VERSION ""

NS_ :

BS_:

BU_: GW HC AVP IDC_L3 LMU PIS RRR SRR_L SRR_R Tester RSDS_L RSDS_R FR IFC AVP_HAP_PAS CR_L CR_R IFC_IDC_L2 IDC_L2 FR_IDC_L2 AVP_HAP HAP HAP_PAS IDC_L2_IDC_L3 PAS

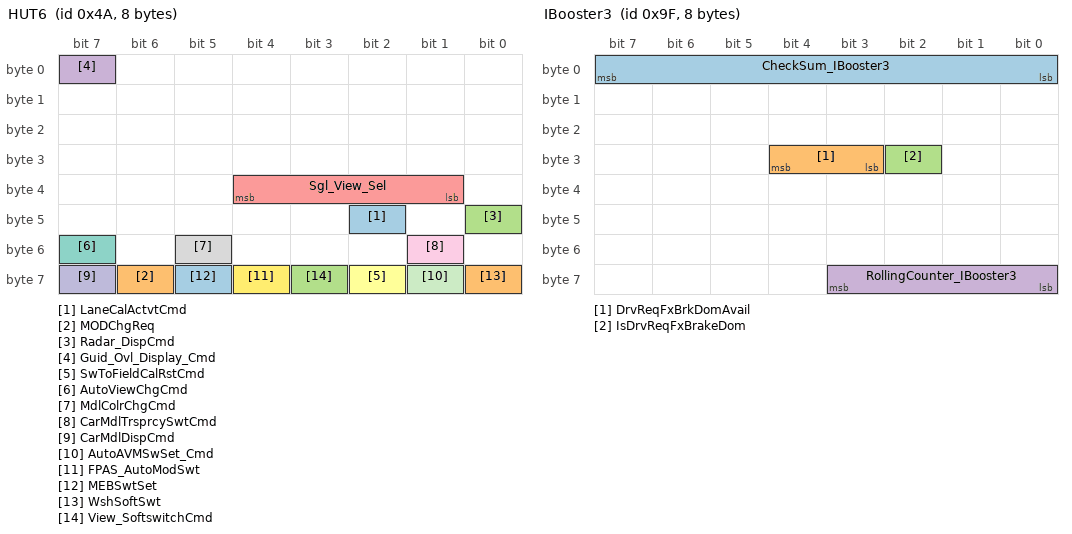
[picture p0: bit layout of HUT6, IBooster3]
BO_ 74 HUT6: 8 GW
 SG_ LaneCalActvtCmd : 42|1@0+ (1,0) [0|1] ""  AVP,HAP,PAS
 SG_ MODChgReq : 62|1@0+ (1,0) [0|1] ""  AVP,HAP,PAS
 SG_ Radar_DispCmd : 40|1@0+ (1,0) [0|1] ""  AVP,HAP,PAS
 SG_ Guid_Ovl_Display_Cmd : 7|1@0+ (1,0) [0|1] ""  AVP,HAP,PAS
 SG_ Sgl_View_Sel : 36|4@0+ (1,0) [0|15] ""  AVP,HAP,PAS
 SG_ SwToFieldCalRstCmd : 58|1@0+ (1,0) [0|1] ""  AVP,HAP,PAS
 SG_ AutoViewChgCmd : 55|1@0+ (1,0) [0|1] ""  AVP,HAP,PAS
 SG_ MdlColrChgCmd : 53|1@0+ (1,0) [0|1] ""  AVP,HAP,PAS
 SG_ CarMdlTrsprcySwtCmd : 49|1@0+ (1,0) [0|1] ""  AVP,HAP,PAS
 SG_ CarMdlDispCmd : 63|1@0+ (1,0) [0|1] ""  AVP,HAP,PAS
 SG_ AutoAVMSwSet_Cmd : 57|1@0+ (1,0) [0|1] ""  AVP,HAP,PAS
 SG_ FPAS_AutoModSwt : 60|1@0+ (1,0) [0|1] ""  AVP,HAP,PAS
 SG_ MEBSwtSet : 61|1@0+ (1,0) [0|1] ""  AVP,HAP,PAS
 SG_ WshSoftSwt : 56|1@0+ (1,0) [0|1] ""  AVP,HAP,PAS
 SG_ View_SoftswitchCmd : 59|1@0+ (1,0) [0|1] ""  AVP,HAP,PAS

BO_ 96 HCU_FD1: 64 GW
 SG_ Checksum_HCU_PT1 : 71|8@0+ (1,0) [0|255] ""  IFC,FR,IDC_L2,IDC_L3
 SG_ HCU_BrkPedalSts : 87|2@0+ (1,0) [0|3] ""  IFC,AVP,HAP,IDC_L2,IDC_L3
 SG_ HCU_BrkPedalStsValid : 84|1@0+ (1,0) [0|1] ""  IFC,AVP,HAP,IDC_L2,IDC_L3
 SG_ HCU_AccelPedalPosn_Diag : 79|8@0+ (0.3937,0) [0|100.395] "%"  IFC,FR,RSDS_R,RSDS_L,AVP,HAP,PAS,CR_L,CR_R,IDC_L2,IDC_L3
 SG_ HCU_AccelPedalPosn_DiagValid : 85|1@0+ (1,0) [0|1] ""  FR,RSDS_R,RSDS_L,AVP,HAP,PAS,CR_L,CR_R,IDC_L2,IDC_L3
 SG_ ActWheelTrqDmd : 83|12@0+ (5,-6000) [-6000|14475] "Nm"  FR,IDC_L2,IDC_L3
 SG_ RollingCounter_HCU_PT1 : 123|4@0+ (1,0) [0|15] ""  IFC,FR,IDC_L2,IDC_L3
 SG_ Checksum_HCU_PT9 : 135|8@0+ (1,0) [0|255] ""  FR,IDC_L2,IDC_L3
 SG_ MaxPsblWheelTrq : 143|10@0+ (20,-6000) [-6000|14460] "Nm"  FR,IDC_L2,IDC_L3
 SG_ TotWheelTrq : 147|12@0+ (5,-6000) [-6000|14475] "Nm"  FR,AVP,HAP,IDC_L2,IDC_L3
 SG_ TotWheelTrqVld : 171|1@0+ (1,0) [0|1] ""  IFC,FR,IDC_L2,IDC_L3
 SG_ MinPsblWheelTrq : 167|10@0+ (20,-6000) [-6000|14460] "Nm"  FR,IDC_L2,IDC_L3
 SG_ HCU_ACCInterface : 170|1@0+ (1,0) [0|1] ""  FR,IDC_L2
 SG_ RollingCounter_HCU_PT9 : 187|4@0+ (1,0) [0|15] ""  FR,IDC_L2,IDC_L3
 SG_ HCU_PowertrainSts : 303|5@0+ (1,0) [0|31] ""  IFC,FR,RSDS_R,RSDS_L,AVP,HAP,PAS,CR_L,CR_R,IDC_L2,IDC_L3
 SG_ HCU_HWPInterface : 337|1@0+ (1,0) [0|1] ""  IDC_L3
 SG_ HCU_RespHWP : 336|1@0+ (1,0) [0|1] ""  IDC_L3
 SG_ FreshnessValue_HCU_FD1 : 455|16@0+ (1,0) [0|65535] ""  FR,AVP,HAP,IDC_L2,IDC_L3
 SG_ MAC_Check_HCU_FD1 : 471|48@0+ (1,0) [0|281474976710655] ""  FR,AVP,HAP,IDC_L2,IDC_L3

BO_ 121 ECM_FD1: 64 GW
 SG_ FreshnessValue_ECM_FD1 : 455|16@0+ (1,0) [0|65535] ""  FR,AVP,HAP,IDC_L2,IDC_L3
 SG_ MAC_Check_ECM_FD1 : 471|48@0+ (1,0) [0|281474976710655] ""  FR,AVP,HAP,IDC_L2,IDC_L3

BO_ 159 IBooster3: 8 GW
 SG_ CheckSum_IBooster3 : 7|8@0+ (1,0) [0|255] ""  IDC_L2,IDC_L3
 SG_ DrvReqFxBrkDomAvail : 28|2@0+ (1,0) [0|2] ""  IDC_L2,IDC_L3
 SG_ IsDrvReqFxBrakeDom : 26|1@0+ (1,0) [0|1] ""  IDC_L2,IDC_L3
 SG_ RollingCounter_IBooster3 : 59|4@0+ (1,0) [0|15] ""  IDC_L2,IDC_L3

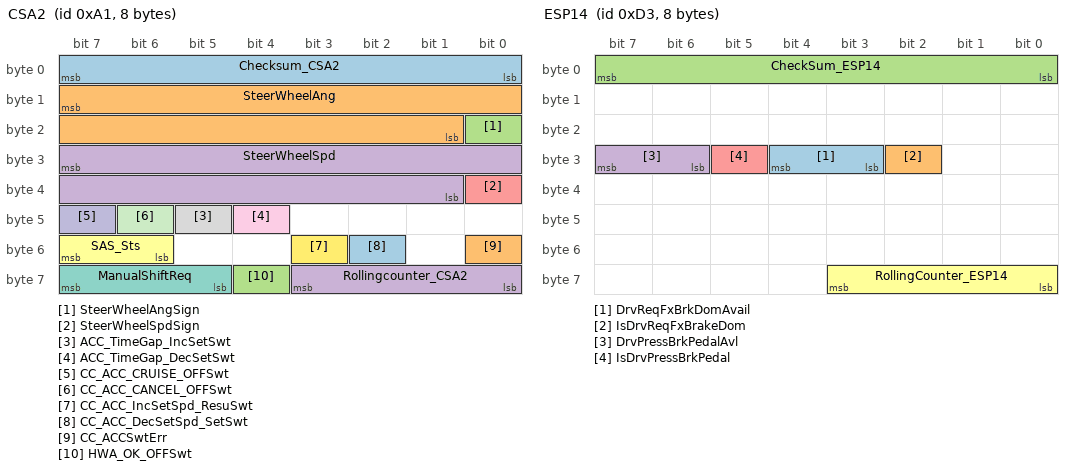
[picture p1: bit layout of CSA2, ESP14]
BO_ 161 CSA2: 8 GW
 SG_ Checksum_CSA2 : 7|8@0+ (1,0) [0|255] ""  IFC,FR,RSDS_R,RSDS_L,AVP,HAP,PAS,CR_L,CR_R,IDC_L2,IDC_L3,LMU
 SG_ SteerWheelAng : 15|15@0+ (0.1,0) [0|780] "deg"  IFC,HC,FR,RSDS_R,RSDS_L,AVP,HAP,PAS,CR_L,CR_R,IDC_L2,IDC_L3,LMU
 SG_ SteerWheelAngSign : 16|1@0+ (1,0) [0|1] ""  IFC,HC,FR,RSDS_R,RSDS_L,AVP,HAP,PAS,CR_L,CR_R,IDC_L2,IDC_L3,LMU
 SG_ SteerWheelSpd : 31|15@0+ (0.1,0) [0|1016] "deg/s"  IFC,FR,RSDS_R,RSDS_L,AVP,HAP,PAS,CR_L,CR_R,IDC_L2,IDC_L3,LMU
 SG_ SteerWheelSpdSign : 32|1@0+ (1,0) [0|1] ""  IFC,FR,RSDS_R,RSDS_L,AVP,HAP,PAS,CR_L,CR_R,IDC_L2,IDC_L3,LMU
 SG_ SAS_Sts : 55|2@0+ (1,0) [0|3] ""  IFC,FR,RSDS_R,RSDS_L,AVP,HAP,PAS,CR_L,CR_R,IDC_L2,IDC_L3
 SG_ ManualShiftReq : 63|3@0+ (1,0) [0|7] ""  IDC_L3
 SG_ ACC_TimeGap_IncSetSwt : 45|1@0+ (1,0) [0|1] ""  FR,IDC_L2
 SG_ ACC_TimeGap_DecSetSwt : 44|1@0+ (1,0) [0|1] ""  FR,IDC_L2
 SG_ CC_ACC_CRUISE_OFFSwt : 47|1@0+ (1,0) [0|1] ""  FR,IDC_L2
 SG_ CC_ACC_CANCEL_OFFSwt : 46|1@0+ (1,0) [0|1] ""  FR,IDC_L2
 SG_ CC_ACC_IncSetSpd_ResuSwt : 51|1@0+ (1,0) [0|1] ""  FR,IDC_L2,IDC_L3
 SG_ CC_ACC_DecSetSpd_SetSwt : 50|1@0+ (1,0) [0|1] ""  FR,IDC_L2,IDC_L3
 SG_ CC_ACCSwtErr : 48|1@0+ (1,0) [0|1] ""  FR,IDC_L2
 SG_ HWA_OK_OFFSwt : 60|1@0+ (1,0) [0|1] ""  FR,IDC_L2,IDC_L3
 SG_ Rollingcounter_CSA2 : 59|4@0+ (1,0) [0|15] ""  IFC,FR,RSDS_R,RSDS_L,AVP,HAP,PAS,CR_L,CR_R,IDC_L2,IDC_L3,LMU

BO_ 211 ESP14: 8 GW
 SG_ DrvReqFxBrkDomAvail : 28|2@0+ (1,0) [0|2] ""  IDC_L2,IDC_L3
 SG_ IsDrvReqFxBrakeDom : 26|1@0+ (1,0) [0|1] ""  IDC_L2,IDC_L3
 SG_ CheckSum_ESP14 : 7|8@0+ (1,0) [0|255] ""  IDC_L2,IDC_L3
 SG_ DrvPressBrkPedalAvl : 31|2@0+ (1,0) [0|2] ""  IDC_L2,IDC_L3
 SG_ IsDrvPressBrkPedal : 29|1@0+ (1,0) [0|1] ""  IDC_L2,IDC_L3
 SG_ RollingCounter_ESP14 : 59|4@0+ (1,0) [0|15] ""  IDC_L2,IDC_L3

BO_ 259 ECM_FD2: 64 GW
 SG_ EngState_PHEV : 351|3@0+ (1,0) [0|7] ""  FR,RSDS_R,RSDS_L,CR_L,CR_R,IDC_L2,IDC_L3
 SG_ FreshnessValue_ECM_FD2 : 455|16@0+ (1,0) [0|65535] ""  FR,IDC_L2,IDC_L3
 SG_ MAC_Check_ECM_FD2 : 471|48@0+ (1,0) [0|281474976710655] ""  FR,IDC_L2,IDC_L3

BO_ 273 ECM1: 8 GW
 SG_ EngSpd : 47|16@0+ (0.125,0) [0|8191.875] "rpm"  IFC,HC,FR,RSDS_R,RSDS_L,AVP,HAP,PAS,CR_L,CR_R,IDC_L2,IDC_L3,LMU
 SG_ EngSpdVldty : 63|2@0+ (1,0) [0|2] ""  IFC,HC,FR,RSDS_R,RSDS_L,AVP,HAP,PAS,CR_L,CR_R,IDC_L2,IDC_L3,LMU

BO_ 288 IBooster_FD2: 64 GW
 SG_ IB_BrkPedalAppld : 11|1@0+ (1,0) [0|1] ""  FR,RSDS_R,RSDS_L,AVP,HAP,CR_L,CR_R,IDC_L2
 SG_ IB_BrkPedalAppldVld : 10|2@0+ (1,0) [0|3] ""  FR,RSDS_R,RSDS_L,AVP,HAP,CR_L,CR_R,IDC_L2
 SG_ CheckSum_ABS1 : 135|8@0+ (1,0) [0|255] ""  IDC_L2,IDC_L3
 SG_ FRWheelDriveDirection : 159|2@0+ (1,0) [0|3] ""  IDC_L2,IDC_L3
 SG_ FRWheelSpdVld : 157|1@0+ (1,0) [0|1] ""  IDC_L2,IDC_L3
 SG_ FRWheelSpd : 156|13@0+ (0.05625,0) [0|299.98125] "km/h"  IDC_L2,IDC_L3
 SG_ WssFLEdgesSum : 175|8@0+ (1,0) [0|255] ""  IDC_L2,IDC_L3
 SG_ WssFREdgesSum : 183|8@0+ (1,0) [0|255] ""  IDC_L2,IDC_L3
 SG_ WssFLEdgesSumVld : 191|1@0+ (1,0) [0|1] ""  IDC_L2,IDC_L3
 SG_ WssFREdgesSumVld : 190|1@0+ (1,0) [0|1] ""  IDC_L2,IDC_L3
 SG_ RollingCounter_ABS1 : 187|4@0+ (1,0) [0|15] ""  IDC_L2,IDC_L3
 SG_ CheckSum_ABS3 : 199|8@0+ (1,0) [0|255] ""  IDC_L2,IDC_L3
 SG_ RollingCounter_ABS3 : 251|4@0+ (1,0) [0|15] ""  IDC_L2,IDC_L3
 SG_ CheckSum_IBooster_FD2_5 : 263|8@0+ (1,0) [0|255] ""  IDC_L2,IDC_L3
 SG_ VLC_IntTartAccel : 279|12@0+ (0.0125,-16) [-16|16] ""  IDC_L2,IDC_L3
 SG_ L3VLCADactive : 271|1@0+ (1,0) [0|1] ""  IDC_L2,IDC_L3
 SG_ L3mainVMCavailiable : 270|2@0+ (1,0) [0|3] ""  IDC_L2,IDC_L3
 SG_ RollingCounter_Booster_FD2_5 : 315|4@0+ (1,0) [0|15] ""  IDC_L2,IDC_L3
 SG_ CheckSum_ABS2 : 327|8@0+ (1,0) [0|255] ""  IDC_L2,IDC_L3
 SG_ WssRREdgesSum : 367|8@0+ (1,0) [0|255] ""  IDC_L2,IDC_L3
 SG_ WssRLEdgesSum : 375|8@0+ (1,0) [0|255] ""  IDC_L2,IDC_L3
 SG_ WssRLEdgesSumVld : 383|1@0+ (1,0) [0|1] ""  IDC_L2,IDC_L3
 SG_ WssRREdgesSumVld : 382|1@0+ (1,0) [0|1] ""  IDC_L2,IDC_L3
 SG_ RollingCounter_ABS2 : 379|4@0+ (1,0) [0|15] ""  IDC_L2,IDC_L3
 SG_ FreshnessValue_IBooster_FD2 : 455|16@0+ (1,0) [0|65535] ""  IDC_L3
 SG_ MAC_Check_IBooster_FD2 : 471|48@0+ (1,0) [0|281474976710655] ""  IDC_L3

BO_ 299 IFC_FD1: 64 IFC_IDC_L2
 SG_ Checksum_IFC1 : 71|8@0+ (1,0) [0|255] ""  GW
 SG_ IFCTrqOvlCmdProtnValue : 79|14@0+ (1,0) [0|16383] ""  GW
 SG_ IFCTrqOvlCmdReqValue : 103|11@0+ (0.01,-10.23) [-10.23|10.24] "Nm"  GW
 SG_ IFCFuncTrqCmdReqFlag : 127|3@0+ (1,0) [0|7] ""  GW
 SG_ IFCVibrationWarning : 105|2@0+ (1,0) [0|3] ""  GW
 SG_ RollingCounter_IFC1 : 123|4@0+ (1,0) [0|15] ""  GW
 SG_ Checksum_IFC2 : 135|8@0+ (1,0) [0|255] ""  GW
 SG_ IFCAngCmdReqValue : 143|14@0+ (0.1,-780) [-780|780] "°"  GW
 SG_ IFCAngCmdReqProtnValue : 159|14@0+ (1,0) [0|16383] "" Vector__XXX
 SG_ IFCFuncAngCmdReqFlag : 175|3@0+ (1,0) [0|7] ""  GW
 SG_ RollingCounter_IFC2 : 187|4@0+ (1,0) [0|15] ""  GW

BO_ 303 HCU_FD3: 64 GW
 SG_ Checksum_HCU_PT5 : 71|8@0+ (1,0) [0|255] ""  FR,IDC_L2,IDC_L3
 SG_ HCU_DrvMod : 79|4@0+ (1,0) [0|15] ""  FR,AVP,HAP,IDC_L2,IDC_L3
 SG_ HCU_PTDrvMod : 75|3@0+ (1,0) [0|7] ""  FR,IDC_L2,IDC_L3
 SG_ DrvTrqReqOvld : 87|2@0+ (1,0) [0|3] ""  FR,IDC_L2,IDC_L3
 SG_ RollingCounter_HCU_PT5 : 123|4@0+ (1,0) [0|15] ""  FR,IDC_L2,IDC_L3
 SG_ HCU_GearSts : 164|4@0+ (1,0) [0|15] ""  IFC,HC,FR,RSDS_R,RSDS_L,AVP,HAP,PAS,CR_L,CR_R,IDC_L2
 SG_ HCU_APS_Available : 188|1@0+ (1,0) [0|1] ""  AVP,HAP
 SG_ HCU_FltLvl : 158|2@0+ (1,0) [0|2] ""  IDC_L2,IDC_L3
 SG_ HCU_VehSpdLimit : 215|8@0+ (2,0) [0|510] "km/h"  IDC_L3
 SG_ FreshnessValue_HCU_FD3 : 455|16@0+ (1,0) [0|65535] ""  FR,IDC_L2,IDC_L3
 SG_ MAC_Check_HCU_FD3 : 471|48@0+ (1,0) [0|281474976710655] ""  FR,IDC_L2,IDC_L3

BO_ 311 ESP_FD2: 64 GW
 SG_ VehStandstill : 78|2@0+ (1,0) [0|3] ""  FR,RSDS_R,RSDS_L,AVP,HAP,PAS,CR_L,CR_R,IDC_L2,IDC_L3
 SG_ EngTrqReq : 231|16@0+ (1,-3000) [-3000|5000] "Nm"  AVP,HAP
 SG_ CheckSum_ABS3 : 327|8@0+ (1,0) [0|255] ""  IFC,FR,RSDS_R,RSDS_L,AVP,HAP,PAS,CR_L,CR_R,IDC_L2,IDC_L3,PIS,LMU
 SG_ VehSpdVld : 333|1@0+ (1,0) [0|1] ""  IFC,HC,FR,RSDS_R,RSDS_L,AVP,HAP,PAS,CR_L,CR_R,IDC_L2,IDC_L3,PIS,LMU
 SG_ VehSpd : 332|13@0+ (0.05625,0) [0|299.98125] "kph"  IFC,HC,FR,RSDS_R,RSDS_L,AVP,HAP,PAS,CR_L,CR_R,IDC_L2,IDC_L3,PIS,LMU
 SG_ RollingCounter_ABS3 : 379|4@0+ (1,0) [0|15] ""  IFC,FR,RSDS_R,RSDS_L,AVP,HAP,PAS,CR_L,CR_R,IDC_L2,IDC_L3,PIS,LMU
 SG_ CheckSum_ESP_FD2_1 : 7|8@0+ (1,0) [0|255] ""  FR,IDC_L2,IDC_L3
 SG_ L12VLCADactive : 63|1@0+ (1,0) [0|1] ""  FR,IDC_L2,IDC_L3
 SG_ L12mainVMCavailiable : 62|1@0+ (1,0) [0|1] ""  FR,IDC_L2,IDC_L3
 SG_ RollingCounter_ESP_FD2_1 : 59|4@0+ (1,0) [0|15] ""  FR,IDC_L2,IDC_L3
 SG_ CheckSum_ESP2 : 71|8@0+ (1,0) [0|255] ""  FR,AVP,HAP,PAS,IDC_L2,IDC_L3
 SG_ CDPActv : 103|1@0+ (1,0) [0|1] ""  IDC_L2,IDC_L3
 SG_ ESP_DiagActv : 73|1@0+ (1,0) [0|1] ""  IFC,FR,RSDS_R,RSDS_L,HAP,CR_L,CR_R,IDC_L2,IDC_L3
 SG_ BrkDskOvrheatd : 75|1@0+ (1,0) [0|1] ""  FR,CR_L,CR_R,IDC_L2,IDC_L3
 SG_ NoBrkForce : 76|1@0+ (1,0) [0|1] ""  FR,RSDS_R,RSDS_L,CR_L,CR_R,IDC_L2,IDC_L3
 SG_ AEBIBActv : 81|1@0+ (1,0) [0|1] ""  FR,RSDS_R,RSDS_L,HAP,PAS,CR_L,CR_R,IDC_L2,IDC_L3
 SG_ AEBBAActv : 82|1@0+ (1,0) [0|1] ""  FR,RSDS_R,RSDS_L,HAP,PAS,CR_L,CR_R,IDC_L2,IDC_L3
 SG_ AEBAvailable : 83|1@0+ (1,0) [0|1] ""  FR,CR_L,CR_R,IDC_L2,IDC_L3
 SG_ ABPAvailable : 84|1@0+ (1,0) [0|1] ""  FR,CR_L,CR_R,IDC_L2,IDC_L3
 SG_ ABPActv : 85|1@0+ (1,0) [0|1] ""  FR,CR_L,CR_R,IDC_L2,IDC_L3
 SG_ ABAavailable : 86|1@0+ (1,0) [0|1] ""  FR,CR_L,CR_R,IDC_L2,IDC_L3
 SG_ ABAactv : 87|1@0+ (1,0) [0|1] ""  FR,CR_L,CR_R,IDC_L2,IDC_L3
 SG_ HDCCtrl : 91|2@0+ (1,0) [0|2] ""  FR,RSDS_R,RSDS_L,CR_L,CR_R,IDC_L2,IDC_L3
 SG_ CDDActv : 92|1@0+ (1,0) [0|1] ""  FR,IDC_L2,IDC_L3
 SG_ CDDAvailable : 93|1@0+ (1,0) [0|1] ""  FR,IDC_L2,IDC_L3
 SG_ AWBAvailable : 94|1@0+ (1,0) [0|1] ""  FR,IDC_L2,IDC_L3
 SG_ AWBActv : 95|1@0+ (1,0) [0|1] ""  FR,IDC_L2,IDC_L3
 SG_ AVHErrSts : 99|2@0+ (1,0) [0|3] ""  HAP,PAS
 SG_ AVHSts : 101|2@0+ (1,0) [0|2] ""  FR,HAP,PAS,IDC_L2,IDC_L3
 SG_ CTABrkAvailable : 74|1@0+ (1,0) [0|1] ""  RSDS_R,RSDS_L
 SG_ RollingCounter_ESP2 : 123|4@0+ (1,0) [0|15] ""  FR,AVP,HAP,PAS,IDC_L2,IDC_L3
 SG_ CheckSum_ESP1 : 135|8@0+ (1,0) [0|255] ""  IFC,FR,RSDS_R,RSDS_L,AVP,HAP,CR_L,CR_R,IDC_L2,IDC_L3
 SG_ ESPFuncOffSts : 140|1@0+ (1,0) [0|1] ""  IFC,FR,RSDS_R,RSDS_L,AVP,HAP,CR_L,CR_R,IDC_L2,IDC_L3
 SG_ ESPBrkLmpCtrl : 142|1@0+ (1,0) [0|1] ""  FR,IDC_L2,IDC_L3
 SG_ ESPFailSts : 143|1@0+ (1,0) [0|1] ""  IFC,FR,RSDS_R,RSDS_L,HAP,CR_L,CR_R,IDC_L2,IDC_L3
 SG_ ESP_MasterCylBrkPressVld : 144|1@0+ (1,0) [0|1] ""  IFC,FR,RSDS_R,RSDS_L,AVP,HAP,CR_L,CR_R,IDC_L2,IDC_L3
 SG_ MSRActv : 149|1@0+ (1,0) [0|1] ""  IFC,FR,RSDS_R,RSDS_L,CR_L,CR_R,IDC_L2,IDC_L3
 SG_ VDCActv : 148|1@0+ (1,0) [0|1] ""  IFC,FR,RSDS_R,RSDS_L,AVP,HAP,CR_L,CR_R,IDC_L2,IDC_L3
 SG_ PTCActv : 150|1@0+ (1,0) [0|1] ""  IFC,FR,RSDS_R,RSDS_L,AVP,HAP,CR_L,CR_R,IDC_L2,IDC_L3
 SG_ BTCActv : 151|1@0+ (1,0) [0|1] ""  IFC,FR,RSDS_R,RSDS_L,AVP,HAP,CR_L,CR_R,IDC_L2,IDC_L3
 SG_ ESP_MasterCylBrkPress : 159|16@0+ (0.03125,-42.5) [-42.5|425] "bar"  IFC,FR,RSDS_R,RSDS_L,AVP,HAP,CR_L,CR_R,IDC_L2,IDC_L3
 SG_ MSRActv_RA : 174|1@0+ (1,0) [0|1] ""  IFC,FR,RSDS_R,RSDS_L,CR_L,CR_R,IDC_L2,IDC_L3
 SG_ PTCActv_RA : 136|1@0+ (1,0) [0|1] ""  IFC,FR,RSDS_R,RSDS_L,CR_L,CR_R,IDC_L2,IDC_L3
 SG_ BTCActv_RA : 137|1@0+ (1,0) [0|1] ""  IFC,FR,RSDS_R,RSDS_L,CR_L,CR_R,IDC_L2,IDC_L3
 SG_ RollingCounter_ESP1 : 187|4@0+ (1,0) [0|15] ""  IFC,FR,RSDS_R,RSDS_L,AVP,HAP,CR_L,CR_R,IDC_L2,IDC_L3
 SG_ CheckSum_ESP7 : 199|8@0+ (1,0) [0|255] ""  AVP,HAP,PAS
 SG_ ESP_MEBBrkAvail : 209|1@0+ (1,0) [0|1] ""  HAP,PAS
 SG_ LgtCtrlrAvail : 255|3@0+ (1,0) [0|7] ""  HAP
 SG_ LgtCtrlrFailr : 220|3@0+ (1,0) [0|7] ""  HAP
 SG_ LgtCtrlrSts : 223|3@0+ (1,0) [0|7] ""  HAP
 SG_ FourWhlsBrkTrq : 207|14@0+ (1,0) [0|16383] ""  AVP,HAP,PAS
 SG_ APS_EngTrqReqEna : 247|1@0+ (1,0) [0|1] ""  AVP,HAP
 SG_ RollingCounter_ESP7 : 251|4@0+ (1,0) [0|15] ""  HAP,PAS
 SG_ ABSFailSts : 335|1@0+ (1,0) [0|1] ""  IFC,FR,AVP,HAP,PAS,IDC_L2,IDC_L3
 SG_ EBDFailSts : 334|1@0+ (1,0) [0|1] ""  IFC,FR,AVP,HAP,IDC_L2,IDC_L3
 SG_ EBDActv : 351|1@0+ (1,0) [0|1] ""  AVP,HAP
 SG_ ABSActv : 347|1@0+ (1,0) [0|1] ""  IFC,FR,RSDS_R,RSDS_L,AVP,HAP,PAS,CR_L,CR_R,IDC_L2,IDC_L3
 SG_ FreshnessValue_ESP_FD2 : 455|16@0+ (1,0) [0|65535] ""  AVP,HAP,IDC_L2,IDC_L3
 SG_ MAC_Check_ESP_FD2 : 471|48@0+ (1,0) [0|281474976710655] ""  AVP,HAP,IDC_L2,IDC_L3

BO_ 315 ESP_FD3: 64 GW
 SG_ L3VLCADactive : 422|1@0+ (1,0) [0|1] ""  IDC_L2,IDC_L3
 SG_ L3mainVMCavailiable : 421|2@0+ (1,0) [0|3] ""  IDC_L2,IDC_L3
 SG_ CheckSum_ABS1 : 7|8@0+ (1,0) [0|255] ""  IFC,FR,RSDS_R,RSDS_L,AVP,HAP,PAS,CR_L,CR_R,IDC_L2,IDC_L3,LMU
 SG_ FLWheelDriveDirection : 15|2@0+ (1,0) [0|3] ""  IFC,FR,RSDS_R,RSDS_L,AVP,HAP,PAS,CR_L,CR_R,IDC_L2,IDC_L3
 SG_ FLWheelSpdVld : 13|1@0+ (1,0) [0|1] ""  IFC,FR,RSDS_R,RSDS_L,AVP,HAP,PAS,CR_L,CR_R,IDC_L2,IDC_L3,LMU
 SG_ FLWheelSpd : 12|13@0+ (0.05625,0) [0|299.98125] "km/h"  IFC,FR,RSDS_R,RSDS_L,AVP,HAP,PAS,CR_L,CR_R,IDC_L2,IDC_L3,LMU
 SG_ FRWheelDriveDirection : 31|2@0+ (1,0) [0|3] ""  IFC,FR,RSDS_R,RSDS_L,AVP,HAP,PAS,CR_L,CR_R,IDC_L2,IDC_L3
 SG_ FRWheelSpdVld : 29|1@0+ (1,0) [0|1] ""  IFC,FR,RSDS_R,RSDS_L,AVP,HAP,PAS,CR_L,CR_R,IDC_L2,IDC_L3,LMU
 SG_ FRWheelSpd : 28|13@0+ (0.05625,0) [0|299.98125] "km/h"  IFC,FR,RSDS_R,RSDS_L,AVP,HAP,PAS,CR_L,CR_R,IDC_L2,IDC_L3,LMU
 SG_ WssFLEdgesSum : 47|8@0+ (1,0) [0|255] ""  FR,AVP,HAP,PAS,IDC_L2,IDC_L3,LMU
 SG_ WssFREdgesSum : 55|8@0+ (1,0) [0|255] ""  FR,AVP,HAP,PAS,IDC_L2,IDC_L3,LMU
 SG_ WssFLEdgesSumVld : 63|1@0+ (1,0) [0|1] ""  FR,AVP,HAP,PAS,IDC_L2,IDC_L3,LMU
 SG_ WssFREdgesSumVld : 62|1@0+ (1,0) [0|1] ""  FR,AVP,HAP,PAS,IDC_L2,IDC_L3,LMU
 SG_ RollingCounter_ABS1 : 59|4@0+ (1,0) [0|15] ""  IFC,FR,RSDS_R,RSDS_L,AVP,HAP,PAS,CR_L,CR_R,IDC_L2,IDC_L3,LMU
 SG_ CheckSum_ABS2 : 327|8@0+ (1,0) [0|255] ""  IFC,FR,RSDS_R,RSDS_L,AVP,HAP,PAS,CR_L,CR_R,IDC_L2,IDC_L3,LMU
 SG_ RLWheelDriveDirection : 335|2@0+ (1,0) [0|3] ""  IFC,FR,RSDS_R,RSDS_L,AVP,HAP,PAS,CR_L,CR_R,IDC_L2,IDC_L3
 SG_ RLWheelSpdVld : 333|1@0+ (1,0) [0|1] ""  IFC,FR,RSDS_R,RSDS_L,AVP,HAP,PAS,CR_L,CR_R,IDC_L2,IDC_L3,LMU
 SG_ RLWheelSpd : 332|13@0+ (0.05625,0) [0|299.98125] "km/h"  IFC,FR,RSDS_R,RSDS_L,AVP,HAP,PAS,CR_L,CR_R,IDC_L2,IDC_L3,LMU
 SG_ RRWheelDriveDirection : 351|2@0+ (1,0) [0|3] ""  IFC,FR,RSDS_R,RSDS_L,AVP,HAP,PAS,CR_L,CR_R,IDC_L2,IDC_L3
 SG_ RRWheelSpdVld : 349|1@0+ (1,0) [0|1] ""  IFC,FR,RSDS_R,RSDS_L,AVP,HAP,PAS,CR_L,CR_R,IDC_L2,IDC_L3,LMU
 SG_ RRWheelSpd : 348|13@0+ (0.05625,0) [0|299.98125] "km/h"  IFC,FR,RSDS_R,RSDS_L,AVP,HAP,PAS,CR_L,CR_R,IDC_L2,IDC_L3,LMU
 SG_ WssRREdgesSum : 367|8@0+ (1,0) [0|255] ""  FR,AVP,HAP,PAS,IDC_L2,IDC_L3,LMU
 SG_ WssRLEdgesSum : 375|8@0+ (1,0) [0|255] ""  FR,AVP,HAP,PAS,IDC_L2,IDC_L3,LMU
 SG_ WssRLEdgesSumVld : 383|1@0+ (1,0) [0|1] ""  FR,AVP,HAP,PAS,IDC_L2,IDC_L3,LMU
 SG_ WssRREdgesSumVld : 382|1@0+ (1,0) [0|1] ""  FR,AVP,HAP,PAS,IDC_L2,IDC_L3,LMU
 SG_ RollingCounter_ABS2 : 379|4@0+ (1,0) [0|15] ""  IFC,FR,RSDS_R,RSDS_L,AVP,HAP,PAS,CR_L,CR_R,IDC_L2,IDC_L3,LMU
 SG_ VLC_IntTartAccel : 431|12@0+ (0.0125,-16) [-16|16] ""  IDC_L2,IDC_L3
 SG_ CheckSum_EPB1 : 71|8@0+ (1,0) [0|255] ""  FR,AVP,HAP,PAS,IDC_L2,IDC_L3
 SG_ ESP_DSTSts : 116|3@0+ (1,0) [0|7] ""  IDC_L2,IDC_L3
 SG_ EPB_SwtPosnVld : 80|1@0+ (1,0) [0|1] ""  FR,AVP,HAP,PAS,IDC_L2,IDC_L3
 SG_ EPBErrSts : 91|2@0+ (1,0) [0|3] ""  FR,RSDS_R,RSDS_L,AVP,HAP,PAS,CR_L,CR_R,IDC_L2,IDC_L3
 SG_ EPBSts : 93|2@0+ (1,0) [0|3] ""  FR,RSDS_R,RSDS_L,AVP,HAP,PAS,CR_L,CR_R,IDC_L2,IDC_L3
 SG_ EPB_SwtPosn : 95|2@0+ (1,0) [0|3] ""  FR,AVP,HAP,PAS,IDC_L2,IDC_L3
 SG_ RollingCounter_EPB1 : 123|4@0+ (1,0) [0|15] ""  FR,AVP,HAP,PAS,IDC_L2,IDC_L3
 SG_ CheckSum_ESP_FD3_7 : 391|8@0+ (1,0) [0|255] ""  AVP,HAP,IDC_L2,IDC_L3
 SG_ VLC_ESP_FuelCutOffPrevention : 419|1@0+ (1,0) [0|1] ""  IDC_L2,IDC_L3
 SG_ VLC_ESP_State : 418|2@0+ (1,0) [0|3] ""  IDC_L2,IDC_L3
 SG_ LSMGearRequest : 409|2@0+ (1,0) [0|2] ""  IDC_L2,IDC_L3
 SG_ ParkPawlRequest : 423|1@0+ (1,0) [0|1] ""  IDC_L2,IDC_L3
 SG_ LSMPosLongACapbl : 407|2@0+ (1,0) [0|3] ""  AVP
 SG_ LSMSubMTReqAvailable : 392|1@0+ (1,0) [0|1] ""  AVP
 SG_ LSMSubMTLevelEcho : 405|2@0+ (1,0) [0|3] ""  AVP
 SG_ LSMSubMTLongEcho : 403|2@0+ (1,0) [0|3] ""  AVP
 SG_ LSMSubMTReqEcho : 401|2@0+ (1,0) [0|2] ""  AVP
 SG_ Lsm12ComfortAvl : 415|2@0+ (1,0) [0|3] ""  AVP
 SG_ Lsm12EmergencyAvl : 413|2@0+ (1,0) [0|3] ""  AVP
 SG_ Lsm23Avl : 411|2@0+ (1,0) [0|3] ""  AVP
 SG_ RollingCounter_ESP_FD3_7 : 443|4@0+ (1,0) [0|15] ""  AVP,HAP,IDC_L2,IDC_L3
 SG_ FreshnessValue_ESP_FD3 : 455|16@0+ (1,0) [0|65535] ""  AVP,HAP,IDC_L2,IDC_L3
 SG_ MAC_Check_ESP_FD3 : 471|48@0+ (1,0) [0|281474976710655] ""  AVP,HAP,IDC_L2,IDC_L3

BO_ 323 ACC_FD1: 64 IDC_L2
 SG_ Checksum_ACC11 : 7|8@0+ (1,0) [0|255] ""  GW
 SG_ HWP_AccelOvrdActnReq_L2 : 49|1@0+ (1,0) [0|1] ""  GW
 SG_ HWP_SuprAvail_L2 : 50|1@0+ (1,0) [0|1] ""  GW
 SG_ HWP_MotTypeReqMode_L2 : 55|2@0+ (1,0) [0|3] ""  GW
 SG_ HWP_MotTypeReqLong_L2 : 53|2@0+ (1,0) [0|4] ""  GW
 SG_ HWP_ShutdownReq_L2 : 51|1@0+ (1,0) [0|1] ""  GW
 SG_ HWP_UpperLimit_L2 : 23|8@0+ (0.1,0) [0|12.7] ""  GW
 SG_ HWP_LowerLimit_L2 : 31|8@0+ (0.1,-12.7) [-12.7|0] ""  GW
 SG_ HWP_SecureReq_L2 : 62|1@0+ (1,0) [0|1] ""  GW
 SG_ HWP_AEBAvail : 61|1@0+ (1,0) [0|1] ""  GW
 SG_ HWP_ACCAvail : 60|1@0+ (1,0) [0|1] ""  GW
 SG_ HWP_TgtAccelCmftUpprLimVal_L2 : 39|8@0+ (0.0125,0) [0|3.125] ""  GW
 SG_ HWP_TgtAccelCmftLwrLimVal_L2 : 47|8@0+ (0.0125,0) [0|3.125] ""  GW
 SG_ HWP_UseTgtAccelCmftUpprLimVal_L2 : 63|1@0+ (1,0) [0|1] ""  GW
 SG_ RollingCounter_ACC11 : 59|4@0+ (1,0) [0|15] ""  GW
 SG_ Checksum_ACC1 : 71|8@0+ (1,0) [0|255] ""  GW
 SG_ Longctrl_VehHldReq : 79|1@0+ (1,0) [0|1] ""  GW
 SG_ Longctrl_DrvOFF_Req : 78|1@0+ (1,0) [0|1] ""  GW
 SG_ Longctrl_ModSts : 77|4@0+ (1,0) [0|15] ""  GW
 SG_ Longctrl_Decel_Req : 72|1@0+ (1,0) [0|1] ""  GW
 SG_ Longctrl_DecelToStopReq : 101|1@0+ (1,0) [0|1] ""  GW
 SG_ Longctrl_ParkShiftReq : 99|2@0+ (1,0) [0|3] ""  GW
 SG_ Longctrl_Decel_ReqValue : 111|8@0+ (0.05,-7) [-7|5.75] "m/s^2"  GW
 SG_ ActualTargetSpeed : 119|8@0+ (1,0) [0|254] "km/h" Vector__XXX
 SG_ RollingCounter_ACC1 : 123|4@0+ (1,0) [0|15] ""  GW
 SG_ Checksum_ACC2 : 135|8@0+ (1,0) [0|255] ""  GW
 SG_ HWP_TgtAccel_L2 : 159|12@0+ (0.0125,-16) [-16|16] ""  GW
 SG_ IDC_L2_HADFuncCmdReqFlag : 163|3@0+ (1,0) [0|7] ""  GW
 SG_ HWP_AngCmdReqVal_L2 : 175|14@0+ (0.1,-780) [-780|780] "°"  GW
 SG_ HWP_AngCmdReqValVld_L2 : 160|1@0+ (1,0) [0|1] ""  GW
 SG_ RollingCounter_ACC2 : 187|4@0+ (1,0) [0|15] ""  GW
 SG_ ACC_CRInterface : 191|1@0+ (1,0) [0|1] ""  CR_L,CR_R
 SG_ Checksum_ACC10 : 199|8@0+ (1,0) [0|255] ""  GW
 SG_ Longctrl_HCUTrqReq : 223|16@0+ (0.5,-16384) [-16384|16383.5] "NM"  GW
 SG_ Longctrl_HCUTrqReqActive : 239|1@0+ (1,0) [0|1] ""  GW
 SG_ RollingCounter_ACC10 : 251|4@0+ (1,0) [0|15] ""  GW
 SG_ FreshnessValue_ACC_FD1 : 455|16@0+ (1,0) [0|65535] ""  GW
 SG_ MAC_Check_ACC_FD1 : 471|48@0+ (1,0) [0|281474976710655] ""  GW

BO_ 327 EPS_FD1: 64 GW
 SG_ CheckSum_EPS1 : 7|8@0+ (1,0) [0|255] ""  AVP,HAP,IDC_L2,IDC_L3
 SG_ EPS_FailSts : 13|2@0+ (1,0) [0|3] ""  IFC,IDC_L2,IDC_L3
 SG_ EPS_TrqSnsrSts : 14|1@0+ (1,0) [0|1] ""  IFC,IDC_L2,IDC_L3
 SG_ EPS_InterferDetd : 31|1@0+ (1,0) [0|1] ""  AVP,HAP,IDC_L3
 SG_ EPS_InterferDetdVld : 30|1@0+ (1,0) [0|1] ""  AVP,HAP,IDC_L3
 SG_ EPS_AvailSts : 29|2@0+ (1,0) [0|3] ""  AVP,HAP,IDC_L3
 SG_ EPS_SteerMod : 55|3@0+ (1,0) [0|7] ""  IFC,IDC_L2,IDC_L3
 SG_ EPS_DSTCtrlSts : 11|3@0+ (1,0) [0|7] ""  IDC_L2,IDC_L3
 SG_ RollingCounter_EPS1 : 59|4@0+ (1,0) [0|15] ""  AVP,HAP,IDC_L2,IDC_L3
 SG_ CheckSum_EPS2 : 71|8@0+ (1,0) [0|255] ""  IFC,IDC_L2
 SG_ EPS_LKATorqOvrlDlvd : 111|16@0+ (0.01,-15) [-15|15] "Nm"  IFC,IDC_L2,IDC_L3
 SG_ EPS_LKATorqOvrlDlvdVld : 127|1@0+ (1,0) [0|1] ""  IFC,IDC_L2,IDC_L3
 SG_ EPS_LKATrqOvlDlvdSts : 125|2@0+ (1,0) [0|3] ""  IFC,IDC_L2,IDC_L3
 SG_ EPS_DrvInpTrqVal_HighReslolution : 79|12@0+ (0.015625,-31.984375) [-31.984375|32] "Nm"  IFC,IDC_L2,IDC_L3
 SG_ EPS_DrvInpTrqVal_HighResVld : 126|1@0+ (1,0) [0|1] ""  IDC_L2,IDC_L3
 SG_ EPS_LKAAngDlvdSts : 83|2@0+ (1,0) [0|3] ""  IDC_L2
 SG_ RollingCounter_EPS2 : 123|4@0+ (1,0) [0|15] ""  IFC,IDC_L2
 SG_ CheckSum_EPS3 : 135|8@0+ (1,0) [0|255] ""  IDC_L2,IDC_L3
 SG_ EPS_HADHndShkRespSt : 190|3@0+ (1,0) [0|7] ""  IDC_L2,IDC_L3
 SG_ EPS_AvailStsforHAD : 177|2@0+ (1,0) [0|3] ""  IDC_L2,IDC_L3
 SG_ EPS_AngCmdOverRange : 191|1@0+ (1,0) [0|1] ""  IDC_L2,IDC_L3
 SG_ EPS_HADerror_Reason : 183|4@0+ (1,0) [0|15] ""  IDC_L2,IDC_L3
 SG_ EPS_SteerWheelAngVld : 178|1@0+ (1,0) [0|1] ""  IDC_L2,IDC_L3
 SG_ ElecPwrSteerCpby : 143|2@0+ (1,0) [0|2] ""  IDC_L3
 SG_ EPS_SteerWheelAng : 151|15@0+ (0.1,0) [0|780] "deg"  IDC_L2,IDC_L3
 SG_ EPS_SteerWheelAngSign : 152|1@0+ (1,0) [0|1] ""  IDC_L2,IDC_L3
 SG_ EPS_SteerWheelSpd : 167|15@0+ (0.1,0) [0|1016] "deg/s"  IDC_L2,IDC_L3
 SG_ EPS_SteerWheelSpdSign : 168|1@0+ (1,0) [0|1] ""  IDC_L2,IDC_L3
 SG_ EPS_HWPHndShkResp : 141|1@0+ (1,0) [0|1] ""  IDC_L3
 SG_ RollingCounter_EPS3 : 187|4@0+ (1,0) [0|15] ""  IDC_L2,IDC_L3
 SG_ FreshnessValue_EPS_FD1 : 455|16@0+ (1,0) [0|65535] ""  IDC_L2,IDC_L3
 SG_ MAC_Check_EPS_FD1 : 471|48@0+ (1,0) [0|281474976710655] ""  IDC_L2,IDC_L3

BO_ 344 IDC_L3_FD1: 64 IDC_L3
 SG_ Checksum_IDC_L3_1 : 7|8@0+ (1,0) [0|255] ""  GW
 SG_ HWP_ReqCtrlEPS : 55|1@0+ (1,0) [0|1] ""  GW
 SG_ HWP_ReqCtrlEPSVld : 54|1@0+ (1,0) [0|1] ""  GW
 SG_ HWP_AngCmdReqVal : 15|14@0+ (0.1,-780) [-780|780] "°"  GW
 SG_ HWP_AngCmdReqValVld : 53|1@0+ (1,0) [0|1] ""  GW
 SG_ HWP_HapcWarnReq : 52|2@0+ (1,0) [0|3] ""  GW
 SG_ HWP_TrqOvlCmdProtnValue : 17|14@0+ (1,0) [0|16383] "" Vector__XXX
 SG_ HWP_TrqOvlCmdReqValue : 35|11@0+ (0.01,-10.23) [-10.23|10.24] "Nm" Vector__XXX
 SG_ HWP_FuncTrqCmdReqFlag : 50|3@0+ (1,0) [0|7] ""  GW
 SG_ RollingCounter_IDC_L3_1 : 59|4@0+ (1,0) [0|15] ""  GW
 SG_ Checksum_IDC_L3_3 : 71|8@0+ (1,0) [0|255] "" Vector__XXX
 SG_ HWP_AccelOvrdActnReq : 110|1@0+ (1,0) [0|1] ""  GW
 SG_ HWP_WorkReq : 98|3@0+ (1,0) [0|7] ""  GW
 SG_ HWP_WorkReqVld : 111|1@0+ (1,0) [0|1] ""  GW
 SG_ HWP_TgtGearReq : 95|3@0+ (1,0) [0|7] ""  GW
 SG_ HWP_TgtGearReqVld : 92|1@0+ (1,0) [0|1] ""  GW
 SG_ HWP_Lgtctrl_EngTrqReq : 79|16@0+ (0.0030518,-100) [-100|99.999713] "%"  GW
 SG_ HWP_Lgtctrl_EngTrqReqActv : 91|1@0+ (1,0) [0|1] ""  GW
 SG_ HWP_Lgtctrl_FuelCutOffReq : 90|1@0+ (1,0) [0|1] ""  GW
 SG_ HWP_ECMOvrdReq : 89|1@0+ (1,0) [0|1] ""  GW
 SG_ HWP_EngTrqReqActvVld : 88|1@0+ (1,0) [0|1] ""  GW
 SG_ HWP_Lgtctrl_EngTrqReqVld : 103|1@0+ (1,0) [0|1] ""  GW
 SG_ HWP_lgt_ModSts : 102|4@0+ (1,0) [0|15] ""  GW
 SG_ RollingCounter_IDC_L3_3 : 123|4@0+ (1,0) [0|15] "" Vector__XXX
 SG_ Checksum_IDC_L3_5 : 135|8@0+ (1,0) [0|255] ""  GW
 SG_ IDC_L3_HADFuncCmdReqFlag : 181|3@0+ (1,0) [0|7] ""  GW
 SG_ IFCVibrationWarning_L3 : 178|2@0+ (1,0) [0|3] ""  GW
 SG_ IDC_L3_AEB_ObjSty : 191|3@0+ (1,0) [0|7] ""  GW
 SG_ HWP_lgt_VehHldReq : 167|1@0+ (1,0) [0|1] ""  GW
 SG_ HWP_lgt_DrvOFF_Req : 166|1@0+ (1,0) [0|1] ""  GW
 SG_ HWP_lgt_Decel_Req : 165|1@0+ (1,0) [0|1] "" Vector__XXX
 SG_ HWP_lgt_DecelToStopReq : 164|1@0+ (1,0) [0|1] ""  GW
 SG_ HWP_lgt_Decel_ReqValue : 143|8@0+ (0.05,-7) [-7|5.75] "m/s^2" Vector__XXX
 SG_ HWP_AEB_ABALvl : 163|2@0+ (1,0) [0|3] ""  GW
 SG_ HWP_AEB_ABAReq : 161|1@0+ (1,0) [0|1] ""  GW
 SG_ HWP_EBA_DecelCtrlReq : 160|1@0+ (1,0) [0|1] ""  GW
 SG_ HWP_AEB_VehHldReq : 175|1@0+ (1,0) [0|1] "" Vector__XXX
 SG_ HWP_AEB_DecelCtrlReq : 174|1@0+ (1,0) [0|1] "" Vector__XXX
 SG_ HWP_AEB_DecelCtrlReqVal : 151|16@0+ (0.000488,-16) [-16|16] "m/s2" Vector__XXX
 SG_ HWP_AEB_AWB_Req : 173|1@0+ (1,0) [0|1] ""  GW
 SG_ HWP_AEB_AWB_Lvl : 172|4@0+ (1,0) [0|15] ""  GW
 SG_ HWP_AEB_ABP_Req : 168|1@0+ (1,0) [0|1] ""  GW
 SG_ HWP_EPBCtrlReq : 183|1@0+ (1,0) [0|1] ""  GW
 SG_ HWP_EPBCtrlReqVld : 182|1@0+ (1,0) [0|1] ""  GW
 SG_ RollingCounter_IDC_L3_5 : 187|4@0+ (1,0) [0|15] ""  GW
 SG_ Checksum_IDC_L3_4 : 199|8@0+ (1,0) [0|255] "" Vector__XXX
 SG_ HWP_Lgt_HCUTrqReq : 207|16@0+ (0.5,-16384) [-16384|16383.5] "NM"  GW
 SG_ HWP_Lgt_HCUTrqReqVld : 223|1@0+ (1,0) [0|1] ""  GW
 SG_ HWP_Lgt_HCUTrqReqActv : 222|1@0+ (1,0) [0|1] ""  GW
 SG_ HWP_Lgt_HCUTrqReqActvVld : 221|1@0+ (1,0) [0|1] ""  GW
 SG_ HWP_HCUOvrdReq : 220|1@0+ (1,0) [0|1] ""  GW
 SG_ HWP_TgtAccel : 219|12@0+ (0.0125,-16) [-16|16] ""  GW
 SG_ RollingCounter_IDC_L3_4 : 251|4@0+ (1,0) [0|15] "" Vector__XXX
 SG_ HWP_MotTypeReqMode : 319|2@0+ (1,0) [0|3] ""  GW
 SG_ HWP_MotTypeReqLong : 317|2@0+ (1,0) [0|3] ""  GW
 SG_ HWP_ShutdownReq : 311|1@0+ (1,0) [0|1] ""  GW
 SG_ HWP_UpperLimit : 279|8@0+ (0.1,0) [0|12.7] ""  GW
 SG_ HWP_LowerLimit : 287|8@0+ (0.1,-12.7) [-12.7|0] ""  GW
 SG_ HWP_SecureReq : 309|1@0+ (1,0) [0|1] ""  GW
 SG_ HWP_SuprAvail : 308|1@0+ (1,0) [0|1] ""  GW
 SG_ HWP_TgtAccelCmftUpprLimVal : 295|8@0+ (0.0125,0) [0|3.125] ""  GW
 SG_ HWP_TgtAccelCmftLwrLimVal : 303|8@0+ (0.0125,0) [0|3.125] ""  GW
 SG_ HWP_UseTgtAccelCmftUpprLimVal : 310|1@0+ (1,0) [0|1] ""  GW
 SG_ FreshnessValue_IDC_L3_FD1 : 455|16@0+ (1,0) [0|65535] ""  GW
 SG_ MAC_Check_IDC_L3_FD1 : 471|48@0+ (1,0) [0|281474976710655] ""  GW

BO_ 347 HAP_FD1: 64 AVP_HAP
 SG_ Checksum_APS1 : 71|8@0+ (1,0) [0|255] ""  GW
 SG_ APS_PrkgMod : 117|2@0+ (1,0) [0|3] ""  GW
 SG_ APS_ProcBar : 111|7@0+ (1,0) [0|127] "%"  GW
 SG_ APS_SwtSts : 104|1@0+ (1,0) [0|1] ""  GW
 SG_ APS_SlotDisp : 76|3@0+ (1,0) [0|7] ""  GW
 SG_ APS_ReqEPSTgtAngValid : 73|1@0+ (1,0) [0|1] ""  GW
 SG_ APS_ReqCtrlEPS : 72|1@0+ (1,0) [0|1] ""  GW
 SG_ APS_ReqEPSTgtAng : 87|15@0+ (0.1,0) [-1638.3|1638.3] "deg"  GW
 SG_ TurnLightsCmd : 115|2@0+ (1,0) [0|3] ""  GW
 SG_ APS_SysSoundIndcn : 79|3@0+ (1,0) [0|7] ""  GW
 SG_ APS_PrkgTyp : 119|2@0+ (1,0) [0|3] ""  GW
 SG_ APS_TextDisp : 103|8@0+ (1,0) [0|255] ""  GW
 SG_ RollingCounter_APS1 : 123|4@0+ (1,0) [0|15] ""  GW
 SG_ Checksum_APS4 : 135|8@0+ (1,0) [0|255] ""  GW
 SG_ APS_BrkFctnMod : 143|3@0+ (1,0) [0|7] ""  GW
 SG_ APS_ESP_TgtGearReq : 140|3@0+ (1,0) [0|7] ""  GW
 SG_ APS_ESP_SpdLimn : 159|8@0+ (0.1,0) [0|25.5] "kmh"  GW
 SG_ APS_BrkModSts : 151|3@0+ (1,0) [0|7] ""  GW
 SG_ APS_ESP_BrkDistance : 167|12@0+ (1,0) [0|4095] "cm"  GW
 SG_ APS_BrkCategory : 137|2@0+ (1,0) [0|3] ""  GW
 SG_ MEB_BrkgReqValue : 183|8@0+ (0.05,-10) [-10|0] "m/s^2"  GW
 SG_ MEB_BrkgReq : 147|1@0+ (1,0) [0|1] ""  GW
 SG_ MEBErrSts : 148|1@0+ (1,0) [0|1] ""  GW
 SG_ APS_WorkSts : 146|3@0+ (1,0) [0|7] ""  GW,FR,IDC_L2
 SG_ MEB_AVHReq : 168|1@0+ (1,0) [0|1] ""  GW
 SG_ RollingCounter_APS4 : 187|4@0+ (1,0) [0|15] ""  GW
 SG_ Checksum_AVP1 : 199|8@0+ (1,0) [0|255] ""  GW
 SG_ AVP_ESP_LSMSubMTReq : 209|2@0+ (1,0) [0|3] ""  GW
 SG_ AVP_ESP_LSMSubMTLevel : 226|2@0+ (1,0) [0|3] ""  GW
 SG_ AVP_ESP_LSMSubMTLong : 239|2@0+ (1,0) [0|3] ""  GW
 SG_ AVP_ESP_LSMPrefill : 224|1@0+ (1,0) [0|1] ""  GW
 SG_ AVP_ESP_LSMDistToStop : 207|12@0+ (1,0) [0|4095] "cm"  GW
 SG_ AVP_ESP_LSMVehDirRq : 237|2@0+ (1,0) [0|3] ""  GW
 SG_ AVP_ESP_LSMvMaxRq : 223|11@0+ (0.1,0) [0|20] "kph"  GW
 SG_ AVP_ESP_LSMVehSecReq : 233|1@0+ (1,0) [0|1] ""  GW
 SG_ AVP_ESP_LSMNudgeReq : 232|1@0+ (1,0) [0|1] ""  GW
 SG_ AVP_ESP_LSMComfBrakeReq : 235|2@0+ (1,0) [0|3] ""  GW
 SG_ AVP_ESP_DriverPresenceExternal : 210|1@0+ (1,0) [0|1] ""  GW
 SG_ AVP_ESP_SafeDrvrHandoverReq : 227|1@0+ (1,0) [0|1] ""  GW
 SG_ RollingCounter_AVP1 : 251|4@0+ (1,0) [0|15] ""  GW
 SG_ Checksum_HAP1 : 263|8@0+ (1,0) [0|255] ""  GW
 SG_ P2P_PrkgDirectSts : 293|1@0+ (1,0) [0|1] ""  GW
 SG_ RmtPrkgReq : 284|1@0+ (1,0) [0|1] ""  GW
 SG_ LParaPrkgOutVald : 283|1@0+ (1,0) [0|1] ""  GW
 SG_ RParaPrkgOutVald : 282|1@0+ (1,0) [0|1] ""  GW
 SG_ HeadVertPrkgOutVald : 281|1@0+ (1,0) [0|1] ""  GW
 SG_ TailVertPrkgOutVald : 280|1@0+ (1,0) [0|1] ""  GW
 SG_ HAP_SwtDispCtrlCmd : 279|3@0+ (1,0) [0|7] ""  GW
 SG_ P2P_PahDelSts : 265|2@0+ (1,0) [0|3] ""  GW
 SG_ P2P_SelfDetErrCode : 276|4@0+ (1,0) [0|15] ""  GW
 SG_ P2P_SelfDetSts : 287|2@0+ (1,0) [0|3] ""  GW
 SG_ P2P_Pah1Avail : 272|1@0+ (1,0) [0|1] ""  GW
 SG_ P2P_Pah2Avail : 285|1@0+ (1,0) [0|1] ""  GW
 SG_ APS_PASSwtReq : 271|2@0+ (1,0) [0|3] ""  GW
 SG_ HAP_PrkgModCurrSts : 269|4@0+ (1,0) [0|15] ""  GW
 SG_ APS_MovgDirc : 295|2@0+ (1,0) [0|3] ""  GW
 SG_ AVP_HiBeamtReq : 292|2@0+ (1,0) [0|3] ""  GW
 SG_ AVP_DippedBeamReq : 290|2@0+ (1,0) [0|3] ""  GW
 SG_ AVP_HornReq : 302|2@0+ (1,0) [0|3] ""  GW
 SG_ AVP_FWiperReq : 300|3@0+ (1,0) [0|7] ""  GW
 SG_ AVP_FWshrReq : 297|2@0+ (1,0) [0|3] ""  GW
 SG_ AVP_PowerModeReq : 311|2@0+ (1,0) [0|3] ""  GW
 SG_ AVP_WindLockReq : 309|2@0+ (1,0) [0|3] ""  GW
 SG_ AVP_SunroofCloseReq : 319|2@0+ (1,0) [0|3] ""  GW
 SG_ AVP_T_Box_WorkSts : 317|2@0+ (1,0) [0|3] ""  GW
 SG_ AVP_CenCtrllockReq : 307|2@0+ (1,0) [0|3] ""  GW
 SG_ RmtCtrlSts : 305|1@0+ (1,0) [0|1] ""  GW
 SG_ RollingCounter_HAP1 : 315|4@0+ (1,0) [0|15] ""  GW
 SG_ Checksum_HAP3 : 327|8@0+ (1,0) [0|255] ""  PIS
 SG_ HAVP_StartBtn_Ena : 331|2@0+ (1,0) [0|3] ""  GW
 SG_ HAVP_StopBtn_Ena : 329|2@0+ (1,0) [0|3] ""  GW
 SG_ HAVP_SelfParLotEnding_Ena : 339|2@0+ (1,0) [0|3] ""  GW
 SG_ HAVP_WorkSts : 335|4@0+ (1,0) [0|15] ""  GW,PIS
 SG_ HAVP_FuncSts : 345|2@0+ (1,0) [0|3] ""  GW
 SG_ PAVP_FuncSts : 353|2@0+ (1,0) [0|3] ""  GW
 SG_ PAVP_TextDis : 351|6@0+ (1,0) [0|63] ""  GW
 SG_ PAVP_Status : 343|4@0+ (1,0) [0|15] ""  GW,PIS
 SG_ PAVP_TextDis2 : 359|6@0+ (1,0) [0|63] ""  GW
 SG_ ParallelSlotBtn_Ena : 367|2@0+ (1,0) [0|3] ""  GW
 SG_ VerticalSlotBtn_Ena : 365|2@0+ (1,0) [0|3] ""  GW
 SG_ ClockwiseBtn_Ena : 363|2@0+ (1,0) [0|3] ""  GW
 SG_ AnticlockwiseBtn_Ena : 361|2@0+ (1,0) [0|3] ""  GW
 SG_ SlotConfirmBtn_Ena : 375|2@0+ (1,0) [0|3] ""  GW
 SG_ RollingCounter_HAP3 : 379|4@0+ (1,0) [0|15] ""  PIS
 SG_ FreshnessValue_HAP_FD1 : 455|16@0+ (1,0) [0|65535] ""  GW
 SG_ MAC_Check_HAP_FD1 : 471|48@0+ (1,0) [0|281474976710655] ""  GW

BO_ 350 CR_FD1: 64 CR_R
 SG_ Checksum_CR_R_1 : 71|8@0+ (1,0) [0|255] ""  FR
 SG_ CR_FCTA_Resp : 79|1@0+ (1,0) [0|1] ""  GW,IDC_L2
 SG_ CR_FCTB_Resp : 78|1@0+ (1,0) [0|1] ""  GW,IDC_L2
 SG_ CR_ErrSts : 87|1@0+ (1,0) [0|1] ""  FR,IDC_L2
 SG_ CR_BliSts : 86|1@0+ (1,0) [0|1] ""  GW,IDC_L2
 SG_ FCTB_ABA_Level : 82|2@0+ (1,0) [0|3] ""  FR,IDC_L2
 SG_ FCTB_ABA_Req : 80|1@0+ (1,0) [0|1] ""  FR,IDC_L2
 SG_ FCTB_ABP_Req : 111|1@0+ (1,0) [0|1] ""  FR,IDC_L2
 SG_ FCTA_Warn : 75|1@0+ (1,0) [0|1] ""  GW,IDC_L2
 SG_ FCTBTrig : 83|1@0+ (1,0) [0|1] ""  GW,IDC_L2
 SG_ FCTA_B_FuncSts : 77|2@0+ (1,0) [0|3] ""  GW,IDC_L2
 SG_ CR_BrkgReqVal : 95|16@0+ (0.000488,-16) [-16|16] "m/s2"  FR,IDC_L2
 SG_ CR_BrkgReq : 85|1@0+ (1,0) [0|1] ""  FR,IDC_L2
 SG_ FCTA_B_TTC : 110|6@0+ (0.1,0) [0|6.3] "s"  GW,IDC_L2
 SG_ RollingCounter_CR_R_1 : 123|4@0+ (1,0) [0|15] ""  FR
 SG_ Checksum_CR_R_2 : 135|8@0+ (1,0) [0|255] ""  IFC,IDC_L2
 SG_ CR_ObjSts_Le : 179|2@0+ (1,0) [0|3] ""  IFC,IDC_L2
 SG_ CR_ObjID_Le : 157|6@0+ (1,0) [0|63] ""  IFC,IDC_L2
 SG_ CR_ObjDistX_Le : 151|10@0+ (0.1,-10) [-10|92.3] "m"  IFC,IDC_L2
 SG_ CR_ObjDistY_Le : 143|8@0+ (0.1,-12.8) [-12.8|12.7] "m"  IFC,IDC_L2
 SG_ CR_ObjRelVelX_Le : 167|10@0+ (0.1,-60) [-60|42.3] "m/s"  IFC,IDC_L2
 SG_ CR_ObjRelAccelX_Le : 173|10@0+ (0.03125,-16) [-16|15.9688] "m/s2"  IFC,IDC_L2
 SG_ CR_ObjMotionType_Le : 191|3@0+ (1,0) [0|7] ""  IFC,IDC_L2
 SG_ RollingCounter_CR_R_2 : 187|4@0+ (1,0) [0|15] ""  IFC,IDC_L2
 SG_ Checksum_CR_R_3 : 199|8@0+ (1,0) [0|255] ""  IFC,IDC_L2
 SG_ CR_ObjSts_Ri : 243|2@0+ (1,0) [0|3] ""  IFC,IDC_L2
 SG_ CR_ObjID_Ri : 221|6@0+ (1,0) [0|63] ""  IFC,IDC_L2
 SG_ CR_ObjDistX_Ri : 215|10@0+ (0.1,-10) [-10|92.3] "m"  IFC,IDC_L2
 SG_ CR_ObjDistY_Ri : 207|8@0+ (0.1,-12.8) [-12.8|12.7] "m"  IFC,IDC_L2
 SG_ CR_ObjRelVelX_Ri : 231|10@0+ (0.1,-60) [-60|42.3] "m/s"  IFC,IDC_L2
 SG_ CR_ObjRelAccelX_Ri : 237|10@0+ (0.03125,-16) [-16|15.9688] "m/s2"  IFC,IDC_L2
 SG_ CR_ObjMotionType_Ri : 255|3@0+ (1,0) [0|7] ""  IFC,IDC_L2
 SG_ RollingCounter_CR_R_3 : 251|4@0+ (1,0) [0|15] ""  IFC,IDC_L2
 SG_ Checksum_CR_R_4 : 263|8@0+ (1,0) [0|255] ""  IFC,IDC_L2
 SG_ CR_ObjRelAccelY_Ri : 271|10@0+ (0.03125,-16) [-16|15.9688] "m/s2"  IFC,IDC_L2
 SG_ CR_ObjRelVelY_Ri : 295|7@0+ (0.1,-6.4) [-6.4|6.3] "m/s"  IFC,IDC_L2
 SG_ CR_ObjRelAccelY_Le : 277|10@0+ (0.03125,-16) [-16|15.9688] "m/s2"  IFC,IDC_L2
 SG_ CR_ObjRelVelY_Le : 303|7@0+ (0.1,-6.4) [-6.4|6.3] "m/s"  IFC,IDC_L2
 SG_ RollingCounter_CR_R_4 : 315|4@0+ (1,0) [0|15] ""  IFC,IDC_L2
 SG_ CR_ObjDistXStd_Le : 335|5@0+ (0.375,0) [0|11.625] "m"  IFC,IDC_L2
 SG_ CR_ObjDistYStd_Le : 330|5@0+ (0.375,0) [0|11.625] "m"  IFC,IDC_L2
 SG_ CR_ObjRelVelXStd_Le : 341|5@0+ (0.375,0) [0|11.625] "mps"  IFC,IDC_L2
 SG_ CR_ObjRelVelYStd_Le : 336|5@0+ (0.375,0) [0|11.625] "mps"  IFC,IDC_L2
 SG_ CR_ObjRAccelXStd_Le : 347|5@0+ (0.375,0) [0|11.625] "mps2"  IFC,IDC_L2
 SG_ CR_ObjRAccelYStd_Le : 358|5@0+ (0.375,0) [0|11.625] "mps2"  IFC,IDC_L2
 SG_ CR_ObjDistXStd_Ri : 353|5@0+ (0.375,0) [0|11.625] "m"  IFC,IDC_L2
 SG_ CR_ObjDistYStd_Ri : 364|5@0+ (0.375,0) [0|11.625] "m"  IFC,IDC_L2
 SG_ CR_ObjRelVelXStd_Ri : 375|5@0+ (0.375,0) [0|11.625] "mps"  IFC,IDC_L2
 SG_ CR_ObjRelVelYStd_Ri : 399|5@0+ (0.375,0) [0|11.625] "mps"  IFC,IDC_L2
 SG_ CR_ObjRAccelXStd_Ri : 394|5@0+ (0.375,0) [0|11.625] "mps2"  IFC,IDC_L2
 SG_ CR_ObjRAccelYStd_Ri : 405|5@0+ (0.375,0) [0|11.625] "mps2"  IFC,IDC_L2

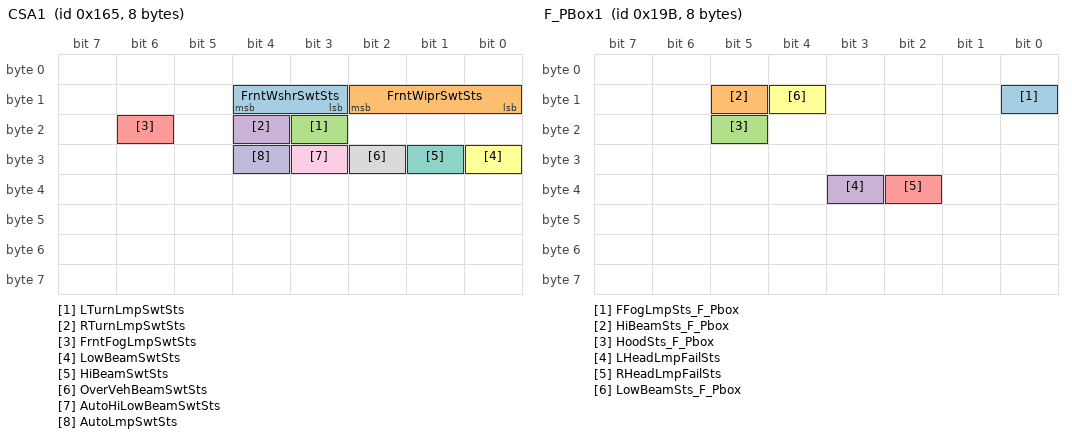
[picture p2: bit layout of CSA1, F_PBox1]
BO_ 357 CSA1: 8 GW
 SG_ FrntWshrSwtSts : 12|2@0+ (1,0) [0|3] ""  IFC,AVP,IDC_L2
 SG_ FrntWiprSwtSts : 10|3@0+ (1,0) [0|7] ""  IFC,HC,AVP,IDC_L2
 SG_ LTurnLmpSwtSts : 19|1@0+ (1,0) [0|1] ""  IFC,FR,RSDS_R,RSDS_L,AVP,HAP,PAS,CR_L,CR_R,IDC_L2,IDC_L3
 SG_ RTurnLmpSwtSts : 20|1@0+ (1,0) [0|1] ""  IFC,FR,RSDS_R,RSDS_L,AVP,HAP,PAS,CR_L,CR_R,IDC_L2,IDC_L3
 SG_ FrntFogLmpSwtSts : 22|1@0+ (1,0) [0|1] ""  IFC,HC,IDC_L2
 SG_ LowBeamSwtSts : 24|1@0+ (1,0) [0|1] ""  IFC,AVP,IDC_L2
 SG_ HiBeamSwtSts : 25|1@0+ (1,0) [0|1] ""  IFC,HC,AVP,IDC_L2
 SG_ OverVehBeamSwtSts : 26|1@0+ (1,0) [0|1] ""  HC
 SG_ AutoHiLowBeamSwtSts : 27|1@0+ (1,0) [0|1] ""  HC
 SG_ AutoLmpSwtSts : 28|1@0+ (1,0) [0|1] ""  IFC,HC,IDC_L2

BO_ 367 RSDS_FD1: 64 RSDS_R
 SG_ RSDS_ObjRelAccelY_Le : 15|10@0+ (0.03125,-16) [-16|15.9688] "m/s2"  IFC,IDC_L2
 SG_ Checksum_RSDS_R_2 : 71|8@0+ (1,0) [0|255] ""  GW
 SG_ RSDS_Brk_ErrSts : 79|1@0+ (1,0) [0|1] ""  GW
 SG_ RSDS_BrkgReq : 78|1@0+ (1,0) [0|1] ""  GW
 SG_ RSDS_BrkgReqVal : 77|8@0+ (0.05,-10) [-10|2.75] "m/s^2"  GW
 SG_ RSDS_LEDLightReqLeft : 85|2@0+ (1,0) [0|3] ""  GW
 SG_ RSDS_LEDLightReqRight : 83|2@0+ (1,0) [0|3] ""  GW
 SG_ RSDS_IPSoundReq : 81|2@0+ (1,0) [0|3] ""  GW
 SG_ RSDS_RCW_Trigger : 105|2@0+ (1,0) [0|3] ""  GW
 SG_ RSDS_ErrSts : 119|1@0+ (1,0) [0|1] ""  GW
 SG_ RSDS_BrkgTrig : 118|1@0+ (1,0) [0|1] ""  GW
 SG_ RSDS_BliSts : 117|1@0+ (1,0) [0|1] ""  GW
 SG_ RSDS_TrailerSts : 116|1@0+ (1,0) [0|1] ""  GW
 SG_ RSDS_LCAResp : 115|1@0+ (1,0) [0|1] ""  GW
 SG_ RSDS_CTA_Actv : 126|1@0+ (1,0) [0|1] ""  GW
 SG_ RSDS_DOWResp : 114|1@0+ (1,0) [0|1] ""  GW
 SG_ RSDS_RCWResp : 113|1@0+ (1,0) [0|1] ""  GW
 SG_ RSDS_RCTAResp : 112|1@0+ (1,0) [0|1] ""  GW
 SG_ RSDS_RCTABrkResp : 127|1@0+ (1,0) [0|1] ""  GW
 SG_ BSD_LCA_warningReqRight : 95|2@0+ (1,0) [0|3] ""  GW
 SG_ BSD_LCA_warningReqleft : 93|2@0+ (1,0) [0|3] ""  GW
 SG_ DOW_warningReqRight : 91|2@0+ (1,0) [0|3] ""  GW
 SG_ DOW_warningReqleft : 89|2@0+ (1,0) [0|3] ""  GW
 SG_ RCTA_warningReqRight : 125|1@0+ (1,0) [0|1] ""  GW
 SG_ RCTA_warningReqLeft : 124|1@0+ (1,0) [0|1] ""  GW
 SG_ RollingCounter_RSDS_R_2 : 123|4@0+ (1,0) [0|15] ""  GW
 SG_ Checksum_RSDS_R_3 : 135|8@0+ (1,0) [0|255] ""  IFC,IDC_L2
 SG_ LeTarSts : 143|2@0+ (1,0) [0|3] ""  IFC,HAP,IDC_L2
 SG_ ObjIDLe : 141|6@0+ (1,0) [0|63] ""  IFC,HAP,IDC_L2
 SG_ ObjLgtPosnCurvLe : 151|10@0+ (0.1,-92.3) [-92.3|10] "m"  IFC,HAP,IDC_L2
 SG_ ObjLatPosnCurvLe : 157|8@0+ (0.1,-12.8) [-12.8|12.7] "m"  IFC,HAP,IDC_L2
 SG_ ObjLgtSpdCurvLe : 165|10@0+ (0.1,-10) [-10|92.3] "m/s"  IFC,HAP,IDC_L2
 SG_ ObjLatSpdCurvLe : 171|7@0+ (0.1,-6.4) [-6.4|6.3] "m/s"  IFC,HAP,IDC_L2
 SG_ ObjTTCLe : 180|7@0+ (0.1,0) [0|12.7] "s"  IFC,IDC_L2
 SG_ RollingCounter_RSDS_R_3 : 187|4@0+ (1,0) [0|15] ""  IFC,IDC_L2
 SG_ Checksum_RSDS_R_4 : 199|8@0+ (1,0) [0|255] ""  IFC,IDC_L2
 SG_ ObjLenLe : 207|4@0+ (1,0) [0|15] "m"  IFC,IDC_L2
 SG_ ObjWidthLe : 203|3@0+ (0.5,0) [0|3.5] "m"  IFC,IDC_L2
 SG_ ObjStatyLe : 200|1@0+ (1,0) [0|1] ""  IFC,IDC_L2
 SG_ ZoneIndLe : 215|2@0+ (1,0) [0|3] ""  IFC,IDC_L2
 SG_ ObjStsLe : 213|2@0+ (1,0) [0|3] ""  IFC,IDC_L2
 SG_ ObjRinRi : 211|4@0+ (1,0) [0|15] "m"  IFC,IDC_L2
 SG_ ObjWidthRi : 223|3@0+ (0.5,0) [0|3.5] "m"  IFC,IDC_L2
 SG_ ObjStatyRi : 220|1@0+ (1,0) [0|1] ""  IFC,IDC_L2
 SG_ ZoneIndRi : 219|2@0+ (1,0) [0|3] ""  IFC,IDC_L2
 SG_ ObjStsRi : 217|2@0+ (1,0) [0|3] ""  IFC,IDC_L2
 SG_ RollingCounter_RSDS_R_4 : 251|4@0+ (1,0) [0|15] ""  IFC,IDC_L2
 SG_ Checksum_RSDS_R_5 : 263|8@0+ (1,0) [0|255] ""  IFC,IDC_L2
 SG_ RiTarSts : 271|2@0+ (1,0) [0|3] ""  IFC,HAP,IDC_L2
 SG_ ObjIDRi : 269|6@0+ (1,0) [0|63] ""  IFC,HAP,IDC_L2
 SG_ ObjLgtPosnCurvRi : 279|10@0+ (0.1,-92.3) [-92.3|10] "m"  IFC,HAP,IDC_L2
 SG_ ObjLatPosnCurvRi : 285|8@0+ (0.1,-12.8) [-12.8|12.7] "m"  IFC,HAP,IDC_L2
 SG_ ObjLgtSpdCurvRi : 293|10@0+ (0.1,-10) [-10|92.3] "m/s"  IFC,HAP,IDC_L2
 SG_ ObjLatSpdCurvRi : 299|7@0+ (0.1,-6.4) [-6.4|6.3] "m/s"  IFC,HAP,IDC_L2
 SG_ ObjTTCRi : 308|7@0+ (0.1,0) [0|12.7] "s"  IFC,IDC_L2
 SG_ RollingCounter_RSDS_R_5 : 315|4@0+ (1,0) [0|15] ""  IFC,IDC_L2
 SG_ RSDS_ObjDistXStd_Le : 335|5@0+ (0.375,0) [0|11.625] "m"  IFC,IDC_L2
 SG_ RSDS_ObjDistYStd_Le : 330|5@0+ (0.375,0) [0|11.625] "m"  IFC,IDC_L2
 SG_ RSDS_ObjRelVelXStd_Le : 341|5@0+ (0.375,0) [0|11.625] "mps"  IFC,IDC_L2
 SG_ RSDS_ObjRelVelYStd_Le : 336|5@0+ (0.375,0) [0|11.625] "mps"  IFC,IDC_L2
 SG_ RSDS_ObjRAccelXStd_Le : 347|5@0+ (0.375,0) [0|11.625] "mps2"  IFC,IDC_L2
 SG_ RSDS_ObjRAccelYStd_Le : 358|5@0+ (0.375,0) [0|11.625] "mps2"  IFC,IDC_L2
 SG_ RSDS_ObjDistXStd_Ri : 353|5@0+ (0.375,0) [0|11.625] "m"  IFC,IDC_L2
 SG_ RSDS_ObjDistYStd_Ri : 364|5@0+ (0.375,0) [0|11.625] "m"  IFC,IDC_L2
 SG_ RSDS_ObjRelVelXStd_Ri : 375|5@0+ (0.375,0) [0|11.625] "mps"  IFC,IDC_L2
 SG_ RSDS_ObjRelVelYStd_Ri : 399|5@0+ (0.375,0) [0|11.625] "mps"  IFC,IDC_L2
 SG_ RSDS_ObjRAccelXStd_Ri : 394|5@0+ (0.375,0) [0|11.625] "mps2"  IFC,IDC_L2
 SG_ RSDS_ObjRAccelYStd_Ri : 405|5@0+ (0.375,0) [0|11.625] "mps2"  IFC,IDC_L2
 SG_ RSDS_ObjRelAccelX_Le : 415|10@0+ (0.03125,-16) [-16|15.9688] "m/s2"  IFC,IDC_L2
 SG_ RSDS_ObjRelAccelX_Ri : 421|10@0+ (0.03125,-16) [-16|15.9688] "m/s2"  IFC,IDC_L2
 SG_ RSDS_ObjRelAccelY_Ri : 427|10@0+ (0.03125,-16) [-16|15.9688] "m/s2"  IFC,IDC_L2

BO_ 395 AEB_FD1: 64 FR_IDC_L2
 SG_ Checksum_AEB1 : 71|8@0+ (1,0) [0|255] ""  GW
 SG_ AEB_ABA_Level : 79|2@0+ (1,0) [0|3] ""  GW
 SG_ AEB_ABA_Req : 77|1@0+ (1,0) [0|1] ""  GW
 SG_ EBA_TgtDecel_Req : 76|1@0+ (1,0) [0|1] ""  GW
 SG_ AEB_VehHldReq : 75|1@0+ (1,0) [0|1] ""  GW
 SG_ AEB_TgtDecel_Req : 74|1@0+ (1,0) [0|1] ""  GW
 SG_ AEB_TgtDecel_ReqValue : 87|16@0+ (0.000488,-16) [-16|16] "m/s2"  GW
 SG_ AEB_AWB_Req : 73|1@0+ (1,0) [0|1] ""  GW
 SG_ AEB_AWB_Level : 103|4@0+ (1,0) [0|15] ""  GW
 SG_ AEB_ABP_Req : 72|1@0+ (1,0) [0|1] ""  GW
 SG_ AEB_BrkReqFunc : 99|3@0+ (1,0) [0|7] "" Vector__XXX
 SG_ AEB_ObjSty : 111|3@0+ (1,0) [0|7] ""  GW
 SG_ RollingCounter_AEB1 : 123|4@0+ (1,0) [0|15] ""  GW

BO_ 411 F_PBox1: 8 GW
 SG_ FFogLmpSts_F_Pbox : 8|1@0+ (1,0) [0|1] ""  IFC,AVP,HAP,PAS,IDC_L2
 SG_ HiBeamSts_F_Pbox : 13|1@0+ (1,0) [0|1] ""  IFC,AVP,HAP,PAS,IDC_L2
 SG_ HoodSts_F_Pbox : 21|1@0+ (1,0) [0|1] ""  FR,IDC_L2
 SG_ LHeadLmpFailSts : 35|1@0+ (1,0) [0|1] ""  HC
 SG_ RHeadLmpFailSts : 34|1@0+ (1,0) [0|1] ""  HC
 SG_ LowBeamSts_F_Pbox : 12|1@0+ (1,0) [0|1] ""  IFC,HC,AVP,HAP,PAS,IDC_L2

BO_ 412 R_PBox1: 16 GW
 SG_ HiPosnBrkLmpFailSts : 15|1@0+ (1,0) [0|1] ""  AVP,HAP,PAS,IDC_L3
 SG_ LBrkLmpFailSts : 13|1@0+ (1,0) [0|1] ""  AVP,HAP,PAS,IDC_L3
 SG_ RFogLmpFailSts_R_Pbox : 29|1@0+ (1,0) [0|1] ""  AVP,HAP,PAS,IDC_L3
 SG_ RFogLmpSts_R_Pbox : 28|1@0+ (1,0) [0|1] ""  AVP,HAP,IDC_L3
 SG_ RBrkLmpFailSts : 12|1@0+ (1,0) [0|1] ""  AVP,HAP,PAS,IDC_L3
 SG_ PosnLmpOutpSts_R_Pbox : 11|1@0+ (1,0) [0|1] ""  AVP,HAP,PAS,IDC_L3
 SG_ LTurnLmpSts_R_Pbox : 31|1@0+ (1,0) [0|1] ""  IFC,FR,AVP,HAP,PAS,IDC_L2,IDC_L3
 SG_ RTurnLmpSts_R_Pbox : 30|1@0+ (1,0) [0|1] ""  IFC,FR,AVP,HAP,PAS,IDC_L2,IDC_L3
 SG_ FreshnessValue_R_PBox1 : 71|16@0+ (1,0) [0|65535] ""  FR,IDC_L2,IDC_L3
 SG_ MAC_Check_R_PBox1 : 87|48@0+ (1,0) [0|281474976710655] ""  FR,IDC_L2,IDC_L3

BO_ 415 IFC_FD5: 64 IFC_IDC_L2
 SG_ IFC_Line01_Dy : 15|13@0+ (0.01,-30) [-30|30] "m"  GW
 SG_ IFC_Line01_Curv : 18|15@0+ (1.6E-005,-0.25) [-0.25|0.25] "1/m"  GW
 SG_ IFC_Line01_CurvChange : 35|20@0+ (5E-008,-0.024) [-0.024|0.024] "1/(m*m)"  GW
 SG_ IFC_Line01_Type : 63|4@0+ (1,0) [0|15] ""  GW
 SG_ IFC_Line02_Dy : 79|13@0+ (0.01,-30) [-30|30] "m"  GW
 SG_ IFC_Line02_Curv : 82|15@0+ (1.6E-005,-0.25) [-0.25|0.25] "1/m"  GW
 SG_ IFC_Line02_CurvChange : 99|20@0+ (5E-008,-0.024) [-0.024|0.024] "1/(m*m)"  GW
 SG_ IFC_Line02_Type : 127|4@0+ (1,0) [0|15] ""  GW
 SG_ IFC_Line03_Dy : 143|13@0+ (0.01,-30) [-30|30] "m"  GW
 SG_ IFC_Line03_Curv : 146|15@0+ (1.6E-005,-0.25) [-0.25|0.25] "1/m"  GW
 SG_ IFC_Line03_CurvChange : 163|20@0+ (5E-008,-0.024) [-0.024|0.024] "1/(m*m)"  GW
 SG_ IFC_Line03_Type : 191|4@0+ (1,0) [0|15] ""  GW
 SG_ IFC_Line04_Dy : 207|13@0+ (0.01,-30) [-30|30] "m"  GW
 SG_ IFC_Line04_Curv : 210|15@0+ (1.6E-005,-0.25) [-0.25|0.25] "1/m"  GW
 SG_ IFC_Line04_CurvChange : 227|20@0+ (5E-008,-0.024) [-0.024|0.024] "1/(m*m)"  GW
 SG_ IFC_Line04_Type : 255|4@0+ (1,0) [0|15] ""  GW
 SG_ IFC_Roadedge01_Dy : 271|13@0+ (0.01,-30) [-30|30] "m"  GW
 SG_ IFC_Roadedge01_Curv : 274|15@0+ (1.6E-005,-0.25) [-0.25|0.25] "1/m"  GW
 SG_ IFC_Roadedge01_CurvChange : 291|20@0+ (5E-008,-0.024) [-0.024|0.024] "1/(m*m)"  GW
 SG_ IFC_Roadedge01_Type : 319|4@0+ (1,0) [0|15] ""  GW
 SG_ IFC_Roadedge02_Dy : 335|13@0+ (0.01,-30) [-30|30] "m"  GW
 SG_ IFC_Roadedge02_Curv : 338|15@0+ (1.6E-005,-0.25) [-0.25|0.25] "1/m"  GW
 SG_ IFC_Roadedge02_CurvChange : 355|20@0+ (5E-008,-0.024) [-0.024|0.024] "1/(m*m)"  GW
 SG_ IFC_Roadedge02_Type : 383|4@0+ (1,0) [0|15] ""  GW

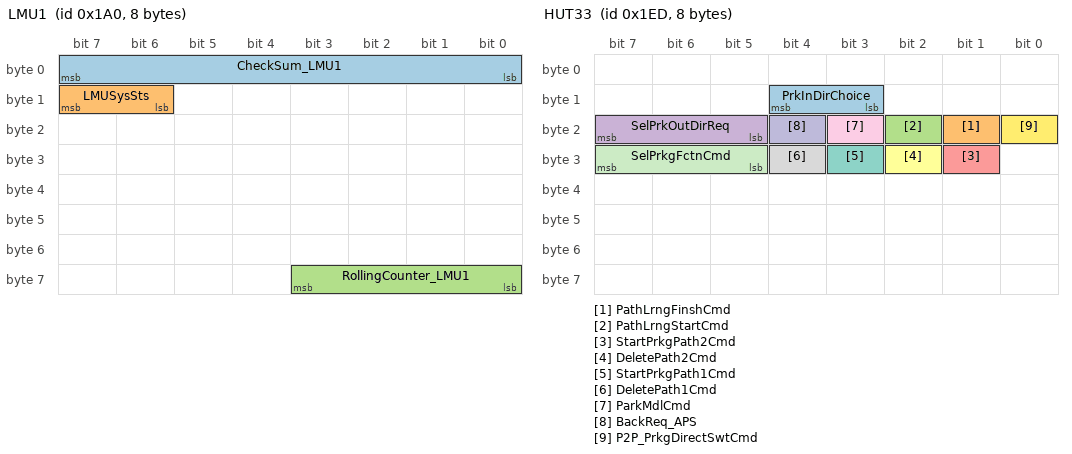
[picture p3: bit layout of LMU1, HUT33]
BO_ 416 LMU1: 8 LMU
 SG_ CheckSum_LMU1 : 7|8@0+ (1,0) [0|255] ""  IDC_L2
 SG_ LMUSysSts : 15|2@0+ (1,0) [0|3] ""  IDC_L2
 SG_ RollingCounter_LMU1 : 59|4@0+ (1,0) [0|15] ""  IDC_L2

BO_ 474 HUT_FD4: 64 GW
 SG_ HUT_HAVP_APA_Permit : 43|2@0+ (1,0) [0|3] ""  AVP
 SG_ HUT_HAVP_Return_Btn : 11|1@0+ (1,0) [0|1] ""  AVP
 SG_ HUT_HAVP_Set_Starting : 10|1@0+ (1,0) [0|1] ""  AVP
 SG_ HUT_HAVP_SelfParLot_Ending : 9|1@0+ (1,0) [0|1] ""  AVP
 SG_ HUT_HAVP_Comfirm_Btn : 8|1@0+ (1,0) [0|1] ""  AVP
 SG_ HUT_HAVP_Learning_Set_ParkLot : 23|2@0+ (1,0) [0|3] ""  AVP
 SG_ HUT_HAVP_Set_Path_Ending : 21|1@0+ (1,0) [0|1] ""  AVP
 SG_ HUT_HAVP_LearningTypeSele : 20|2@0+ (1,0) [0|3] ""  AVP
 SG_ HUT_HAVP_Path_Delete : 31|4@0+ (1,0) [0|15] ""  AVP
 SG_ HUT_HAVP_Path_Select : 27|4@0+ (1,0) [0|15] ""  AVP
 SG_ HUT_HAVP_Path_SetTop : 39|4@0+ (1,0) [0|15] ""  AVP
 SG_ SlotNum_VR : 35|4@0+ (1,0) [0|15] ""  AVP
 SG_ HUT_PAVP_Confirm : 47|1@0+ (1,0) [0|1] ""  AVP
 SG_ HUT_PAVP_DropOff_Area_req : 46|1@0+ (1,0) [0|1] ""  AVP
 SG_ HUT_PAVP_PathList_Req : 45|1@0+ (1,0) [0|1] ""  AVP
 SG_ UserDefinedParkCmd : 44|1@0+ (1,0) [0|1] ""  AVP,HAP
 SG_ UserDefPrkMenuSelCmd : 18|3@0+ (1,0) [0|1] ""  AVP,HAP

BO_ 493 HUT33: 8 GW
 SG_ PrkInDirChoice : 12|2@0+ (1,0) [0|3] ""  AVP,HAP
 SG_ PathLrngFinshCmd : 17|1@0+ (1,0) [0|1] ""  HAP
 SG_ PathLrngStartCmd : 18|1@0+ (1,0) [0|1] ""  HAP
 SG_ SelPrkOutDirReq : 23|3@0+ (1,0) [0|7] ""  AVP,HAP
 SG_ StartPrkgPath2Cmd : 25|1@0+ (1,0) [0|1] ""  HAP
 SG_ DeletePath2Cmd : 26|1@0+ (1,0) [0|1] ""  HAP
 SG_ StartPrkgPath1Cmd : 27|1@0+ (1,0) [0|1] ""  HAP
 SG_ DeletePath1Cmd : 28|1@0+ (1,0) [0|1] ""  HAP
 SG_ ParkMdlCmd : 19|1@0+ (1,0) [0|1] ""  AVP,HAP
 SG_ BackReq_APS : 20|1@0+ (1,0) [0|1] ""  AVP,HAP
 SG_ SelPrkgFctnCmd : 31|3@0+ (1,0) [0|7] ""  AVP,HAP
 SG_ P2P_PrkgDirectSwtCmd : 16|1@0+ (1,0) [0|1] ""  HAP

BO_ 494 HUT15: 16 GW
 SG_ SDWSwtSet : 39|1@0+ (1,0) [0|1] ""  AVP,HAP
 SG_ APSSwtReq_VR : 55|2@0+ (1,0) [0|3] ""  AVP,HAP
 SG_ APSPrkgTypSeln : 34|2@0+ (1,0) [0|3] ""  AVP,HAP

BO_ 515 HUT_FD2: 64 GW
 SG_ HUT_OD_Obj0_ID : 15|4@0+ (1,0) [0|9] ""  PAS
 SG_ HUT_OD_Obj0_type : 23|3@0+ (1,0) [0|7] ""  PAS
 SG_ HUT_OD_Obj0_Confidence : 11|4@0+ (0.1,0) [0|1] ""  PAS
 SG_ HUT_OD_Obj0_width : 20|7@0+ (0.1,0) [0|12.6] "m"  PAS
 SG_ HUT_OD_Obj0_Ground_Pos_X : 39|12@0+ (0.01,0) [0|40] "m"  PAS
 SG_ HUT_OD_Obj0_Ground_Pos_Y : 43|12@0+ (0.01,-20) [-20|20] "m"  PAS
 SG_ HTU_OD_Obj1_ID : 79|4@0+ (1,0) [0|9] ""  PAS
 SG_ HUT_OD_Obj1_type : 87|3@0+ (1,0) [0|7] ""  PAS
 SG_ HUT_OD_Obj1_Confidence : 75|4@0+ (0.1,0) [0|1] ""  PAS
 SG_ HUT_OD_Obj1_width : 84|7@0+ (0.1,0) [0|12.6] "m"  PAS
 SG_ HUT_OD_Obj1_Ground_Pos_X : 103|12@0+ (0.01,0) [0|40] "m"  PAS
 SG_ HUT_OD_Obj1_Ground_Pos_Y : 107|12@0+ (0.01,-20) [-20|20] "m"  PAS
 SG_ HUT_OD_Obj2_ID : 143|4@0+ (1,0) [0|9] ""  PAS
 SG_ HUT_OD_Obj2_type : 151|3@0+ (1,0) [0|7] ""  PAS
 SG_ HUT_OD_Obj2_Confidence : 139|4@0+ (0.1,0) [0|1] ""  PAS
 SG_ HUT_OD_Obj2_width : 148|7@0+ (0.1,0) [0|12.6] "m"  PAS
 SG_ HUT_OD_Obj2_Ground_Pos_X : 167|12@0+ (0.01,0) [0|40] "m"  PAS
 SG_ HUT_OD_Obj2_Ground_Pos_Y : 171|12@0+ (0.01,-20) [-20|20] "m"  PAS
 SG_ HUT_OD_Obj3_ID : 207|4@0+ (1,0) [0|9] ""  PAS
 SG_ HUT_OD_Obj3_type : 215|3@0+ (1,0) [0|7] ""  PAS
 SG_ HUT_OD_Obj3_Confidence : 203|4@0+ (0.1,0) [0|1] ""  PAS
 SG_ HUT_OD_Obj3_width : 212|7@0+ (0.1,0) [0|12.6] "m"  PAS
 SG_ HUT_OD_Obj3_Ground_Pos_X : 231|12@0+ (0.01,0) [0|40] "m"  PAS
 SG_ HUT_OD_Obj3_Ground_Pos_Y : 235|12@0+ (0.01,-20) [-20|20] "m"  PAS
 SG_ HUT_OD_Obj4_ID : 271|4@0+ (1,0) [0|9] ""  PAS
 SG_ HUT_OD_Obj4_type : 279|3@0+ (1,0) [0|7] ""  PAS
 SG_ HUT_OD_Obj4_Confidence : 267|4@0+ (0.1,0) [0|1] ""  PAS
 SG_ HUT_OD_Obj4_width : 276|7@0+ (0.1,0) [0|12.6] "m"  PAS
 SG_ HUT_OD_Obj4_Ground_Pos_X : 295|12@0+ (0.01,0) [0|40] "m"  PAS
 SG_ HUT_OD_Obj4_Ground_Pos_Y : 299|12@0+ (0.01,-20) [-20|20] "m"  PAS
 SG_ HUT_OD_Obj5_ID : 335|4@0+ (1,0) [0|9] ""  PAS
 SG_ HUT_OD_Obj5_type : 343|3@0+ (1,0) [0|7] ""  PAS
 SG_ HUT_OD_Obj5_Confidence : 331|4@0+ (0.1,0) [0|1] ""  PAS
 SG_ HUT_OD_Obj5_width : 340|7@0+ (0.1,0) [0|12.6] "m"  PAS
 SG_ HUT_OD_Obj5_Ground_Pos_X : 359|12@0+ (0.01,0) [0|40] "m"  PAS
 SG_ HUT_OD_Obj5_Ground_Pos_Y : 363|12@0+ (0.01,-20) [-20|20] "m"  PAS
 SG_ HUT_OD_Obj6_ID : 399|4@0+ (1,0) [0|9] ""  PAS
 SG_ HUT_OD_Obj6_type : 407|3@0+ (1,0) [0|7] ""  PAS
 SG_ HUT_OD_Obj6_Confidence : 395|4@0+ (0.1,0) [0|1] ""  PAS
 SG_ HUT_OD_Obj6_width : 404|7@0+ (0.1,0) [0|12.6] "m"  PAS
 SG_ HUT_OD_Obj6_Ground_Pos_X : 423|12@0+ (0.01,0) [0|40] "m"  PAS
 SG_ HUT_OD_Obj6_Ground_Pos_Y : 427|12@0+ (0.01,-20) [-20|20] "m"  PAS

BO_ 536 DCDC_FD2: 8 GW
 SG_ DCDC_ActSts : 27|4@0+ (1,0) [0|15] ""  PIS

BO_ 546 IFC_FD6: 64 IFC_IDC_L2
 SG_ IFC_Line01_DxStart : 15|15@0+ (0.01,0) [0|200] "m"  GW
 SG_ IFC_Line01_DxEnd : 16|15@0+ (0.01,0) [0|200] "m"  GW
 SG_ IFC_Line01_HeadingAngle : 33|9@0+ (0.01,-2) [-2|2] "rad"  GW
 SG_ IFC_Line02_HeadingAngle : 40|9@0+ (0.01,-2) [-2|2] "rad"  GW
 SG_ IFC_Line02_DxStart : 79|15@0+ (0.01,0) [0|200] "m"  GW
 SG_ IFC_Line02_DxEnd : 95|15@0+ (0.01,0) [0|200] "m"  GW
 SG_ IFC_Line03_DxStart : 111|15@0+ (0.01,0) [0|200] "m"  GW
 SG_ IFC_Line03_DxEnd : 143|15@0+ (0.01,0) [0|200] "m"  GW
 SG_ IFC_Line03_HeadingAngle : 144|9@0+ (0.01,-2) [-2|2] "rad"  GW
 SG_ IFC_Line04_DxStart : 167|15@0+ (0.01,0) [0|200] "m"  GW
 SG_ IFC_Line04_HeadingAngle : 168|9@0+ (0.01,-2) [-2|2] "rad"  GW
 SG_ IFC_Line04_DxEnd : 207|15@0+ (0.01,0) [0|200] "m"  GW
 SG_ IFC_Roadedge01_DxStart : 223|15@0+ (0.01,0) [0|200] "m"  GW
 SG_ IFC_Roadedge01_DxEnd : 239|15@0+ (0.01,0) [0|200] "m"  GW
 SG_ IFC_Roadedge01_HeadingAngle : 271|9@0+ (0.01,-2) [-2|2] "rad"  GW
 SG_ IFC_Roadedge02_DxStart : 278|15@0+ (0.01,0) [0|200] "m"  GW
 SG_ IFC_Roadedge02_DxEnd : 295|15@0+ (0.01,0) [0|200] "m"  GW
 SG_ IFC_Roadedge02_HeadingAngle : 296|9@0+ (0.01,-2) [-2|2] "rad"  GW
 SG_ CheckSum_IFC_HCM8 : 327|8@0+ (1,0) [0|255] ""  GW,HC
 SG_ Spots8HozlPosnLeAng : 335|10@0+ (0.08,-40) [-40|40] "degree"  GW,HC
 SG_ Spots8HozlPosnRiAng : 341|10@0+ (0.08,-40) [-40|40] "degree"  GW,HC
 SG_ Spots8Valid : 347|1@0+ (1,0) [0|1] ""  GW,HC
 SG_ Spots8Typ : 346|2@0+ (1,0) [0|3] ""  GW,HC
 SG_ Spots8Distance : 344|9@0+ (1,0) [0|510] "m"  GW,HC
 SG_ Spots8HozLeAngSpd : 367|8@0+ (0.125,-16) [-16|15.875] "DegPerSec"  GW,HC
 SG_ Spot8VertAng : 375|8@0+ (0.125,-5) [-5|26.875] ""  GW,HC
 SG_ Spots8TrackingInfo : 383|1@0+ (1,0) [0|1] ""  GW,HC
 SG_ Spots8VehObjClassn : 382|3@0+ (1,0) [0|7] ""  GW,HC
 SG_ RollingCounter_IFC_HCM8 : 379|4@0+ (1,0) [0|15] ""  GW,HC
 SG_ CheckSum_IFC_HCM9 : 391|8@0+ (1,0) [0|255] ""  GW,HC
 SG_ AmbLight : 399|1@0+ (1,0) [0|1] ""  GW,HC
 SG_ RoadIllumDetd : 398|1@0+ (1,0) [0|1] ""  GW,HC
 SG_ TrafficStyle : 397|2@0+ (1,0) [0|3] ""  GW,HC
 SG_ CameraSts : 395|2@0+ (1,0) [0|3] ""  GW,HC
 SG_ RollingCounter_IFC_HCM9 : 443|4@0+ (1,0) [0|15] ""  GW,HC

BO_ 551 AEB_FD2: 64 FR_IDC_L2
 SG_ Checksum_AEB2 : 71|8@0+ (1,0) [0|255] ""  GW
 SG_ AEB_PedResp : 79|1@0+ (1,0) [0|1] ""  GW
 SG_ AEB_VehResp : 78|1@0+ (1,0) [0|1] ""  GW
 SG_ FCW_Snvty : 77|2@0+ (1,0) [0|3] ""  GW
 SG_ AEB_JA_Resp : 75|1@0+ (1,0) [0|1] ""  GW
 SG_ RollingCounter_AEB2 : 123|4@0+ (1,0) [0|15] ""  GW
 SG_ Checksum_AEB3 : 135|8@0+ (1,0) [0|255] ""  GW
 SG_ AEB_VehTrig : 143|1@0+ (1,0) [0|1] ""  GW
 SG_ AEB_PedTrig : 142|1@0+ (1,0) [0|1] ""  GW
 SG_ FCW_AEB_VehFctSts : 138|2@0+ (1,0) [0|3] ""  GW
 SG_ FCW_AEB_PedFctSts : 151|2@0+ (1,0) [0|3] ""  GW
 SG_ FCW_Warn : 149|2@0+ (1,0) [0|3] ""  GW
 SG_ AEB_JAFuncSts : 147|2@0+ (1,0) [0|3] ""  GW
 SG_ AEB_JA_Warn : 145|2@0+ (1,0) [0|3] ""  GW
 SG_ AEB_JABrkTrig : 159|2@0+ (1,0) [0|3] ""  GW
 SG_ RollingCounter_AEB3 : 187|4@0+ (1,0) [0|15] ""  GW
 SG_ FreshnessValue_AEB_FD2 : 455|16@0+ (1,0) [0|65535] ""  GW
 SG_ MAC_Check_AEB_FD2 : 471|48@0+ (1,0) [0|281474976710655] ""  GW

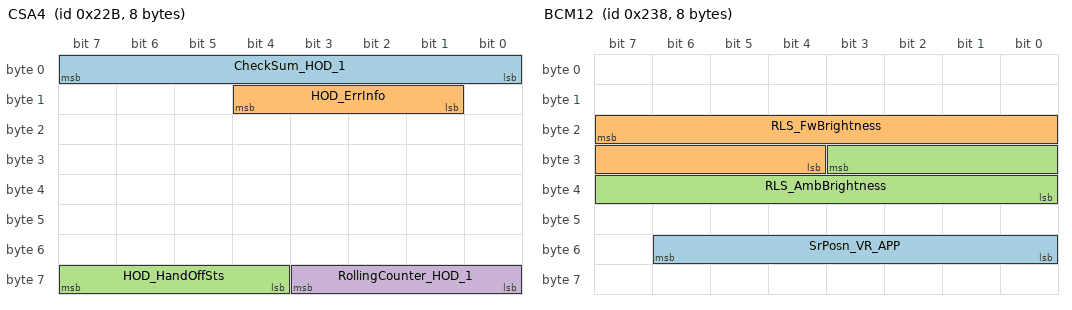
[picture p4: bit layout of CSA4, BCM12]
BO_ 555 CSA4: 8 GW
 SG_ CheckSum_HOD_1 : 7|8@0+ (1,0) [0|255] ""  IDC_L3
 SG_ HOD_ErrInfo : 12|4@0+ (1,0) [0|15] ""  IDC_L3
 SG_ HOD_HandOffSts : 63|4@0+ (1,0) [0|15] ""  IDC_L3
 SG_ RollingCounter_HOD_1 : 59|4@0+ (1,0) [0|15] ""  IDC_L3

BO_ 568 BCM12: 8 GW
 SG_ SrPosn_VR_APP : 54|7@0+ (1,0) [0|127] ""  AVP
 SG_ RLS_FwBrightness : 23|12@0+ (6,0) [0|24564] ""  AVP
 SG_ RLS_AmbBrightness : 27|12@0+ (20,0) [0|81880] ""  AVP

BO_ 573 IFC_FD2: 64 IFC_IDC_L2
 SG_ Checksum_IFC3 : 71|8@0+ (1,0) [0|255] ""  GW
 SG_ LDWResp : 79|1@0+ (1,0) [0|1] ""  GW
 SG_ LKAResp : 78|1@0+ (1,0) [0|1] ""  GW
 SG_ LCKResp : 77|1@0+ (1,0) [0|1] ""  GW
 SG_ ELKResp : 76|1@0+ (1,0) [0|1] ""  GW
 SG_ AESResp : 75|1@0+ (1,0) [0|1] ""  GW
 SG_ LDW_LKA_Snvty : 74|2@0+ (1,0) [0|3] ""  GW
 SG_ IFCHUTInterface : 72|1@0+ (1,0) [0|1] ""  GW
 SG_ ESS_PedResp : 87|1@0+ (1,0) [0|1] ""  GW
 SG_ ESS_VehResp : 86|1@0+ (1,0) [0|1] ""  GW
 SG_ LSSWarnFormResp : 85|2@0+ (1,0) [0|3] ""  GW
 SG_ LSSResp : 83|1@0+ (1,0) [0|1] ""  GW
 SG_ IntelligentEvaResp : 82|1@0+ (1,0) [0|1] ""  GW
 SG_ AESSts : 81|2@0+ (1,0) [0|3] ""  GW
 SG_ ESSSts : 95|2@0+ (1,0) [0|3] ""  GW
 SG_ AESErrSts : 93|1@0+ (1,0) [0|1] ""  GW
 SG_ ESSErrSts : 92|1@0+ (1,0) [0|1] ""  GW
 SG_ RollingCounter_IFC3 : 123|4@0+ (1,0) [0|15] ""  GW
 SG_ Checksum_IFC4 : 135|8@0+ (1,0) [0|255] ""  GW
 SG_ IFC_Handsoffwarn : 157|3@0+ (1,0) [0|7] ""  GW,FR
 SG_ IFCCalibrationSts : 154|2@0+ (1,0) [0|3] ""  GW
 SG_ CameraBlockageSts : 152|1@0+ (1,0) [0|1] ""  GW
 SG_ LDW_LKAWarn : 143|2@0+ (1,0) [0|3] ""  GW
 SG_ LSSIntervention : 141|3@0+ (1,0) [0|7] ""  GW
 SG_ LSSFuncSts : 138|3@0+ (1,0) [0|7] ""  GW
 SG_ ELKMainState : 151|3@0+ (1,0) [0|7] ""  GW
 SG_ LaneAvailability : 148|2@0+ (1,0) [0|3] ""  GW
 SG_ TJA_FollowSts : 146|2@0+ (1,0) [0|3] ""  GW
 SG_ LSSErrSts : 144|3@0+ (1,0) [0|7] ""  GW
 SG_ AESintervention : 191|2@0+ (1,0) [0|3] ""  GW
 SG_ ESSintervention : 189|2@0+ (1,0) [0|3] ""  GW
 SG_ ELKActSts : 167|2@0+ (1,0) [0|3] ""  GW
 SG_ IntelligentEvaActSts : 165|2@0+ (1,0) [0|3] ""  GW
 SG_ LCKStsIndcr : 163|2@0+ (1,0) [0|3] ""  GW
 SG_ RollingCounter_IFC4 : 187|4@0+ (1,0) [0|15] ""  GW
 SG_ Checksum_IFC5 : 199|8@0+ (1,0) [0|255] ""  GW
 SG_ IFC_LaneCurve : 207|12@0+ (1.5E-005,-0.030705) [-0.030705|0.030705] ""  GW,HAP
 SG_ IFC_LeLaneTyp : 211|3@0+ (1,0) [0|7] ""  GW,HAP
 SG_ IFC_RiLaneTyp : 208|3@0+ (1,0) [0|7] ""  GW,HAP
 SG_ IFC_NextLeLaneTyp : 221|3@0+ (1,0) [0|7] ""  GW,HAP
 SG_ IFC_NextRiLaneTyp : 218|3@0+ (1,0) [0|7] ""  GW,HAP
 SG_ IFC_LeLane_dy : 231|12@0+ (0.00390625,-8) [-8|7.9921875] ""  GW
 SG_ IFC_RiLane_dy : 235|12@0+ (0.00390625,-8) [-8|7.9921875] ""  GW
 SG_ RollingCounter_IFC5 : 251|4@0+ (1,0) [0|15] ""  GW
 SG_ Checksum_IFC6 : 263|8@0+ (1,0) [0|255] ""  GW
 SG_ IFC_NextLeLane_dy : 271|12@0+ (0.00390625,-8) [-8|7.9921875] ""  GW,HAP
 SG_ IFC_NextRiLane_dy : 275|12@0+ (0.00390625,-8) [-8|7.9921875] ""  GW,HAP
 SG_ RollingCounter_IFC6 : 315|4@0+ (1,0) [0|15] ""  GW

BO_ 576 IFC_FD4: 64 IFC_IDC_L2
 SG_ CheckSum_IFC_HCM1 : 7|8@0+ (1,0) [0|255] ""  GW,HC
 SG_ Spots1HozlPosnRiAng : 21|10@0+ (0.08,-40) [-40|40] "degree"  GW,HC
 SG_ Spots1HozlPosnLeAng : 15|10@0+ (0.08,-40) [-40|40] "degree"  GW,HC
 SG_ Spots1Valid : 27|1@0+ (1,0) [0|1] ""  GW,HC
 SG_ Spots1Typ : 26|2@0+ (1,0) [0|3] ""  GW,HC
 SG_ Spots1Distance : 24|9@0+ (1,0) [0|510] "m"  GW,HC
 SG_ Spots1HozLeAngSpd : 47|8@0+ (0.125,-16) [-16|15.875] "DegPerSec"  GW,HC
 SG_ Spot1VertAng : 55|8@0+ (0.125,-5) [-5|26.875] ""  GW,HC
 SG_ Spots1TrackingInfo : 63|1@0+ (1,0) [0|1] ""  GW,HC
 SG_ Spots1VehObjClassn : 62|3@0+ (1,0) [0|7] ""  GW,HC
 SG_ RollingCounter_IFC_HCM1 : 59|4@0+ (1,0) [0|15] ""  GW,HC
 SG_ CheckSum_IFC_HCM2 : 71|8@0+ (1,0) [0|255] ""  GW,HC
 SG_ Spots2HozlPosnLeAng : 79|10@0+ (0.08,-40) [-40|40] "degree"  GW,HC
 SG_ Spots2HozlPosnRiAng : 85|10@0+ (0.08,-40) [-40|40] "degree"  GW,HC
 SG_ Spots2Valid : 91|1@0+ (1,0) [0|1] ""  GW,HC
 SG_ Spots2Typ : 90|2@0+ (1,0) [0|3] ""  GW,HC
 SG_ Spots2Distance : 88|9@0+ (1,0) [0|510] "m"  GW,HC
 SG_ Spots2HozLeAngSpd : 111|8@0+ (0.125,-16) [-16|15.875] "DegPerSec"  GW,HC
 SG_ Spot2VertAng : 119|8@0+ (0.125,-5) [-5|26.875] ""  GW,HC
 SG_ Spots2TrackingInfo : 127|1@0+ (1,0) [0|1] ""  GW,HC
 SG_ Spots2VehObjClassn : 126|3@0+ (1,0) [0|7] ""  GW,HC
 SG_ RollingCounter_IFC_HCM2 : 123|4@0+ (1,0) [0|15] ""  GW,HC
 SG_ CheckSum_IFC_HCM3 : 135|8@0+ (1,0) [0|255] ""  GW,HC
 SG_ Spots3HozlPosnLeAng : 143|10@0+ (0.08,-40) [-40|40] "degree"  GW,HC
 SG_ Spots3HozlPosnRiAng : 149|10@0+ (0.08,-40) [-40|40] "degree"  GW,HC
 SG_ Spots3Valid : 155|1@0+ (1,0) [0|1] ""  GW,HC
 SG_ Spots3Typ : 154|2@0+ (1,0) [0|3] ""  GW,HC
 SG_ Spots3Distance : 152|9@0+ (1,0) [0|510] "m"  GW,HC
 SG_ Spots3HozLeAngSpd : 175|8@0+ (0.125,-16) [-16|15.875] "DegPerSec"  GW,HC
 SG_ Spot3VertAng : 183|8@0+ (0.125,-5) [-5|26.875] ""  GW,HC
 SG_ Spots3TrackingInfo : 191|1@0+ (1,0) [0|1] ""  GW,HC
 SG_ Spots3VehObjClassn : 190|3@0+ (1,0) [0|7] ""  GW,HC
 SG_ RollingCounter_IFC_HCM3 : 187|4@0+ (1,0) [0|15] ""  GW,HC
 SG_ CheckSum_IFC_HCM4 : 199|8@0+ (1,0) [0|255] ""  GW,HC
 SG_ Spots4HozlPosnLeAng : 207|10@0+ (0.08,-40) [-40|40] "degree"  GW,HC
 SG_ Spots4HozlPosnRiAng : 213|10@0+ (0.08,-40) [-40|40] "degree"  GW,HC
 SG_ Spots4Valid : 219|1@0+ (1,0) [0|1] ""  GW,HC
 SG_ Spots4Typ : 218|2@0+ (1,0) [0|3] ""  GW,HC
 SG_ Spots4Distance : 216|9@0+ (1,0) [0|510] "m"  GW,HC
 SG_ Spots4HozLeAngSpd : 239|8@0+ (0.125,-16) [-16|15.875] "DegPerSec"  GW,HC
 SG_ Spot4VertAng : 247|8@0+ (0.125,-5) [-5|26.875] ""  GW,HC
 SG_ Spots4TrackingInfo : 255|1@0+ (1,0) [0|1] ""  GW,HC
 SG_ Spots4VehObjClassn : 254|3@0+ (1,0) [0|7] ""  GW,HC
 SG_ RollingCounter_IFC_HCM4 : 251|4@0+ (1,0) [0|15] ""  GW,HC
 SG_ CheckSum_IFC_HCM5 : 263|8@0+ (1,0) [0|255] ""  GW,HC
 SG_ Spots5HozlPosnLeAng : 271|10@0+ (0.08,-40) [-40|40] "degree"  GW,HC
 SG_ Spots5HozlPosnRiAng : 277|10@0+ (0.08,-40) [-40|40] "degree"  GW,HC
 SG_ Spots5Valid : 283|1@0+ (1,0) [0|1] ""  GW,HC
 SG_ Spots5Typ : 282|2@0+ (1,0) [0|3] ""  GW,HC
 SG_ Spots5Distance : 280|9@0+ (1,0) [0|510] "m"  GW,HC
 SG_ Spots5HozLeAngSpd : 303|8@0+ (0.125,-16) [-16|15.875] "DegPerSec"  GW,HC
 SG_ Spot5VertAng : 311|8@0+ (0.125,-5) [-5|26.875] ""  GW,HC
 SG_ Spots5TrackingInfo : 319|1@0+ (1,0) [0|1] ""  GW,HC
 SG_ Spots5VehObjClassn : 318|3@0+ (1,0) [0|7] ""  GW,HC
 SG_ RollingCounter_IFC_HCM5 : 315|4@0+ (1,0) [0|15] ""  GW,HC
 SG_ CheckSum_IFC_HCM6 : 327|8@0+ (1,0) [0|255] ""  GW,HC
 SG_ Spots6HozlPosnLeAng : 335|10@0+ (0.08,-40) [-40|40] "degree"  GW,HC
 SG_ Spots6HozlPosnRiAng : 341|10@0+ (0.08,-40) [-40|40] "degree"  GW,HC
 SG_ Spots6Valid : 347|1@0+ (1,0) [0|1] ""  GW,HC
 SG_ Spots6Typ : 346|2@0+ (1,0) [0|3] ""  GW,HC
 SG_ Spots6Distance : 344|9@0+ (1,0) [0|510] "m"  GW,HC
 SG_ Spots6HozLeAngSpd : 367|8@0+ (0.125,-16) [-16|15.875] "DegPerSec"  GW,HC
 SG_ Spot6VertAng : 375|8@0+ (0.125,-5) [-5|26.875] ""  GW,HC
 SG_ Spots6TrackingInfo : 383|1@0+ (1,0) [0|1] ""  GW,HC
 SG_ Spots6VehObjClassn : 382|3@0+ (1,0) [0|7] ""  GW,HC
 SG_ RollingCounter_IFC_HCM6 : 379|4@0+ (1,0) [0|15] ""  GW,HC
 SG_ CheckSum_IFC_HCM7 : 391|8@0+ (1,0) [0|255] ""  GW,HC
 SG_ Spots7HozlPosnLeAng : 399|10@0+ (0.08,-40) [-40|40] "degree"  GW,HC
 SG_ Spots7HozlPosnRiAng : 405|10@0+ (0.08,-40) [-40|40] "degree"  GW,HC
 SG_ Spots7Valid : 411|1@0+ (1,0) [0|1] ""  GW,HC
 SG_ Spots7Typ : 410|2@0+ (1,0) [0|3] ""  GW,HC
 SG_ Spots7Distance : 408|9@0+ (1,0) [0|510] "m"  GW,HC
 SG_ Spots7HozLeAngSpd : 431|8@0+ (0.125,-16) [-16|15.875] "DegPerSec"  GW,HC
 SG_ Spot7VertAng : 439|8@0+ (0.125,-5) [-5|26.875] ""  GW,HC
 SG_ Spots7TrackingInfo : 447|1@0+ (1,0) [0|1] ""  GW,HC
 SG_ Spots7VehObjClassn : 446|3@0+ (1,0) [0|7] ""  GW,HC
 SG_ RollingCounter_IFC_HCM7 : 443|4@0+ (1,0) [0|15] ""  GW,HC

BO_ 579 HUT_FD3: 64 GW
 SG_ HUT_OD_Obj7_ID : 15|4@0+ (1,0) [0|9] ""  PAS
 SG_ HUT_OD_Obj7_type : 23|3@0+ (1,0) [0|7] ""  PAS
 SG_ HUT_OD_Obj7_Confidence : 11|4@0+ (0.1,0) [0|1] ""  PAS
 SG_ HUT_OD_Obj7_width : 20|7@0+ (0.1,0) [0|12.6] "m"  PAS
 SG_ HUT_OD_Obj7_Ground_Pos_X : 39|12@0+ (0.01,0) [0|40] "m"  PAS
 SG_ HUT_OD_Obj7_Ground_Pos_Y : 43|12@0+ (0.01,-20) [-20|20] "m"  PAS
 SG_ HUT_OD_WorkSts : 113|2@0+ (1,0) [0|3] ""  PAS
 SG_ HUT_OD_Obj_Timestamp : 79|16@0+ (1,0) [0|65535] "ms"  PAS
 SG_ HUT_FSD1_distance : 95|6@0+ (0.1,0) [0|6] "m"  PAS
 SG_ HUT_FSD2_distance : 89|6@0+ (0.1,0) [0|6] "m"  PAS
 SG_ HUT_FSD3_distance : 99|6@0+ (0.1,0) [0|6] "m"  PAS
 SG_ HUT_FSD4_distance : 109|6@0+ (0.1,0) [0|6] "m"  PAS
 SG_ HUT_FSD5_distance : 119|6@0+ (0.1,0) [0|6] "m"  PAS
 SG_ HUT_FSD6_distance : 143|6@0+ (0.1,0) [0|6] "m"  PAS
 SG_ HUT_FSD7_distance : 137|6@0+ (0.1,0) [0|6] "m"  PAS
 SG_ HUT_FSD8_distance : 147|6@0+ (0.1,0) [0|6] "m"  PAS
 SG_ HUT_FSD9_distance : 157|6@0+ (0.1,0) [0|6] "m"  PAS
 SG_ HUT_FSD10_distance : 167|6@0+ (0.1,0) [0|6] "m"  PAS
 SG_ HUT_FSD11_distance : 161|6@0+ (0.1,0) [0|6] "m"  PAS
 SG_ HUT_FSD12_distance : 171|6@0+ (0.1,0) [0|6] "m"  PAS
 SG_ HUT_FSD13_distance : 181|6@0+ (0.1,0) [0|6] "m"  PAS
 SG_ HUT_FSD14_distance : 207|6@0+ (0.1,0) [0|6] "m"  PAS
 SG_ HUT_FSD15_distance : 201|6@0+ (0.1,0) [0|6] "m"  PAS
 SG_ HUT_FSD16_distance : 211|6@0+ (0.1,0) [0|6] "m"  PAS
 SG_ HUT_FSD17_distance : 221|6@0+ (0.1,0) [0|6] "m"  PAS
 SG_ HUT_FSD18_distance : 231|6@0+ (0.1,0) [0|6] "m"  PAS
 SG_ NOH_Swt_Req : 335|1@0+ (1,0) [0|1] ""  IDC_L2
 SG_ NOH_Act_Req : 334|1@0+ (1,0) [0|1] ""  IDC_L2

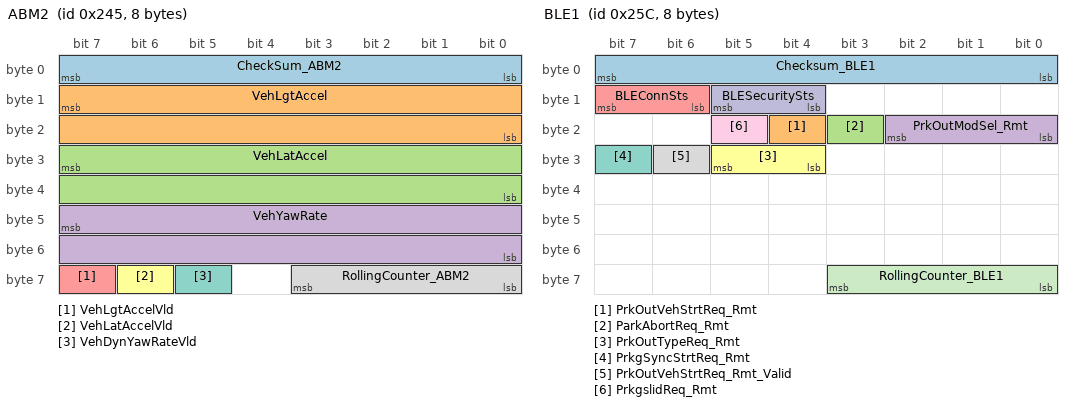
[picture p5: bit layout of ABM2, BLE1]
BO_ 581 ABM2: 8 GW
 SG_ CheckSum_ABM2 : 7|8@0+ (1,0) [0|255] ""  IFC,FR,RSDS_R,RSDS_L,AVP,HAP,PAS,CR_L,CR_R,IDC_L2,IDC_L3,LMU
 SG_ VehLgtAccel : 15|16@0+ (0.00098,-21.592) [-21.592|21.592] "m/s^2"  IFC,FR,RSDS_R,RSDS_L,AVP,HAP,PAS,CR_L,CR_R,IDC_L2,IDC_L3,LMU
 SG_ VehLatAccel : 31|16@0+ (0.00098,-21.592) [-21.592|21.592] "m/s^2"  IFC,FR,RSDS_R,RSDS_L,AVP,HAP,PAS,CR_L,CR_R,IDC_L2,IDC_L3,LMU
 SG_ VehYawRate : 47|16@0+ (0.00024,-2.093) [-2.093|2.093] "rad/s"  IFC,HC,FR,RSDS_R,RSDS_L,AVP,HAP,PAS,CR_L,CR_R,IDC_L2,IDC_L3,LMU
 SG_ VehLgtAccelVld : 63|1@0+ (1,0) [0|1] ""  IFC,FR,RSDS_R,RSDS_L,AVP,HAP,PAS,CR_L,CR_R,IDC_L2,IDC_L3,LMU
 SG_ VehLatAccelVld : 62|1@0+ (1,0) [0|1] ""  IFC,FR,RSDS_R,RSDS_L,AVP,HAP,PAS,CR_L,CR_R,IDC_L2,IDC_L3,LMU
 SG_ VehDynYawRateVld : 61|1@0+ (1,0) [0|1] ""  IFC,HC,FR,RSDS_R,RSDS_L,AVP,HAP,PAS,CR_L,CR_R,IDC_L2,IDC_L3,LMU
 SG_ RollingCounter_ABM2 : 59|4@0+ (1,0) [0|15] ""  IFC,FR,RSDS_R,RSDS_L,AVP,HAP,PAS,CR_L,CR_R,IDC_L2,IDC_L3,LMU

BO_ 584 HCU_PT7: 8 GW
 SG_ HCU_RdyLmpSts : 37|1@0+ (1,0) [0|1] ""  HC

BO_ 586 IDC_L3_FD2: 16 IDC_L3
 SG_ HWP_EmgyLightReq : 15|1@0+ (1,0) [0|1] ""  GW
 SG_ HWP_TurnlLightReq : 14|2@0+ (1,0) [0|3] ""  GW
 SG_ HWP_HornReq : 12|1@0+ (1,0) [0|1] ""  GW
 SG_ HWP_DippedBeamReq : 11|1@0+ (1,0) [0|1] ""  GW
 SG_ HWP_HiBeamtReq : 10|1@0+ (1,0) [0|1] ""  GW
 SG_ HWP_FFogLightReq : 9|1@0+ (1,0) [0|1] ""  GW
 SG_ HWP_RFogLightReq : 8|1@0+ (1,0) [0|1] ""  GW
 SG_ HWP_FWiperReq : 23|3@0+ (1,0) [0|7] ""  GW
 SG_ HWP_RWshrReq : 16|1@0+ (1,0) [0|1] ""  GW
 SG_ HWP_BrkLmpReq : 30|1@0+ (1,0) [0|1] ""  GW
 SG_ HWP_BackupReq : 29|1@0+ (1,0) [0|1] ""  GW
 SG_ HWP_CenCtrllockReq : 28|2@0+ (1,0) [0|3] ""  GW
 SG_ HWP_TrkReq : 26|2@0+ (1,0) [0|3] ""  GW
 SG_ HWP_AC_Req : 24|1@0+ (1,0) [0|1] ""  GW
 SG_ HWP_TarWind : 39|2@0+ (1,0) [0|3] ""  GW
 SG_ HWP_TarTemp : 37|5@0+ (1,0) [0|30] ""  GW
 SG_ HWP_WorkReq_KBCM : 47|3@0+ (1,0) [0|7] ""  GW
 SG_ HWP_WorkReqVld_KBCM : 32|1@0+ (1,0) [0|1] ""  GW
 SG_ HWP_TextWarn_AC : 44|4@0+ (1,0) [0|15] ""  GW
 SG_ FreshnessValue_IDC_L3_FD2 : 71|16@0+ (1,0) [0|65535] ""  GW
 SG_ MAC_Check_IDC_L3_FD2 : 87|48@0+ (1,0) [0|281474976710655] ""  GW

BO_ 589 DMS_FD1: 64 GW
 SG_ Checksum_DMS2 : 71|8@0+ (1,0) [0|255] ""  IDC_L2,IDC_L3
 SG_ DistrctnLvl_ACC : 95|3@0+ (1,0) [0|7] ""  FR,IDC_L2,IDC_L3
 SG_ DistrctnLvlQlty_ACC : 79|7@0+ (1,0) [0|100] "%"  FR,IDC_L2,IDC_L3
 SG_ DrowsnsLvl_ACC : 92|3@0+ (1,0) [0|7] ""  FR,IDC_L2,IDC_L3
 SG_ RollingCounter_DMS2 : 123|4@0+ (1,0) [0|15] ""  IDC_L2,IDC_L3
 SG_ Checksum_DMS3 : 135|8@0+ (1,0) [0|255] ""  IDC_L2,IDC_L3
 SG_ HeadPosnX : 143|11@0+ (1,-500) [-500|1000] "mm"  FR,IDC_L2
 SG_ HeadPosnY : 148|11@0+ (1,-500) [-500|500] "mm"  FR,IDC_L2
 SG_ HeadPosnZ : 153|11@0+ (1,-500) [-500|500] "mm"  FR,IDC_L2
 SG_ RollingCounter_DMS3 : 187|4@0+ (1,0) [0|15] ""  IDC_L2,IDC_L3
 SG_ Checksum_DMS5 : 263|8@0+ (1,0) [0|255] ""  IDC_L2,IDC_L3
 SG_ DMSSts : 303|3@0+ (1,0) [0|7] ""  FR,IDC_L2
 SG_ HeadDetn : 288|1@0+ (1,0) [0|1] ""  FR,AVP,IDC_L2,IDC_L3
 SG_ HeadYawAng : 271|8@0+ (1,-75) [-75|75] "degree"  FR,IDC_L2,IDC_L3
 SG_ HeadPitchAng : 279|8@0+ (1,-25) [-25|45] "degree"  FR,IDC_L2,IDC_L3
 SG_ HeadRollAng : 287|8@0+ (1,-45) [-45|45] "degree"  FR,IDC_L2,IDC_L3
 SG_ RollingCounter_DMS5 : 315|4@0+ (1,0) [0|15] ""  IDC_L2,IDC_L3
 SG_ Checksum_DMS6 : 327|8@0+ (1,0) [0|255] ""  IDC_L2,IDC_L3
 SG_ LEyeOpenSts : 375|2@0+ (1,0) [0|3] ""  FR,IDC_L2,IDC_L3
 SG_ LEyeOpenStsQlty : 351|7@0+ (1,0) [0|100] "%"  FR,IDC_L2,IDC_L3
 SG_ REyeOpenSts : 373|2@0+ (1,0) [0|3] ""  FR,IDC_L2,IDC_L3
 SG_ REyeOpenStsQlty : 359|7@0+ (1,0) [0|100] "%"  FR,IDC_L2,IDC_L3
 SG_ RobustGazeYawAng : 335|8@0+ (1,-90) [-90|90] "degree"  FR,IDC_L2
 SG_ RobustGazePitchAng : 343|8@0+ (1,-90) [-90|90] "degree"  FR,IDC_L2
 SG_ RollingCounter_DMS6 : 379|4@0+ (1,0) [0|15] ""  IDC_L2,IDC_L3

BO_ 604 BLE1: 8 GW
 SG_ Checksum_BLE1 : 7|8@0+ (1,0) [0|255] ""  AVP,HAP
 SG_ PrkOutVehStrtReq_Rmt : 20|1@0+ (1,0) [0|1] ""  AVP,HAP
 SG_ ParkAbortReq_Rmt : 19|1@0+ (1,0) [0|1] ""  AVP,HAP
 SG_ PrkOutModSel_Rmt : 18|3@0+ (1,0) [0|7] ""  AVP,HAP
 SG_ BLEConnSts : 15|2@0+ (1,0) [0|3] ""  AVP,HAP
 SG_ PrkOutTypeReq_Rmt : 29|2@0+ (1,0) [0|3] ""  AVP,HAP
 SG_ PrkgSyncStrtReq_Rmt : 31|1@0+ (1,0) [0|1] ""  AVP,HAP
 SG_ PrkOutVehStrtReq_Rmt_Valid : 30|1@0+ (1,0) [0|1] ""  AVP,HAP
 SG_ PrkgslidReq_Rmt : 21|1@0+ (1,0) [0|1] ""  AVP,HAP
 SG_ BLESecuritySts : 13|2@0+ (1,0) [0|3] ""  AVP,HAP
 SG_ RollingCounter_BLE1 : 59|4@0+ (1,0) [0|15] ""  AVP,HAP

BO_ 623 HUT32: 8 GW
 SG_ CheckSum_HUT32 : 7|8@0+ (1,0) [0|255] ""  AVP,HAP
 SG_ P2P_PrkgDirSwtReq : 54|1@0+ (1,0) [0|1] ""  HAP
 SG_ ScrnOpSts : 47|2@0+ (1,0) [0|3] ""  AVP,HAP,PAS
 SG_ XLvl : 23|11@0+ (1,0) [0|2046] ""  AVP,HAP,PAS
 SG_ YLvl : 26|11@0+ (1,0) [0|2046] ""  AVP,HAP,PAS
 SG_ DetVideoLost : 9|1@0+ (1,0) [0|1] ""  AVP,HAP,PAS
 SG_ PrkgCtrlModReqValid : 10|1@0+ (1,0) [0|1] ""  AVP,HAP
 SG_ PrkgCtrlModReq : 13|2@0+ (1,0) [0|3] ""  AVP,HAP
 SG_ ContnPrkgReqValid : 8|1@0+ (1,0) [0|1] ""  AVP,HAP
 SG_ ContnPrkgReq : 15|2@0+ (1,0) [0|3] ""  AVP,HAP
 SG_ PrkStraightSwtReq_HUT : 11|1@0+ (1,0) [0|1] ""  AVP,HAP
 SG_ PrkStraightSuspendOrFinishReq_HU : 28|2@0+ (1,0) [0|3] ""  AVP,HAP
 SG_ PrkStraightModSel_HUT : 63|3@0+ (1,0) [0|3] ""  AVP,HAP
 SG_ PrkStraightSts_HUT : 60|1@0+ (1,0) [0|1] ""  AVP,HAP
 SG_ PrkStraightStrtReq_HUT : 45|1@0+ (1,0) [0|1] ""  AVP,HAP
 SG_ PrkStraightVehStrtReq_HUT_Valid : 44|1@0+ (1,0) [0|1] ""  AVP,HAP
 SG_ PrkStraightContinueReq_HUT : 55|1@0+ (1,0) [0|1] ""  AVP,HAP
 SG_ RollingCounter_HUT32 : 59|4@0+ (1,0) [0|15] ""  AVP,HAP

BO_ 628 HAP_FD2: 64 AVP_HAP
 SG_ AutoAVMSwtSet_Sts : 83|1@0+ (1,0) [0|1] ""  GW
 SG_ AVM_CurrSts : 79|2@0+ (1,0) [0|3] ""  GW
 SG_ GuidOvlSts : 95|2@0+ (1,0) [0|3] ""  GW
 SG_ FrntCamInpFailSts : 108|1@0+ (1,0) [0|1] ""  GW
 SG_ RearCamInpFailSts : 109|1@0+ (1,0) [0|1] ""  GW
 SG_ LeCamInpFailSts : 110|1@0+ (1,0) [0|1] ""  GW
 SG_ RiCamInpFailSts : 111|1@0+ (1,0) [0|1] ""  GW
 SG_ EolNotCmpltd : 107|1@0+ (1,0) [0|1] ""  GW
 SG_ OvlOpFailSts : 105|1@0+ (1,0) [0|1] ""  GW
 SG_ LaneCalSts : 101|2@0+ (1,0) [0|3] ""  GW
 SG_ RadarDispSts : 93|2@0+ (1,0) [0|3] ""  GW
 SG_ LaneCalFltSts : 99|3@0+ (1,0) [0|7] ""  GW
 SG_ AutoViewChgFuncSts : 84|1@0+ (1,0) [0|1] ""  GW
 SG_ CarMdlTrsprcySts : 103|2@0+ (1,0) [0|3] ""  GW
 SG_ CarMdlDispSts : 85|1@0+ (1,0) [0|1] ""  GW
 SG_ CurrCalResultSts : 96|1@0+ (1,0) [0|1] ""  GW
 SG_ MdlColrSts : 91|4@0+ (1,0) [0|15] ""  GW
 SG_ SigViewIndcn : 77|6@0+ (1,0) [0|63] ""  GW
 SG_ HAP_DispCmd : 127|1@0+ (1,0) [0|1] ""  GW
 SG_ AVM_3DAngSts : 104|9@0+ (1,0) [0|360] "deg"  GW
 SG_ MOD_WorkSts : 87|1@0+ (1,0) [0|1] ""  GW
 SG_ MOD_AlarmSts : 86|1@0+ (1,0) [0|1] ""  GW
 SG_ DVRWorkSts : 126|2@0+ (1,0) [0|3] ""  GW
 SG_ HAP_Hmi_Index : 143|4@0+ (1,0) [0|15] ""  GW

CM_ SG_ 96 HCU_BrkPedalSts "C";
CM_ SG_ 96 HCU_PowertrainSts "A";
CM_ SG_ 161 ACC_TimeGap_IncSetSwt "A";
CM_ SG_ 161 ACC_TimeGap_DecSetSwt "A";
CM_ SG_ 161 CC_ACC_CRUISE_OFFSwt "A";
CM_ SG_ 161 CC_ACC_CANCEL_OFFSwt "A";
CM_ SG_ 161 CC_ACC_IncSetSpd_ResuSwt "A";
CM_ SG_ 161 CC_ACC_DecSetSpd_SetSwt "A";
CM_ SG_ 161 CC_ACCSwtErr "A";
CM_ SG_ 161 HWA_OK_OFFSwt "B";
CM_ SG_ 311 VehSpdVld "C";
CM_ SG_ 311 VehSpd "C";
CM_ SG_ 347 HAVP_WorkSts "B";
CM_ SG_ 347 PAVP_Status "B";
CM_ SG_ 474 UserDefinedParkCmd "自选车位功能";
CM_ SG_ 474 UserDefPrkMenuSelCmd "自选车位功能";
BA_DEF_  "Manufacturer" STRING ;
BA_DEF_  "DBName" STRING ;
BA_DEF_  "BusType" STRING ;
BA_DEF_  "GenEnvVarEndingDsp" STRING ;
BA_DEF_  "GenEnvVarEndingSnd" STRING ;
BA_DEF_  "GenEnvVarPrefix" STRING ;
BA_DEF_  "GenNWMApBusSleep" STRING ;
BA_DEF_  "GenNWMApCanNormal" STRING ;
BA_DEF_  "GenNWMApCanOff" STRING ;
BA_DEF_  "GenNWMApCanOn" STRING ;
BA_DEF_  "GenNWMApCanSleep" STRING ;
BA_DEF_  "GenNWMApCanWakeUp" STRING ;
BA_DEF_  "GenNWMGotoMode_Awake" STRING ;
BA_DEF_  "GenNWMGotoMode_BusSleep" STRING ;
BA_DEF_  "GenNWMTalkNM" STRING ;
BA_DEF_  "NmBaseAddress" HEX 1152 1279;
BA_DEF_ BU_  "NodeLayerModules" STRING ;
BA_DEF_ BU_  "NmCAN" INT 0 2;
BA_DEF_ BU_  "ILUsed" ENUM  "No","Yes";
BA_DEF_ BO_  "DiagState" ENUM  "No","Yes";
BA_DEF_ BO_  "NmMessage" ENUM  "no","yes";
BA_DEF_ BO_  "GenMsgILSupport" ENUM  "No","Yes";
BA_DEF_ BO_  "GenMsgCycleTime" INT 0 65535;
BA_DEF_ BO_  "GenMsgMinAcceptLength" INT 0 8;
BA_DEF_ BO_  "GenMsgSendType" ENUM  "Cyclic","CyclicAndSpontanX","Event";
BA_DEF_ BO_  "CANFD_BRS" ENUM  "0","1";
BA_DEF_ BO_  "VFrameFormat" ENUM  "StandardCAN","ExtendedCAN","reserved","reserved","reserved","reserved","reserved","reserved","reserved","reserved","reserved","reserved","reserved","reserved","StandardCAN_FD","ExtendedCAN_FD";
BA_DEF_ SG_  "GenSigEnvVarType" ENUM  "undef","int","float";
BA_DEF_ SG_  "GenSigSendType" ENUM  "Cyclic","OnWrite","OnWriteWithRepetition","OnChange","OnChangeWithRepetition","IfActive","IfActiveWithRepetition","NoSigSendType","NotUsed","NotUsed","NotUsed","NotUsed","NotUsed";
BA_DEF_ SG_  "GenSigStartValue" FLOAT 0 1215752192;
BA_DEF_ SG_  "SystemSignalLongSymbol" STRING ;
BA_DEF_DEF_  "Manufacturer" "GWM";
BA_DEF_DEF_  "DBName" "V71_001_021MM01 C_Matrix for  ADAS_CANFD_V4_3";
BA_DEF_DEF_  "BusType" "";
BA_DEF_DEF_  "GenEnvVarEndingDsp" "_d";
BA_DEF_DEF_  "GenEnvVarEndingSnd" "_s";
BA_DEF_DEF_  "GenEnvVarPrefix" "c";
BA_DEF_DEF_  "GenNWMApBusSleep" "apBusSleep()";
BA_DEF_DEF_  "GenNWMApCanNormal" "apCanNormal()";
BA_DEF_DEF_  "GenNWMApCanOff" "apCanOff()";
BA_DEF_DEF_  "GenNWMApCanOn" "apCanOn()";
BA_DEF_DEF_  "GenNWMApCanSleep" "apCanSleep()";
BA_DEF_DEF_  "GenNWMApCanWakeUp" "apCanWakeUp()";
BA_DEF_DEF_  "GenNWMGotoMode_Awake" "GotoMode_Awake()";
BA_DEF_DEF_  "GenNWMGotoMode_BusSleep" "GotoMode_BusSleep()";
BA_DEF_DEF_  "GenNWMTalkNM" "TalkNM()";
BA_DEF_DEF_  "NmBaseAddress" 1152;
BA_DEF_DEF_  "NodeLayerModules" "CANoeILNLVector.dll";
BA_DEF_DEF_  "NmCAN" 1;
BA_DEF_DEF_  "ILUsed" "Yes";
BA_DEF_DEF_  "DiagState" "No";
BA_DEF_DEF_  "NmMessage" "no";
BA_DEF_DEF_  "GenMsgILSupport" "Yes";
BA_DEF_DEF_  "GenMsgCycleTime" 10;
BA_DEF_DEF_  "GenMsgMinAcceptLength" 8;
BA_DEF_DEF_  "GenMsgSendType" "Cyclic";
BA_DEF_DEF_  "CANFD_BRS" "1";
BA_DEF_DEF_  "VFrameFormat" "StandardCAN";
BA_DEF_DEF_  "GenSigEnvVarType" "undef";
BA_DEF_DEF_  "GenSigSendType" "Cyclic";
BA_DEF_DEF_  "GenSigStartValue" 0;
BA_DEF_DEF_  "SystemSignalLongSymbol" "";
BA_ "BusType" "CAN FD";
BA_ "DBName" "V71_001_021MM01C_MatrixforADAS_C";
BA_ "GenMsgCycleTime" BO_ 74 0;
BA_ "GenMsgSendType" BO_ 74 2;
BA_ "VFrameFormat" BO_ 74 14;
BA_ "VFrameFormat" BO_ 96 14;
BA_ "VFrameFormat" BO_ 121 14;
BA_ "VFrameFormat" BO_ 159 14;
BA_ "VFrameFormat" BO_ 161 14;
BA_ "VFrameFormat" BO_ 211 14;
BA_ "GenMsgCycleTime" BO_ 259 20;
BA_ "VFrameFormat" BO_ 259 14;
BA_ "VFrameFormat" BO_ 273 14;
BA_ "GenMsgCycleTime" BO_ 288 20;
BA_ "VFrameFormat" BO_ 288 14;
BA_ "GenMsgCycleTime" BO_ 299 20;
BA_ "VFrameFormat" BO_ 299 14;
BA_ "GenMsgCycleTime" BO_ 303 20;
BA_ "VFrameFormat" BO_ 303 14;
BA_ "GenMsgCycleTime" BO_ 311 20;
BA_ "VFrameFormat" BO_ 311 14;
BA_ "GenMsgCycleTime" BO_ 315 20;
BA_ "VFrameFormat" BO_ 315 14;
BA_ "GenMsgCycleTime" BO_ 323 20;
BA_ "VFrameFormat" BO_ 323 14;
BA_ "GenMsgCycleTime" BO_ 327 20;
BA_ "VFrameFormat" BO_ 327 14;
BA_ "GenMsgCycleTime" BO_ 344 20;
BA_ "VFrameFormat" BO_ 344 14;
BA_ "GenMsgCycleTime" BO_ 347 20;
BA_ "VFrameFormat" BO_ 347 14;
BA_ "GenMsgCycleTime" BO_ 350 20;
BA_ "VFrameFormat" BO_ 350 14;
BA_ "GenMsgCycleTime" BO_ 357 20;
BA_ "VFrameFormat" BO_ 357 14;
BA_ "GenMsgCycleTime" BO_ 367 20;
BA_ "VFrameFormat" BO_ 367 14;
BA_ "GenMsgCycleTime" BO_ 395 20;
BA_ "VFrameFormat" BO_ 395 14;
BA_ "GenMsgCycleTime" BO_ 411 50;
BA_ "VFrameFormat" BO_ 411 14;
BA_ "GenMsgCycleTime" BO_ 412 50;
BA_ "VFrameFormat" BO_ 412 14;
BA_ "GenMsgCycleTime" BO_ 415 50;
BA_ "VFrameFormat" BO_ 415 14;
BA_ "GenMsgCycleTime" BO_ 416 50;
BA_ "VFrameFormat" BO_ 416 14;
BA_ "GenMsgCycleTime" BO_ 474 0;
BA_ "GenMsgSendType" BO_ 474 2;
BA_ "VFrameFormat" BO_ 474 14;
BA_ "GenMsgCycleTime" BO_ 493 0;
BA_ "GenMsgSendType" BO_ 493 2;
BA_ "VFrameFormat" BO_ 493 14;
BA_ "GenMsgCycleTime" BO_ 494 0;
BA_ "GenMsgSendType" BO_ 494 2;
BA_ "VFrameFormat" BO_ 494 14;
BA_ "GenMsgCycleTime" BO_ 515 50;
BA_ "VFrameFormat" BO_ 515 14;
BA_ "GenMsgCycleTime" BO_ 536 50;
BA_ "VFrameFormat" BO_ 536 14;
BA_ "GenMsgCycleTime" BO_ 546 50;
BA_ "VFrameFormat" BO_ 546 14;
BA_ "GenMsgCycleTime" BO_ 551 50;
BA_ "VFrameFormat" BO_ 551 14;
BA_ "GenMsgCycleTime" BO_ 555 50;
BA_ "VFrameFormat" BO_ 555 14;
BA_ "GenMsgCycleTime" BO_ 568 50;
BA_ "VFrameFormat" BO_ 568 14;
BA_ "GenMsgCycleTime" BO_ 573 50;
BA_ "VFrameFormat" BO_ 573 14;
BA_ "GenMsgCycleTime" BO_ 576 50;
BA_ "VFrameFormat" BO_ 576 14;
BA_ "GenMsgCycleTime" BO_ 579 50;
BA_ "VFrameFormat" BO_ 579 14;
BA_ "GenMsgCycleTime" BO_ 581 20;
BA_ "VFrameFormat" BO_ 581 14;
BA_ "GenMsgCycleTime" BO_ 584 50;
BA_ "VFrameFormat" BO_ 584 14;
BA_ "GenMsgCycleTime" BO_ 586 50;
BA_ "VFrameFormat" BO_ 586 14;
BA_ "GenMsgCycleTime" BO_ 589 50;
BA_ "VFrameFormat" BO_ 589 14;
BA_ "GenMsgCycleTime" BO_ 604 50;
BA_ "VFrameFormat" BO_ 604 14;
BA_ "GenMsgCycleTime" BO_ 623 50;
BA_ "VFrameFormat" BO_ 623 14;
BA_ "GenMsgCycleTime" BO_ 628 50;
BA_ "VFrameFormat" BO_ 628 14;
BA_ "GenSigSendType" SG_ 74 LaneCalActvtCmd 10;
BA_ "GenSigSendType" SG_ 74 MODChgReq 10;
BA_ "GenSigSendType" SG_ 74 Radar_DispCmd 10;
BA_ "GenSigSendType" SG_ 74 Guid_Ovl_Display_Cmd 10;
BA_ "GenSigSendType" SG_ 74 Sgl_View_Sel 10;
BA_ "GenSigSendType" SG_ 74 SwToFieldCalRstCmd 10;
BA_ "GenSigSendType" SG_ 74 AutoViewChgCmd 10;
BA_ "GenSigSendType" SG_ 74 MdlColrChgCmd 10;
BA_ "GenSigSendType" SG_ 74 CarMdlTrsprcySwtCmd 10;
BA_ "GenSigSendType" SG_ 74 CarMdlDispCmd 10;
BA_ "GenSigSendType" SG_ 74 AutoAVMSwSet_Cmd 10;
BA_ "GenSigSendType" SG_ 74 FPAS_AutoModSwt 10;
BA_ "GenSigSendType" SG_ 74 MEBSwtSet 10;
BA_ "GenSigSendType" SG_ 74 WshSoftSwt 10;
BA_ "GenSigSendType" SG_ 74 View_SoftswitchCmd 10;
BA_ "GenSigStartValue" SG_ 96 HCU_AccelPedalPosn_DiagValid 1;
BA_ "GenSigStartValue" SG_ 96 ActWheelTrqDmd 1200;
BA_ "GenSigStartValue" SG_ 96 MaxPsblWheelTrq 300;
BA_ "GenSigStartValue" SG_ 96 TotWheelTrq 1200;
BA_ "GenSigStartValue" SG_ 96 MinPsblWheelTrq 300;
BA_ "GenSigStartValue" SG_ 273 EngSpdVldty 2;
BA_ "GenSigStartValue" SG_ 288 WssFLEdgesSumVld 1;
BA_ "GenSigStartValue" SG_ 288 WssFREdgesSumVld 1;
BA_ "GenSigStartValue" SG_ 288 WssRLEdgesSumVld 1;
BA_ "GenSigStartValue" SG_ 288 WssRREdgesSumVld 1;
BA_ "GenSigStartValue" SG_ 299 IFCTrqOvlCmdProtnValue 7169;
BA_ "GenSigStartValue" SG_ 299 IFCTrqOvlCmdReqValue 1023;
BA_ "GenSigStartValue" SG_ 299 IFCAngCmdReqValue 7800;
BA_ "GenSigStartValue" SG_ 299 IFCAngCmdReqProtnValue 7169;
BA_ "GenSigStartValue" SG_ 303 HCU_GearSts 14;
BA_ "GenSigStartValue" SG_ 311 EngTrqReq 1200;
BA_ "GenSigStartValue" SG_ 311 ESP_MasterCylBrkPressVld 1;
BA_ "GenSigStartValue" SG_ 311 ABSFailSts 1;
BA_ "GenSigStartValue" SG_ 315 WssFLEdgesSumVld 1;
BA_ "GenSigStartValue" SG_ 315 WssFREdgesSumVld 1;
BA_ "GenSigStartValue" SG_ 315 WssRLEdgesSumVld 1;
BA_ "GenSigStartValue" SG_ 315 WssRREdgesSumVld 1;
BA_ "GenSigStartValue" SG_ 323 Longctrl_ModSts 1;
BA_ "GenSigStartValue" SG_ 323 HWP_AngCmdReqVal_L2 7800;
BA_ "GenSigStartValue" SG_ 327 EPS_TrqSnsrSts 1;
BA_ "GenSigStartValue" SG_ 327 EPS_DSTCtrlSts 1;
BA_ "GenSigStartValue" SG_ 327 EPS_DrvInpTrqVal_HighReslolution 2047;
BA_ "GenSigStartValue" SG_ 344 HWP_AngCmdReqVal 7800;
BA_ "GenSigStartValue" SG_ 344 HWP_TrqOvlCmdProtnValue 7169;
BA_ "GenSigStartValue" SG_ 344 HWP_TrqOvlCmdReqValue 1023;
BA_ "GenSigStartValue" SG_ 344 HWP_WorkReqVld 1;
BA_ "GenSigStartValue" SG_ 344 HWP_TgtGearReqVld 1;
BA_ "GenSigStartValue" SG_ 344 HWP_Lgtctrl_EngTrqReq 32767;
BA_ "GenSigStartValue" SG_ 344 HWP_EngTrqReqActvVld 1;
BA_ "GenSigStartValue" SG_ 344 HWP_Lgtctrl_EngTrqReqVld 1;
BA_ "GenSigStartValue" SG_ 344 HWP_Lgt_HCUTrqReqVld 1;
BA_ "GenSigStartValue" SG_ 344 HWP_Lgt_HCUTrqReqActvVld 1;
BA_ "GenSigStartValue" SG_ 347 APS_ProcBar 127;
BA_ "GenSigStartValue" SG_ 347 MEB_BrkgReqValue 200;
BA_ "GenSigStartValue" SG_ 347 HAVP_FuncSts 2;
BA_ "GenSigStartValue" SG_ 347 PAVP_FuncSts 1;
BA_ "GenSigStartValue" SG_ 350 CR_ObjSts_Le 2;
BA_ "GenSigStartValue" SG_ 350 CR_ObjDistY_Le 128;
BA_ "GenSigStartValue" SG_ 350 CR_ObjRelAccelX_Le 512;
BA_ "GenSigStartValue" SG_ 350 CR_ObjSts_Ri 2;
BA_ "GenSigStartValue" SG_ 350 CR_ObjDistY_Ri 128;
BA_ "GenSigStartValue" SG_ 350 CR_ObjRelAccelX_Ri 512;
BA_ "GenSigStartValue" SG_ 350 CR_ObjRelAccelY_Ri 512;
BA_ "GenSigStartValue" SG_ 350 CR_ObjRelVelY_Ri 64;
BA_ "GenSigStartValue" SG_ 350 CR_ObjRelAccelY_Le 512;
BA_ "GenSigStartValue" SG_ 350 CR_ObjRelVelY_Le 64;
BA_ "GenSigStartValue" SG_ 367 RSDS_ObjRelAccelY_Le 512;
BA_ "GenSigStartValue" SG_ 367 RSDS_BrkgReqVal 200;
BA_ "GenSigStartValue" SG_ 367 LeTarSts 2;
BA_ "GenSigStartValue" SG_ 367 ObjLatPosnCurvLe 128;
BA_ "GenSigStartValue" SG_ 367 ObjLatSpdCurvLe 64;
BA_ "GenSigStartValue" SG_ 367 ObjTTCLe 127;
BA_ "GenSigStartValue" SG_ 367 RiTarSts 2;
BA_ "GenSigStartValue" SG_ 367 ObjLatPosnCurvRi 128;
BA_ "GenSigStartValue" SG_ 367 ObjLatSpdCurvRi 64;
BA_ "GenSigStartValue" SG_ 367 ObjTTCRi 127;
BA_ "GenSigStartValue" SG_ 367 RSDS_ObjRelAccelX_Le 512;
BA_ "GenSigStartValue" SG_ 367 RSDS_ObjRelAccelX_Ri 512;
BA_ "GenSigStartValue" SG_ 367 RSDS_ObjRelAccelY_Ri 512;
BA_ "GenSigStartValue" SG_ 415 IFC_Line01_Dy 2825;
BA_ "GenSigStartValue" SG_ 415 IFC_Line01_Curv 15625;
BA_ "GenSigStartValue" SG_ 415 IFC_Line01_CurvChange 480000;
BA_ "GenSigStartValue" SG_ 415 IFC_Line02_Dy 2825;
BA_ "GenSigStartValue" SG_ 415 IFC_Line02_Curv 15625;
BA_ "GenSigStartValue" SG_ 415 IFC_Line02_CurvChange 480000;
BA_ "GenSigStartValue" SG_ 415 IFC_Line03_Dy 2825;
BA_ "GenSigStartValue" SG_ 415 IFC_Line03_Curv 15625;
BA_ "GenSigStartValue" SG_ 415 IFC_Line03_CurvChange 480000;
BA_ "GenSigStartValue" SG_ 415 IFC_Line04_Dy 2825;
BA_ "GenSigStartValue" SG_ 415 IFC_Line04_Curv 15625;
BA_ "GenSigStartValue" SG_ 415 IFC_Line04_CurvChange 480000;
BA_ "GenSigStartValue" SG_ 415 IFC_Roadedge01_Dy 2825;
BA_ "GenSigStartValue" SG_ 415 IFC_Roadedge01_Curv 15625;
BA_ "GenSigStartValue" SG_ 415 IFC_Roadedge01_CurvChange 480000;
BA_ "GenSigStartValue" SG_ 415 IFC_Roadedge02_Dy 2825;
BA_ "GenSigStartValue" SG_ 415 IFC_Roadedge02_Curv 15625;
BA_ "GenSigStartValue" SG_ 415 IFC_Roadedge02_CurvChange 480000;
BA_ "GenSigSendType" SG_ 474 HUT_HAVP_APA_Permit 10;
BA_ "GenSigSendType" SG_ 474 HUT_HAVP_Return_Btn 10;
BA_ "GenSigSendType" SG_ 474 HUT_HAVP_Set_Starting 10;
BA_ "GenSigSendType" SG_ 474 HUT_HAVP_SelfParLot_Ending 10;
BA_ "GenSigSendType" SG_ 474 HUT_HAVP_Comfirm_Btn 10;
BA_ "GenSigSendType" SG_ 474 HUT_HAVP_Learning_Set_ParkLot 10;
BA_ "GenSigSendType" SG_ 474 HUT_HAVP_Set_Path_Ending 10;
BA_ "GenSigSendType" SG_ 474 HUT_HAVP_LearningTypeSele 10;
BA_ "GenSigSendType" SG_ 474 HUT_HAVP_Path_Delete 10;
BA_ "GenSigSendType" SG_ 474 HUT_HAVP_Path_Select 10;
BA_ "GenSigSendType" SG_ 474 HUT_HAVP_Path_SetTop 10;
BA_ "GenSigSendType" SG_ 474 SlotNum_VR 10;
BA_ "GenSigSendType" SG_ 474 HUT_PAVP_Confirm 10;
BA_ "GenSigSendType" SG_ 474 HUT_PAVP_DropOff_Area_req 10;
BA_ "GenSigSendType" SG_ 474 HUT_PAVP_PathList_Req 10;
BA_ "GenSigSendType" SG_ 474 UserDefinedParkCmd 10;
BA_ "GenSigSendType" SG_ 474 UserDefPrkMenuSelCmd 10;
BA_ "GenSigSendType" SG_ 493 PrkInDirChoice 10;
BA_ "GenSigSendType" SG_ 493 PathLrngFinshCmd 10;
BA_ "GenSigSendType" SG_ 493 PathLrngStartCmd 10;
BA_ "GenSigSendType" SG_ 493 SelPrkOutDirReq 10;
BA_ "GenSigSendType" SG_ 493 StartPrkgPath2Cmd 10;
BA_ "GenSigSendType" SG_ 493 DeletePath2Cmd 10;
BA_ "GenSigSendType" SG_ 493 StartPrkgPath1Cmd 10;
BA_ "GenSigSendType" SG_ 493 DeletePath1Cmd 10;
BA_ "GenSigSendType" SG_ 493 ParkMdlCmd 10;
BA_ "GenSigSendType" SG_ 493 BackReq_APS 10;
BA_ "GenSigSendType" SG_ 493 SelPrkgFctnCmd 10;
BA_ "GenSigSendType" SG_ 493 P2P_PrkgDirectSwtCmd 10;
BA_ "GenSigSendType" SG_ 494 SDWSwtSet 10;
BA_ "GenSigSendType" SG_ 494 APSSwtReq_VR 10;
BA_ "GenSigSendType" SG_ 494 APSPrkgTypSeln 10;
BA_ "GenSigStartValue" SG_ 536 DCDC_ActSts 8;
BA_ "GenSigStartValue" SG_ 546 IFC_Line01_HeadingAngle 201;
BA_ "GenSigStartValue" SG_ 546 IFC_Line02_HeadingAngle 201;
BA_ "GenSigStartValue" SG_ 546 IFC_Line03_HeadingAngle 201;
BA_ "GenSigStartValue" SG_ 546 IFC_Line04_HeadingAngle 201;
BA_ "GenSigStartValue" SG_ 546 IFC_Roadedge01_HeadingAngle 201;
BA_ "GenSigStartValue" SG_ 546 IFC_Roadedge02_HeadingAngle 201;
BA_ "GenSigStartValue" SG_ 551 AEB_PedResp 1;
BA_ "GenSigStartValue" SG_ 551 AEB_VehResp 1;
BA_ "GenSigStartValue" SG_ 551 AEB_JA_Resp 1;
BA_ "GenSigStartValue" SG_ 555 HOD_ErrInfo 15;
BA_ "GenSigStartValue" SG_ 555 HOD_HandOffSts 15;
BA_ "GenSigStartValue" SG_ 568 SrPosn_VR_APP 127;
BA_ "GenSigStartValue" SG_ 573 IFC_LaneCurve 2047;
BA_ "GenSigStartValue" SG_ 573 IFC_LeLane_dy 2496;
BA_ "GenSigStartValue" SG_ 573 IFC_RiLane_dy 2496;
BA_ "GenSigStartValue" SG_ 573 IFC_NextLeLane_dy 2496;
BA_ "GenSigStartValue" SG_ 573 IFC_NextRiLane_dy 2496;
BA_ "GenSigStartValue" SG_ 581 VehLgtAccel 22033;
BA_ "GenSigStartValue" SG_ 581 VehLatAccel 22033;
BA_ "GenSigStartValue" SG_ 581 VehYawRate 8721;
BA_ "GenSigStartValue" SG_ 586 HWP_WorkReqVld_KBCM 1;
BA_ "GenSigStartValue" SG_ 589 DistrctnLvl_ACC 7;
BA_ "GenSigStartValue" SG_ 589 DistrctnLvlQlty_ACC 127;
BA_ "GenSigStartValue" SG_ 589 DrowsnsLvl_ACC 7;
BA_ "GenSigStartValue" SG_ 589 HeadPosnX 2047;
BA_ "GenSigStartValue" SG_ 589 HeadPosnY 2047;
BA_ "GenSigStartValue" SG_ 589 HeadPosnZ 2047;
BA_ "GenSigStartValue" SG_ 589 DMSSts 7;
BA_ "GenSigStartValue" SG_ 589 HeadYawAng 255;
BA_ "GenSigStartValue" SG_ 589 HeadPitchAng 255;
BA_ "GenSigStartValue" SG_ 589 HeadRollAng 255;
BA_ "GenSigStartValue" SG_ 589 LEyeOpenSts 2;
BA_ "GenSigStartValue" SG_ 589 LEyeOpenStsQlty 100;
BA_ "GenSigStartValue" SG_ 589 REyeOpenSts 2;
BA_ "GenSigStartValue" SG_ 589 REyeOpenStsQlty 100;
BA_ "GenSigStartValue" SG_ 589 RobustGazeYawAng 255;
BA_ "GenSigStartValue" SG_ 589 RobustGazePitchAng 255;
BA_ "GenSigStartValue" SG_ 623 XLvl 2047;
BA_ "GenSigStartValue" SG_ 623 YLvl 2047;
BA_ "SystemSignalLongSymbol" SG_ 623 PrkStraightSuspendOrFinishReq_HU "PrkStraightSuspendOrFinishReq_HUT";
VAL_ 74 LaneCalActvtCmd 0 " Off " 1 " On " ;
VAL_ 74 MODChgReq 0 " No request " 1 " Request " ;
VAL_ 74 Radar_DispCmd 0 " No Request " 1 " Request  " ;
VAL_ 74 Guid_Ovl_Display_Cmd 0 " No Request " 1 " Request  " ;
VAL_ 74 Sgl_View_Sel 0 " No Commands " 1 " Touch 2D Front Button " 2 " Touch 2D Rear Button " 3 " Touch 2D Left Button  " 4 " Touch 2D Right Button " 5 " Touch 2D Left Front  Button " 6 " Touch 2D Right Front Button " 7 " Touch 2D Left Back Button " 8 " Touch 2D Right Back Button " 9 " Touch return Button " 10 " Touch Engine Room Button " 11 " Reserved " ;
VAL_ 74 SwToFieldCalRstCmd 0 " Off " 1 " On " ;
VAL_ 74 AutoViewChgCmd 0 " No Request " 1 " Request  " ;
VAL_ 74 MdlColrChgCmd 0 " No Request " 1 " Request  " ;
VAL_ 74 CarMdlTrsprcySwtCmd 0 " No Request " 1 " Request  " ;
VAL_ 74 CarMdlDispCmd 0 " No Request " 1 " Request  " ;
VAL_ 74 AutoAVMSwSet_Cmd 0 " No Request " 1 " Request  " ;
VAL_ 74 FPAS_AutoModSwt 0 " No Request " 1 " Request  " ;
VAL_ 74 MEBSwtSet 0 " No Request " 1 " Request  " ;
VAL_ 74 WshSoftSwt 0 " No request " 1 " Request " ;
VAL_ 74 View_SoftswitchCmd 0 " No request " 1 " Request " ;
VAL_ 96 Checksum_HCU_PT1 0 " Valid values " ;
VAL_ 96 HCU_BrkPedalSts 0 " not pressed " 1 " pressed " 2 " reserved " 3 " error " ;
VAL_ 96 HCU_BrkPedalStsValid 0 " Invalid values " 1 " Valid values " ;
VAL_ 96 HCU_AccelPedalPosn_Diag 0 " Vaild value " ;
VAL_ 96 HCU_AccelPedalPosn_DiagValid 0 " Invaild " 1 " Vaild " ;
VAL_ 96 ActWheelTrqDmd 0 " Valid values " ;
VAL_ 96 RollingCounter_HCU_PT1 0 " Valid value " 15 " Invalid value " ;
VAL_ 96 Checksum_HCU_PT9 0 " Valid values " ;
VAL_ 96 MaxPsblWheelTrq 0 " Vaild value " ;
VAL_ 96 TotWheelTrq 0 " Vaild value " ;
VAL_ 96 TotWheelTrqVld 0 " Invaild " 1 " Vaild " ;
VAL_ 96 MinPsblWheelTrq 0 " Vaild value " ;
VAL_ 96 HCU_ACCInterface 0 " No response " 1 " Response " ;
VAL_ 96 RollingCounter_HCU_PT9 0 " Valid value " 15 " Invalid value " ;
VAL_ 96 HCU_PowertrainSts 0 " Sleep " 1 " Initialize Mode " 2 " power up " 3 " power down " 4 " Home " 5 " run " 6 " Charging " 7 " Cellphone AC " 8 " Limphome  " 9 " Emergency Mode  " 10 " V2L " 11 " Prepare Sleep " 12 " ready " 13 " LV Charging " 14 " LT Charging " 15 " IL heating " 16 " Thermal run away " 17 " End of line " 18 " BattTempKeep " 19 " Reserved " ;
VAL_ 96 HCU_HWPInterface 0 " No response " 1 " Response " ;
VAL_ 96 HCU_RespHWP 0 " No response " 1 " Response " ;
VAL_ 159 CheckSum_IBooster3 0 " Valid values " ;
VAL_ 159 DrvReqFxBrkDomAvail 0 " Valid value " 3 " Reserved " ;
VAL_ 159 IsDrvReqFxBrakeDom 0 " Valid value " ;
VAL_ 159 RollingCounter_IBooster3 0 " Valid value " 15 " Invalid value " ;
VAL_ 161 Checksum_CSA2 0 " Valid values " ;
VAL_ 161 SteerWheelAng 0 " Valid value " 7801 " Reserved " 32767 " Invalid " ;
VAL_ 161 SteerWheelAngSign 0 " Left (Positive) " 1 " Right (Negative) " ;
VAL_ 161 SteerWheelSpd 0 " Valid value " 10161 " Reserved " 32767 " Invalid " ;
VAL_ 161 SteerWheelSpdSign 0 " Left (Positive) " 1 " Right (Negative) " ;
VAL_ 161 SAS_Sts 0 " SAS Angle And Speed Correct " 1 " SAS Not Calibrated " 2 " Intermittent Error Detected " 3 " Permanent Error Detected " ;
VAL_ 161 ManualShiftReq 0 " no shift/ no control " 1 " Shift up request  " 2 " Shift down request  " 3 " both pedals pressed " 4 " Reserved " 6 " Invalid " 7 " Fault " ;
VAL_ 161 ACC_TimeGap_IncSetSwt 0 " No press " 1 " Pressed " ;
VAL_ 161 ACC_TimeGap_DecSetSwt 0 " No press " 1 " Pressed " ;
VAL_ 161 CC_ACC_CRUISE_OFFSwt 0 " No press " 1 " Pressed " ;
VAL_ 161 CC_ACC_CANCEL_OFFSwt 0 " No press " 1 " Pressed " ;
VAL_ 161 CC_ACC_IncSetSpd_ResuSwt 0 " No press " 1 " Pressed " ;
VAL_ 161 CC_ACC_DecSetSpd_SetSwt 0 " No press " 1 " Pressed " ;
VAL_ 161 CC_ACCSwtErr 0 " No error " 1 " Error " ;
VAL_ 161 HWA_OK_OFFSwt 0 " No press " 1 " Pressed " ;
VAL_ 161 Rollingcounter_CSA2 0 " Valid value " 15 " Invalid value " ;
VAL_ 211 DrvReqFxBrkDomAvail 0 " Valid value " 3 " Reserved " ;
VAL_ 211 IsDrvReqFxBrakeDom 0 " Valid value " ;
VAL_ 211 CheckSum_ESP14 0 " Valid values " ;
VAL_ 211 DrvPressBrkPedalAvl 0 " Valid value " 3 " Reserved " ;
VAL_ 211 IsDrvPressBrkPedal 0 " Valid value " ;
VAL_ 211 RollingCounter_ESP14 0 " Valid value " 15 " Invalid value " ;
VAL_ 259 EngState_PHEV 0 " Stand by " 1 " Ready " 2 " Cranking " 3 " Running " 4 " Stopping " 5 " Finish " 6 " Autostopping " 7 " Reserved " ;
VAL_ 273 EngSpd 0 " Valid values  " ;
VAL_ 273 EngSpdVldty 0 " Invalid " 1 " Valid " 2 " Initial value " 3 " Reserved " ;
VAL_ 288 IB_BrkPedalAppld 0 " Not applied " 1 " Applied " ;
VAL_ 288 IB_BrkPedalAppldVld 0 " Not initialized " 1 " Normal " 2 " Faulty " 3 " Reserved " ;
VAL_ 288 CheckSum_ABS1 0 " Valid values " ;
VAL_ 288 WssFLEdgesSum 0 " Valid Values " ;
VAL_ 288 WssFREdgesSum 0 " Valid Values " ;
VAL_ 288 WssFLEdgesSumVld 0 " Invalid " 1 " Valid " ;
VAL_ 288 WssFREdgesSumVld 0 " Invalid " 1 " Valid " ;
VAL_ 288 RollingCounter_ABS1 0 " Valid value " 15 " Invalid value " ;
VAL_ 288 CheckSum_ABS3 0 " Valid values " ;
VAL_ 288 RollingCounter_ABS3 0 " Valid value " 15 " Invalid value " ;
VAL_ 288 CheckSum_IBooster_FD2_5 0 " Valid values " ;
VAL_ 288 VLC_IntTartAccel 0 " Valid value " 2561 " Reserved " ;
VAL_ 288 L3VLCADactive 0 " Not active " 1 " Active " ;
VAL_ 288 L3mainVMCavailiable 0 " Not initialized " 1 " Not Available " 2 " Available " 3 " Availablewithfault " ;
VAL_ 288 RollingCounter_Booster_FD2_5 0 " Valid value " 15 " Invalid value " ;
VAL_ 288 CheckSum_ABS2 0 " Valid values " ;
VAL_ 288 WssRREdgesSum 0 " Valid Values " ;
VAL_ 288 WssRLEdgesSum 0 " Valid Values " ;
VAL_ 288 WssRLEdgesSumVld 0 " Invalid " 1 " Valid " ;
VAL_ 288 WssRREdgesSumVld 0 " Invalid " 1 " Valid " ;
VAL_ 288 RollingCounter_ABS2 0 " Valid value " 15 " Invalid value " ;
VAL_ 299 Checksum_IFC1 0 " Valid value " ;
VAL_ 299 IFCTrqOvlCmdProtnValue 0 " Valid value " ;
VAL_ 299 IFCTrqOvlCmdReqValue 0 " Valid value " ;
VAL_ 299 IFCFuncTrqCmdReqFlag 0 " No Request " 1 " LKA Request " 2 " ESS Request " 3 " Reserved " ;
VAL_ 299 IFCVibrationWarning 0 " No Request " 1 " LeveL 1 " 2 " Reserved " ;
VAL_ 299 RollingCounter_IFC1 0 " Valid value " 15 " Invalid value " ;
VAL_ 299 Checksum_IFC2 0 " Valid value " ;
VAL_ 299 IFCAngCmdReqValue 0 " Valid value " 15601 " reserved " ;
VAL_ 299 IFCAngCmdReqProtnValue 0 " Valid value " ;
VAL_ 299 IFCFuncAngCmdReqFlag 0 " No Request  " 1 " LKA Req        " 2 " ESS Req  " 3 " Reserved " ;
VAL_ 299 RollingCounter_IFC2 0 " Valid value " 15 " Invalid value " ;
VAL_ 303 Checksum_HCU_PT5 0 " Valid values " ;
VAL_ 303 HCU_DrvMod 0 " Auto/Normal Mode started " 1 " EV Mode started " 2 " Save Mode started " 3 " SPORT Mode started " 4 " AWD Normal Mode started " 5 " Snow Mode started " 6 " Muddy Mode started " 7 " Sand Mode started " 8 " ECO " 9 " SPORT Plus Mode started " 10 " Reserved " ;
VAL_ 303 HCU_PTDrvMod 0 " No propel torque  " 1 " H-FWD (发动机+P2，或发动机) " 2 " E-FWD（纯电即P2） " 3 " RWD （纯电即P4） " 4 " H-AWD（混动四驱即发动机+P4，或P2+发动机+P4） " 5 " E-AWD（纯电四驱，即P2+P4） " 6 " Reserved " ;
VAL_ 303 DrvTrqReqOvld 0 " No driver override " 1 " Driver override " 2 " Reserved " 3 " invalid values " ;
VAL_ 303 RollingCounter_HCU_PT5 0 " Valid value " 15 " Invalid value " ;
VAL_ 303 HCU_GearSts 0 " Select lever in position -P- " 1 " Reserved " 2 " Reserved " 3 " Reserved " 4 " Reserved " 5 " Select lever in position -D- " 6 " Select lever in position -N- " 7 " Select lever in position -R- " 8 " Reserved " 14 " Intermediate position " 15 " Invalid  " ;
VAL_ 303 HCU_APS_Available 0 " Available " 1 " Not available " ;
VAL_ 303 HCU_FltLvl 0 " Normal " 1 " Fault Level 1（Slight fault does not affect the power system） " 2 " Fault Level 2（Power system fault） " 3 " Reserved " ;
VAL_ 303 HCU_VehSpdLimit 0 " Valid value " ;
VAL_ 311 VehStandstill 0 " Not standstill " 1 " Standstill " 2 " Invalid (short unavailability, maX 3s) " 3 " Reserved " ;
VAL_ 311 EngTrqReq 0 " Valid  value " 20476 " Reserved " ;
VAL_ 311 CheckSum_ABS3 0 " Valid values " ;
VAL_ 311 VehSpdVld 0 " Invalid " 1 " Valid " ;
VAL_ 311 VehSpd 0 " Valid values " 5334 " Reserved " ;
VAL_ 311 RollingCounter_ABS3 0 " Valid value " 15 " Invalid value " ;
VAL_ 311 CheckSum_ESP_FD2_1 0 " Valid values " ;
VAL_ 311 L12VLCADactive 0 " Not active " 1 " Active " ;
VAL_ 311 L12mainVMCavailiable 0 " Not Available " 1 " Available " ;
VAL_ 311 RollingCounter_ESP_FD2_1 0 " Valid value " 15 " Invalid value " ;
VAL_ 311 CheckSum_ESP2 0 " Valid values " ;
VAL_ 311 CDPActv 0 " Not active " 1 " Active " ;
VAL_ 311 ESP_DiagActv 0 " ESP diagnosis is inactive " 1 " ESP diagnosis is active " ;
VAL_ 311 BrkDskOvrheatd 0 " Not high " 1 " Temp too high " ;
VAL_ 311 NoBrkForce 0 " EXist brake force " 1 " No brake force " ;
VAL_ 311 AEBIBActv 0 " Not active " 1 " Active " ;
VAL_ 311 AEBBAActv 0 " Not active " 1 " Active " ;
VAL_ 311 AEBAvailable 0 " Unusable " 1 " Usable " ;
VAL_ 311 ABPAvailable 0 " Unusable " 1 " Usable " ;
VAL_ 311 ABPActv 0 " Not active " 1 " Active " ;
VAL_ 311 ABAavailable 0 " Unusable " 1 " Usable " ;
VAL_ 311 ABAactv 0 " Not active " 1 " Active " ;
VAL_ 311 HDCCtrl 0 " OFF " 1 " On active braking " 2 " On not active braking " 3 " Reserved " ;
VAL_ 311 CDDActv 0 " Not active " 1 " Active " ;
VAL_ 311 CDDAvailable 0 " Not available " 1 " Available " ;
VAL_ 311 AWBAvailable 0 " Unusable " 1 " Usable " ;
VAL_ 311 AWBActv 0 " Not active " 1 " Active " ;
VAL_ 311 AVHErrSts 0 " No failure " 1 " Failure when AVH is on need " 2 " Failure when is not on need " 3 " Reserved " ;
VAL_ 311 AVHSts 0 " Off " 1 " Standby  " 2 " active " ;
VAL_ 311 CTABrkAvailable 0 " Not Available " 1 " Available " ;
VAL_ 311 RollingCounter_ESP2 0 " Valid value " 15 " Invalid value " ;
VAL_ 311 CheckSum_ESP1 0 " Valid values " ;
VAL_ 311 ESPFuncOffSts 0 " Available/On " 1 " Unavailable/Off " ;
VAL_ 311 ESPBrkLmpCtrl 0 " Brake light off " 1 " Brake light on " ;
VAL_ 311 ESPFailSts 0 " No failure " 1 " Failure " ;
VAL_ 311 ESP_MasterCylBrkPressVld 0 " Invalid " 1 " Valid " ;
VAL_ 311 MSRActv 0 " Not active " 1 " Active " ;
VAL_ 311 VDCActv 0 " Not active " 1 " Active " ;
VAL_ 311 PTCActv 0 " Not active " 1 " Active " ;
VAL_ 311 BTCActv 0 " Not active " 1 " Active " ;
VAL_ 311 ESP_MasterCylBrkPress 0 " Valid value " 14961 " Reserved " ;
VAL_ 311 MSRActv_RA 0 " Inactive " 1 " Active " ;
VAL_ 311 PTCActv_RA 0 " Inactive " 1 " Active " ;
VAL_ 311 BTCActv_RA 0 " Inactive " 1 " Active " ;
VAL_ 311 RollingCounter_ESP1 0 " Valid value " 15 " Invalid value " ;
VAL_ 311 CheckSum_ESP7 0 " Valid values " ;
VAL_ 311 ESP_MEBBrkAvail 0 " Not Available " 1 " Available " ;
VAL_ 311 LgtCtrlrAvail 0 " Not Available " 1 " Reserved " 2 " Reserved " 3 " Reserved " 4 " Reserved " 5 " AutomaticPark " 6 " Reserved " ;
VAL_ 311 LgtCtrlrFailr 0 " No Error " 1 " Vehicle_Blocked " 2 " Unexpected_GearPosition " 3 " Unexpected_EPB_Action " 4 " Reserved " 5 " Unexpected_GearIntervention " 6 " Active Braking failure " 7 " Invalid " ;
VAL_ 311 LgtCtrlrSts 0 " Off " 1 " Standby " 2 " Reserved " 3 " Reserved " 4 " Active_AutomaticPark " 5 " Reserved " 6 " Reserved " 7 " Invalid " ;
VAL_ 311 FourWhlsBrkTrq 0 " Valid values value " ;
VAL_ 311 APS_EngTrqReqEna 0 " No demand " 1 " Valid torque demand " ;
VAL_ 311 RollingCounter_ESP7 0 " Valid value " 15 " Invalid value " ;
VAL_ 311 ABSFailSts 0 " No failure " 1 " Failure " ;
VAL_ 311 EBDFailSts 0 " No failure " 1 " Failure " ;
VAL_ 311 EBDActv 0 " Not active " 1 " Active " ;
VAL_ 311 ABSActv 0 " Not active " 1 " Active " ;
VAL_ 315 L3VLCADactive 0 " Not active " 1 " Active " ;
VAL_ 315 L3mainVMCavailiable 0 " Not initialized " 1 " Not Available " 2 " Available " 3 " Availablewithfault " ;
VAL_ 315 CheckSum_ABS1 0 " Valid values " ;
VAL_ 315 FLWheelDriveDirection 0 " Invalid " 1 " Forward " 2 " Backward " 3 " Stop " ;
VAL_ 315 FLWheelSpdVld 0 " Invalid " 1 " Valid " ;
VAL_ 315 FLWheelSpd 0 " Valid values " 5334 " Reserved " ;
VAL_ 315 FRWheelDriveDirection 0 " Invalid " 1 " Forward " 2 " Backward " 3 " Stop " ;
VAL_ 315 FRWheelSpdVld 0 " Invalid " 1 " Valid " ;
VAL_ 315 FRWheelSpd 0 " Valid values " 5334 " Reserved " ;
VAL_ 315 WssFLEdgesSum 0 " Valid Values " ;
VAL_ 315 WssFREdgesSum 0 " Valid Values " ;
VAL_ 315 WssFLEdgesSumVld 0 " Invalid " 1 " Valid " ;
VAL_ 315 WssFREdgesSumVld 0 " Invalid " 1 " Valid " ;
VAL_ 315 RollingCounter_ABS1 0 " Valid value " 15 " Invalid value " ;
VAL_ 315 CheckSum_ABS2 0 " Valid values " ;
VAL_ 315 RLWheelDriveDirection 0 " Invalid " 1 " Forward " 2 " Backward " 3 " Stop " ;
VAL_ 315 RLWheelSpdVld 0 " Invalid " 1 " Valid " ;
VAL_ 315 RLWheelSpd 0 " Valid values " 5334 " Reserved " ;
VAL_ 315 RRWheelDriveDirection 0 " Invalid " 1 " Forward " 2 " Backward " 3 " Stop " ;
VAL_ 315 RRWheelSpdVld 0 " Invalid " 1 " Valid " ;
VAL_ 315 RRWheelSpd 0 " Valid values " 5334 " Reserved " ;
VAL_ 315 WssRREdgesSum 0 " Valid Values " ;
VAL_ 315 WssRLEdgesSum 0 " Valid Values " ;
VAL_ 315 WssRLEdgesSumVld 0 " Invalid " 1 " Valid " ;
VAL_ 315 WssRREdgesSumVld 0 " Invalid " 1 " Valid " ;
VAL_ 315 RollingCounter_ABS2 0 " Valid value " 15 " Invalid value " ;
VAL_ 315 VLC_IntTartAccel 0 " Valid value " 2561 " Reserved " ;
VAL_ 315 CheckSum_EPB1 0 " Valid values " ;
VAL_ 315 ESP_DSTSts 0 " Not active " 1 " Active " 2 " Not available " 3 " Reserved " ;
VAL_ 315 EPB_SwtPosnVld 0 " Invalid " 1 " Valid " ;
VAL_ 315 EPBErrSts 0 " Undefined " 1 " No Error " 2 " Error " 3 " Diagnosis " ;
VAL_ 315 EPBSts 0 " Released " 1 " Closed " 2 " In progress " 3 " unknown " ;
VAL_ 315 EPB_SwtPosn 0 " Neutral " 1 " Release " 2 " Apply " 3 " Reserved " ;
VAL_ 315 RollingCounter_EPB1 0 " Valid value " 15 " Invalid value " ;
VAL_ 315 CheckSum_ESP_FD3_7 0 " Valid values " ;
VAL_ 315 VLC_ESP_FuelCutOffPrevention 0 " Valid value " ;
VAL_ 315 VLC_ESP_State 0 " Valid value " ;
VAL_ 315 LSMGearRequest 0 " GearReq_NoReq " 1 " GearReq_Forward " 2 " GearReq_Backward " 3 " reversed " ;
VAL_ 315 ParkPawlRequest 0 " No request " 1 " P Gear request " ;
VAL_ 315 LSMPosLongACapbl 0 " AxCapbl_Full " 1 " reversed " 2 " AxCapbl_VehBlocked " 3 " reversed " ;
VAL_ 315 LSMSubMTReqAvailable 0 " False " 1 " True " ;
VAL_ 315 LSMSubMTLevelEcho 0 " MTLevel_None " 1 " MTLevel_12 " 2 " MTLevel_23 " 3 " MTLevel_Reserved " ;
VAL_ 315 LSMSubMTLongEcho 0 " MTLong_None " 1 " MTLong_Comfort " 2 " MTLong_Emergency " 3 " MTLong_Reserved " ;
VAL_ 315 LSMSubMTReqEcho 0 " MTLong_None " 1 " MTLong_Drive " 2 " MTLong_LSM " 3 " reversed " ;
VAL_ 315 Lsm12ComfortAvl 0 " NotAvailable " 1 " FailureDetectedReducedAvl " 2 " FailureDetectedFullyAvl " 3 " Available " ;
VAL_ 315 Lsm12EmergencyAvl 0 " NotAvailable " 1 " FailureDetectedReducedAvl " 2 " FailureDetectedFullyAvl " 3 " Available " ;
VAL_ 315 Lsm23Avl 0 " NotAvailable " 1 " FailureDetectedReducedAvl " 2 " FailureDetectedFullyAvl " 3 " Available " ;
VAL_ 315 RollingCounter_ESP_FD3_7 0 " Valid value " 15 " Invalid value " ;
VAL_ 323 Checksum_ACC11 0 " Valid value " ;
VAL_ 323 HWP_AccelOvrdActnReq_L2 0 " No Action " 1 " Action " ;
VAL_ 323 HWP_SuprAvail_L2 0 " Not Available " 1 " Available " ;
VAL_ 323 HWP_MotTypeReqMode_L2 0 " None " 1 " Drv L12 " 2 " Drv L3 " 3 " Reserved " ;
VAL_ 323 HWP_MotTypeReqLong_L2 0 " Longitudinal Off " 1 " Longitudinal Comfort " 2 " Longitudinal Emergency " 3 " Reserved3 " 4 " Reserved4 " ;
VAL_ 323 HWP_ShutdownReq_L2 0 " no demand " 1 " demand " ;
VAL_ 323 HWP_UpperLimit_L2 0 " Valid value " 128 " Reserved " ;
VAL_ 323 HWP_LowerLimit_L2 0 " Valid value " 128 " Reserved " ;
VAL_ 323 HWP_SecureReq_L2 0 " no request " 1 " request " ;
VAL_ 323 HWP_AEBAvail 0 " Not Available " 1 " Available " ;
VAL_ 323 HWP_ACCAvail 0 " Not Available " 1 " Available " ;
VAL_ 323 HWP_TgtAccelCmftUpprLimVal_L2 0 " Valid value " 251 " Reserved " ;
VAL_ 323 HWP_TgtAccelCmftLwrLimVal_L2 0 " Valid value " 251 " Reserved " ;
VAL_ 323 HWP_UseTgtAccelCmftUpprLimVal_L2 0 " No demand " 1 " Demand " ;
VAL_ 323 RollingCounter_ACC11 0 " Valid value " 15 " Invalid value " ;
VAL_ 323 Checksum_ACC1 0 " Valid value " ;
VAL_ 323 Longctrl_VehHldReq 0 " No Request " 1 " Request " ;
VAL_ 323 Longctrl_DrvOFF_Req 0 " No Request " 1 " Request " ;
VAL_ 323 Longctrl_ModSts 0 " OFF mode " 1 " Passive mode(Reject) " 2 " Passive mode(Stand-by) " 3 " Active-Control mode " 4 " Brake-only mode " 5 " Override " 6 " Standstill " 7 " Failure mode Longctrl " 8 " Reserved " 9 " Shut off " 10 " Reserved " ;
VAL_ 323 Longctrl_Decel_Req 0 " No Request " 1 " Request " ;
VAL_ 323 Longctrl_DecelToStopReq 0 " No Request " 1 " Request " ;
VAL_ 323 Longctrl_ParkShiftReq 0 " No request " 1 " Request park Shift " 2 " Invalid " 3 " Reserved " ;
VAL_ 323 Longctrl_Decel_ReqValue 0 " Valid value " ;
VAL_ 323 ActualTargetSpeed 0 " Valid value " 255 " Invalid value " ;
VAL_ 323 RollingCounter_ACC1 0 " Valid value " 15 " Invalid value " ;
VAL_ 323 Checksum_ACC2 0 " Valid value " ;
VAL_ 323 HWP_TgtAccel_L2 0 " Valid value " 2561 " Reserved " ;
VAL_ 323 IDC_L2_HADFuncCmdReqFlag 0 " No Request  " 1 " LKA Req        " 2 " ESS Req  " 3 " Reserved " 4 " HWP Req  " 5 " Override  " 6 " Failure " 7 " Reserved " ;
VAL_ 323 HWP_AngCmdReqVal_L2 0 " Valid value " 15601 " reserved " ;
VAL_ 323 HWP_AngCmdReqValVld_L2 0 " Invalid " 1 " Valid " ;
VAL_ 323 RollingCounter_ACC2 0 " Valid value " 15 " Invalid value " ;
VAL_ 323 ACC_CRInterface 0 " No Response " 1 " Response " ;
VAL_ 323 Checksum_ACC10 0 " Valid value " ;
VAL_ 323 Longctrl_HCUTrqReq 0 " Valid value " ;
VAL_ 323 Longctrl_HCUTrqReqActive 0 " Not active " 1 " Active " ;
VAL_ 323 RollingCounter_ACC10 0 " Valid value " 15 " Invalid value " ;
VAL_ 327 CheckSum_EPS1 0 " Valid values " ;
VAL_ 327 EPS_FailSts 0 " No fault " 1 " Permanent Error Detected " 2 " Intermittent Error Detected " 3 " Reserved " ;
VAL_ 327 EPS_TrqSnsrSts 0 " Normal " 1 " Abnormal " ;
VAL_ 327 EPS_InterferDetd 0 " No Interference " 1 " Interference " ;
VAL_ 327 EPS_InterferDetdVld 0 " Invalid " 1 " Valid " ;
VAL_ 327 EPS_AvailSts 0 " Temporary inhibit " 1 " Available for control " 2 " Active " 3 " Permanently failed " ;
VAL_ 327 EPS_SteerMod 0 " Comfort Mode " 1 " sport mode  " 2 " Handiness Mode " 3 " Reserved " ;
VAL_ 327 EPS_DSTCtrlSts 0 " Permanently fail " 1 " Temporary inhibit " 2 " Available for control " 3 " Active " 4 " Reserved " ;
VAL_ 327 RollingCounter_EPS1 0 " Valid value " 15 " Invalid value " ;
VAL_ 327 CheckSum_EPS2 0 " Valid values " ;
VAL_ 327 EPS_LKATorqOvrlDlvd 0 " Valid value " 3001 " Reserved " ;
VAL_ 327 EPS_LKATorqOvrlDlvdVld 0 " Invalid " 1 " Valid " ;
VAL_ 327 EPS_LKATrqOvlDlvdSts 0 " Not active " 1 " Active " 2 " Temporary inhibit " 3 " Permanently failed " ;
VAL_ 327 EPS_DrvInpTrqVal_HighReslolution 0 " Valid Values " ;
VAL_ 327 EPS_DrvInpTrqVal_HighResVld 0 " Invalid " 1 " Valid " ;
VAL_ 327 EPS_LKAAngDlvdSts 0 " Not active " 1 " Active " 2 " Temporary inhibit " 3 " Permanently failed " ;
VAL_ 327 RollingCounter_EPS2 0 " Valid value " 15 " Invalid value " ;
VAL_ 327 CheckSum_EPS3 0 " Valid values " ;
VAL_ 327 EPS_HADHndShkRespSt 0 " Off  " 1 " Reserved  " 2 " Reserved  " 3 " Reserved  " 4 " HWP Active  " 5 " Failure " 6 " Reserved " ;
VAL_ 327 EPS_AvailStsforHAD 0 " Not available  " 1 " Available degraded " 2 " Available " 3 " Reserved " ;
VAL_ 327 EPS_AngCmdOverRange 0 " Not over ange  " 1 " Over ange " ;
VAL_ 327 EPS_HADerror_Reason 0 " No error  " 1 " IDC_L3 request is invalid  " 2 " IDC_L3 communication Error " 3 " IDC_L3 fault " 4 " EPS internal error detected  " 5 " Under Voltage detected  " 6 " Over Voltage detected  " 7 " ADS Requested steering angle is above the limit  " 8 " Change rate of ADS Requested steering angle is above the limit  " 9 " vehicle speed is above the limit " 10 " Reserved " ;
VAL_ 327 EPS_SteerWheelAngVld 0 " Invalid " 1 " Valid " ;
VAL_ 327 ElecPwrSteerCpby 0 " Normal " 1 " 50% assist " 2 " 0% assist " 3 " Reserved " ;
VAL_ 327 EPS_SteerWheelAng 0 " Valid value " 7801 " Reserved " 32767 " Invalid " ;
VAL_ 327 EPS_SteerWheelAngSign 0 " Left (Positive) " 1 " Right (Negative) " ;
VAL_ 327 EPS_SteerWheelSpd 0 " Valid value " 10161 " Reserved " 32767 " Invalid " ;
VAL_ 327 EPS_SteerWheelSpdSign 0 " Left (Positive) " 1 " Right (Negative) " ;
VAL_ 327 EPS_HWPHndShkResp 0 " No Response " 1 " Response " ;
VAL_ 327 RollingCounter_EPS3 0 " Valid value " 15 " Invalid value " ;
VAL_ 344 Checksum_IDC_L3_1 0 " Valid values " ;
VAL_ 344 HWP_ReqCtrlEPS 0 " 0x1 " ;
VAL_ 344 HWP_ReqCtrlEPSVld 0 " Invalid " 1 " Valid " ;
VAL_ 344 HWP_AngCmdReqVal 0 " Valid value " 15601 " reserved " ;
VAL_ 344 HWP_AngCmdReqValVld 0 " Invalid " 1 " Valid " ;
VAL_ 344 HWP_HapcWarnReq 0 " No Request " 1 " LeveL 1 " 2 " Reserved " ;
VAL_ 344 HWP_TrqOvlCmdProtnValue 0 " Valid value " ;
VAL_ 344 HWP_TrqOvlCmdReqValue 0 " Valid value " ;
VAL_ 344 HWP_FuncTrqCmdReqFlag 0 " No Request " 1 " HWP Request " 2 " Reserved " ;
VAL_ 344 RollingCounter_IDC_L3_1 0 " Valid value " 15 " Invalid value " ;
VAL_ 344 Checksum_IDC_L3_3 0 " Valid values " ;
VAL_ 344 HWP_AccelOvrdActnReq 0 " No Action " 1 " Action " ;
VAL_ 344 HWP_WorkReq 0 " OFF " 1 " Standby " 2 " Ready " 3 " Active " 4 " Reserved " ;
VAL_ 344 HWP_WorkReqVld 0 " Invalid " 1 " Valid " ;
VAL_ 344 HWP_TgtGearReq 0 " No request " 1 " P  " 2 " R " 3 " N " 4 " D " 5 " Reserved " ;
VAL_ 344 HWP_TgtGearReqVld 0 " Invalid " 1 " Valid " ;
VAL_ 344 HWP_Lgtctrl_EngTrqReq 0 " Valid value " ;
VAL_ 344 HWP_Lgtctrl_EngTrqReqActv 0 " Not active " 1 " Active " ;
VAL_ 344 HWP_Lgtctrl_FuelCutOffReq 0 " Not active " 1 " Active " ;
VAL_ 344 HWP_ECMOvrdReq 0 " Not active " 1 " Active " ;
VAL_ 344 HWP_EngTrqReqActvVld 0 " Invalid " 1 " Valid " ;
VAL_ 344 HWP_Lgtctrl_EngTrqReqVld 0 " Invalid " 1 " Valid " ;
VAL_ 344 HWP_lgt_ModSts 0 " OFF mode " 1 " Passive mode(Reject) " 2 " Passive mode(Stand-by) " 3 " Active-Control mode " 4 " Brake-only mode " 5 " Override " 6 " Standstill " 7 " Failure mode Longctrl " 8 " Reserved " 9 " Shut off " 10 " Reserved " ;
VAL_ 344 RollingCounter_IDC_L3_3 0 " Valid value " 15 " Invalid value " ;
VAL_ 344 Checksum_IDC_L3_5 0 " Valid values " ;
VAL_ 344 IDC_L3_HADFuncCmdReqFlag 0 " No Request  " 1 " LKA Req        " 2 " ESS Req  " 3 " Reserved " 4 " HWP Req  " 5 " Override  " 6 " Failure " 7 " Reserved " ;
VAL_ 344 IFCVibrationWarning_L3 0 " No Request " 1 " LeveL 1 " 2 " Reserved " ;
VAL_ 344 IDC_L3_AEB_ObjSty 0 " No Object " 1 " Vehicle " 2 " Pedestrian " 3 " Cyclist " 4 " unknown " 5 " Resvered " ;
VAL_ 344 HWP_lgt_VehHldReq 0 " No Request " 1 " Request " ;
VAL_ 344 HWP_lgt_DrvOFF_Req 0 " No Request " 1 " Request " ;
VAL_ 344 HWP_lgt_Decel_Req 0 " No Request " 1 " Request " ;
VAL_ 344 HWP_lgt_DecelToStopReq 0 " No Request " 1 " Request " ;
VAL_ 344 HWP_lgt_Decel_ReqValue 0 " Valid value " ;
VAL_ 344 HWP_AEB_ABALvl 0 " Level 0 " 1 " Level 1 " 2 " Level 2 " 3 " Level 3 " ;
VAL_ 344 HWP_AEB_ABAReq 0 " No Request " 1 " Request " ;
VAL_ 344 HWP_EBA_DecelCtrlReq 0 " No Request " 1 " Request " ;
VAL_ 344 HWP_AEB_VehHldReq 0 " No Request " 1 " Request " ;
VAL_ 344 HWP_AEB_DecelCtrlReq 0 " No Request " 1 " Request " ;
VAL_ 344 HWP_AEB_DecelCtrlReqVal 0 " Valid value " 65535 " Invalid " ;
VAL_ 344 HWP_AEB_AWB_Req 0 " No Request " 1 " Request " ;
VAL_ 344 HWP_AEB_AWB_Lvl 0 " No level " 1 " Level 1 " 2 " Level 2 " 3 " Level 3 " 4 " Level 4 " 5 " Resvered " ;
VAL_ 344 HWP_AEB_ABP_Req 0 " No Request " 1 " Request " ;
VAL_ 344 HWP_EPBCtrlReq 0 " Release " 1 " Brake " ;
VAL_ 344 HWP_EPBCtrlReqVld 0 " Invalid " 1 " Valid " ;
VAL_ 344 RollingCounter_IDC_L3_5 0 " Valid value " 15 " Invalid value " ;
VAL_ 344 Checksum_IDC_L3_4 0 " Valid values " ;
VAL_ 344 HWP_Lgt_HCUTrqReq 0 " Valid value " ;
VAL_ 344 HWP_Lgt_HCUTrqReqVld 0 " Invalid " 1 " Valid " ;
VAL_ 344 HWP_Lgt_HCUTrqReqActv 0 " Not active " 1 " Active " ;
VAL_ 344 HWP_Lgt_HCUTrqReqActvVld 0 " Invalid " 1 " Valid " ;
VAL_ 344 HWP_HCUOvrdReq 0 " Not active " 1 " Active " ;
VAL_ 344 HWP_TgtAccel 0 " Valid value " 2561 " Reserved " ;
VAL_ 344 RollingCounter_IDC_L3_4 0 " Valid value " 15 " Invalid value " ;
VAL_ 344 HWP_MotTypeReqMode 0 " None " 1 " Drv L12 " 2 " Drv L3 " 3 " Reserved " ;
VAL_ 344 HWP_MotTypeReqLong 0 " Longitudinal Off " 1 " Longitudinal Comfort " 2 " Longitudinal Emergency " 3 " Reserved " ;
VAL_ 344 HWP_ShutdownReq 0 " no demand " 1 " demand " ;
VAL_ 344 HWP_UpperLimit 0 " Valid value " 128 " Reserved " ;
VAL_ 344 HWP_LowerLimit 0 " Valid value " 128 " Reserved " ;
VAL_ 344 HWP_SecureReq 0 " no request " 1 " request " ;
VAL_ 344 HWP_SuprAvail 0 " Not Available " 1 " Available " ;
VAL_ 344 HWP_TgtAccelCmftUpprLimVal 0 " Valid value " 251 " Reserved " ;
VAL_ 344 HWP_TgtAccelCmftLwrLimVal 0 " Valid value " 251 " Reserved " ;
VAL_ 344 HWP_UseTgtAccelCmftUpprLimVal 0 " No demand " 1 " Demand " ;
VAL_ 347 Checksum_APS1 0 " Valid Value " ;
VAL_ 347 APS_PrkgMod 0 " None " 1 " Parking in " 2 " Parking out " 3 " Reserved " ;
VAL_ 347 APS_ProcBar 0 " 0-100 " 101 " Reserved " 127 " No Display " ;
VAL_ 347 APS_SwtSts 0 " no press " 1 " press " ;
VAL_ 347 APS_SlotDisp 0 " No parking slot " 1 " Left parallel parking slot " 2 " Left vertical parking slot " 3 " Left T-shape parking slot " 4 " Right parallel parking slot " 5 " Right vertical parking slot " 6 " Right T-shape parking slot " 7 " Reserved " ;
VAL_ 347 APS_ReqEPSTgtAngValid 0 " Invalid " 1 " Valid " ;
VAL_ 347 APS_ReqCtrlEPS 0 " No request " 1 " Request " ;
VAL_ 347 APS_ReqEPSTgtAng 0 " Valid value " ;
VAL_ 347 TurnLightsCmd 0 " No Request " 1 " LeftLight On " 2 " RightLight On " 3 " hazardLight ON " ;
VAL_ 347 APS_SysSoundIndcn 0 " Tone 0 - No Warning " 1 " Tone 1 - APS failed tone " 2 " Tone 2 - APS successful tone " 3 " Tone 3 - APS warning tone " 4 " Tone 4 - APS request tone " 5 " Reserved " ;
VAL_ 347 APS_PrkgTyp 0 " None " 1 " Parallel parking " 2 " Vertical parking " 3 " Reserved " ;
VAL_ 347 APS_TextDisp 0 " No Request " 1 " Wrong gear position to start parking " 2 " Turn D to search for slot " 3 " Please close the trunk " 4 " Please close the door " 5 " Please fasten the seat belt " 6 " Please unfold the Mirror " 7 " Speed is too high,need <23km/h " 8 " System error Parking sys exits " 9 " control unit error parking sys exits " 10 " Please brake " 11 " please select parking mode " 12 " please select internal parking " 13 " please select Slot and parking mode " 14 " please select Slot and internal parking " 15 " Please keep braking " 16 " Hands off the steering wheel " 17 " Release the brake,parking start " 18 " Auto parking,be ready to brake " 19 " parking suspended,close trunk " 20 " parking suspended,close door  " 21 " parking suspended,fasten seat belt " 22 " Obstacles Detected " 23 " brake recovered,confirm to continue " 24 " Parking quited " 25 " parking   finished " 26 " interfered by driver parking quited " 27 " too many parking times parking sys exits " 28 " Parking time too long Parking sys exits " 29 " Too Small Slot Parking sys exits " 30 " Please Clean the Camera " 31 " Select the parking mode(APA3) " 32 " Searching the right slot " 33 " Searching the left slot " 34 " Please turn D to search for parking slot " 35 " Speed is too high,need <30km/h " 36 " Speed is too high,sys exits " 37 " Select parking type " 38 " Long press switch 2s to enter auto parking " 39 " Parking suspended,Please release the gas pedal " 40 " Please brake,And long press switch 2s to continue auto parking " 41 " Parking is not available " 42 " Please select the parking direction by turning the turn switch " 43 " Please brake,And long press switch 2s to enter_POC_left " 44 " Parking sys exits " 45 " Parking suspended,fold the Mirror " 46 " Too Small Slot Please select another direction " 47 " Driving Mode not supported " 48 " Path is smooth " 49 " Please select park out " 50 " Please select park out direction " 51 " Please get off the car with keys to start remote parking " 52 " Please confirm to start parking " 53 " Remote Parking in exit " 54 " Parking suspended,Remote connection error " 55 " System error,Parking sys can not start " 56 " Control unit error,Parking sys can not start " 57 " Please Turn P and Apply EPB Remote parking sys not Running " 58 " Select Remote parking out type " 59 " Please brake,And long press switch 2s to enter_POC_Right " 60 " Please release switch to en-ter guidance " 61 " Slope over ,system exits " 62 " Please select Summon Path " 63 " Reserved " 64 " Path study begin please drive the car " 65 " Path studying " 66 " Confirm study finished " 67 " Path studying failed caused by Path too long " 68 " Path studying failed caused by Speed too high " 69 " Path studying failed caused by communication error " 70 " Path studying failed caused by Path error " 71 " Path studying failed caused by learn time too long " 72 " Path studying failed caused by internal error " 73 " Path studying failed caused by Path too short " 74 " Path studying failed caused by Path backward too long " 75 " Path studying failed caused by shift gear too many times " 76 " Speed is too high,need <5km/h " 77 " Speed is too high,need <10km/h " 78 " Speed is too high,need <15km/h " 79 " Reserved " 80 " Path saving " 81 " Path saving Succeed " 82 " Path saving failed caused by Path too short " 83 " Path saving failed caused by communication error " 84 " Path saving failed caused by Path error " 85 " Path saving failed caused by Path error limit storage room " 86 " Path saving failed caused by internal error " 87 " Reserved " 96 " Please drive to path start point " 97 " Path matche please stop " 98 " Please select play back mode " 99 " Path match failed caused by communication error " 100 " Path match failed caused by path error " 101 " Path match failed caused by long time no action " 102 " Path match failed caused by internal error " 103 " Reserved " 112 " No save distance,RADS sys esits " 113 " RADS running,be ready to brake " 114 " Near the bourn " 115 " Arrive at the bourn " 116 " Release the brake " 117 " Trunk open,RADS sys exits " 118 " Door open,RADS sys exits " 119 " Seat belt drop,RADS sys exits " 120 " Mirror fold,RADS sys exits " 121 " Obstacles Detected,RADS sys exits " 122 " No continue driving Parking quited " 123 " Please turn to R " 124 " Release the brake,Driving assistance start " 125 " Please turn to D " 126 " Reserved for RADS " 128 " FADS running,be ready to brake " 129 " Trunk open,FADS sys exits " 130 " Door open,FADS sys exits " 131 " Seat belt drop,FADS sys exits " 132 " Mirror fold,FADS sys exits " 133 " Obstacles Detected,FADS sys exits " 134 " Vehicle can not move,FADS sys exits " 135 " Remote control straight Search " 136 " Over limit search distance " 137 " Please select suitable parking slot icon " 138 " Please drag the parking slot to suitable place and adjust the angle " 139 " Move over 25m,system exits " 140 " Move over 5m,system exits " 142 " Reserved " ;
VAL_ 347 RollingCounter_APS1 0 " Valid value " 15 " Invalid value " ;
VAL_ 347 Checksum_APS4 0 " Valid Value " ;
VAL_ 347 APS_BrkFctnMod 0 " ParkAssist_NoSignal " 1 " parkAssist_RemotePark " 2 " Reserved " 3 " ParkAssist_AutomaticPark " 4 " Reserved " ;
VAL_ 347 APS_ESP_TgtGearReq 0 " No request " 1 " P  " 2 " R " 3 " N " 4 " D " 5 " Reserved " ;
VAL_ 347 APS_ESP_SpdLimn 0 " Valid Value " ;
VAL_ 347 APS_BrkModSts 0 " ParkAssist_Int " 1 " ParkAssist_Standby " 2 " ParkAssist_Active " 3 " ParkAssist_ManeuverFinished " 4 " ParkAssist_Suspend (Reserved) " 5 " ParkAssist_Abort " 6 " Reserved  " ;
VAL_ 347 APS_ESP_BrkDistance 0 " Valid value " ;
VAL_ 347 APS_BrkCategory 0 " ParkAssist_Idle " 1 " ParkAssist_Comfort " 2 " ParkAssist_Emergency " 3 " Reserved " ;
VAL_ 347 MEB_BrkgReqValue 0 " Valid value " 201 " Reserved " ;
VAL_ 347 MEB_BrkgReq 0 " No Request " 1 " Request " ;
VAL_ 347 MEBErrSts 0 " No Error " 1 " Error " ;
VAL_ 347 APS_WorkSts 0 " Disable " 1 " Standby " 2 " Searching " 3 " Guidance " 4 " Failed " 5 " Wait for Engine restart " 6 " Reserved " ;
VAL_ 347 MEB_AVHReq 0 " No Request " 1 " Request " ;
VAL_ 347 RollingCounter_APS4 0 " Valid value " 15 " Invalid value " ;
VAL_ 347 Checksum_AVP1 0 " Valid Value " ;
VAL_ 347 AVP_ESP_LSMSubMTReq 0 " MTReq_None " 1 " MTReq_Drive " 2 " MTReq_LSM " 3 " Reserved " ;
VAL_ 347 AVP_ESP_LSMSubMTLevel 0 " MTLevel_None " 1 " MTLevel_12 " 2 " MTLevel_23 " 3 " MTLevel_Reserved " ;
VAL_ 347 AVP_ESP_LSMSubMTLong 0 " MTLong_None " 1 " MTLong_Comfort " 2 " MTLong_Emergency " 3 " MTLong_Reserved " ;
VAL_ 347 AVP_ESP_LSMPrefill 0 " No Request " 1 " Requested " ;
VAL_ 347 AVP_ESP_LSMDistToStop 0 " Valid value " ;
VAL_ 347 AVP_ESP_LSMVehDirRq 0 " DirReq_None " 1 " DirReq_Forward " 2 " DirReq_Backward " 3 " Reserved " ;
VAL_ 347 AVP_ESP_LSMvMaxRq 0 " Valid value " 201 " Reserved " ;
VAL_ 347 AVP_ESP_LSMVehSecReq 0 " No Request " 1 " Requested " ;
VAL_ 347 AVP_ESP_LSMNudgeReq 0 " No Request " 1 " Requested " ;
VAL_ 347 AVP_ESP_LSMComfBrakeReq 0 " ComfBrakeReq_NoReq  " 1 " ComfBrakeReq_Type1  " 2 " ComfBrakeReq_Type2 " 3 " Reserved " ;
VAL_ 347 AVP_ESP_DriverPresenceExternal 0 " False " 1 " True " ;
VAL_ 347 AVP_ESP_SafeDrvrHandoverReq 0 " No Request " 1 " Requested " ;
VAL_ 347 RollingCounter_AVP1 0 " Valid value " 15 " Invalid value " ;
VAL_ 347 Checksum_HAP1 0 " Valid Value " ;
VAL_ 347 P2P_PrkgDirectSts 0 " P2P Park in " 1 " P2P Summon " ;
VAL_ 347 RmtPrkgReq 0 " No Request " 1 " Request to parking in " ;
VAL_ 347 LParaPrkgOutVald 0 " valid " 1 " Invalid " ;
VAL_ 347 RParaPrkgOutVald 0 " valid " 1 " Invalid " ;
VAL_ 347 HeadVertPrkgOutVald 0 " valid " 1 " Invalid " ;
VAL_ 347 TailVertPrkgOutVald 0 " valid " 1 " Invalid " ;
VAL_ 347 HAP_SwtDispCtrlCmd 0 " no display " 1 " park out direction Select menu " 2 " continue park menu " 3 " Study finish button " 4 " RDAS distance arrow " 5 " RDAS active distance arrow steering " 6 " Reserved " ;
VAL_ 347 P2P_PahDelSts 0 " No Action " 1 " detecting " 2 " successed " 3 " failed " ;
VAL_ 347 P2P_SelfDetErrCode 0 " No Error " 1 " HAP Error " 2 " tyre pressure error " 3 " door open  " 4 " trunk open " 5 " vehicle moving " 6 " environment error " 7 " Camera is smudgy " 8 " Seat belt not fastened " 9 " Mirror is folded " 10 " Associated system error " 11 " reserved " ;
VAL_ 347 P2P_SelfDetSts 0 " No Action " 1 " deleting " 2 " successed " 3 " failed " ;
VAL_ 347 P2P_Pah1Avail 0 " Not avalible " 1 " Avalible " ;
VAL_ 347 P2P_Pah2Avail 0 " Not avalible " 1 " Avalible " ;
VAL_ 347 APS_PASSwtReq 0 " NO request " 1 " Request to close " 2 " Request to open " 3 " Reserved " ;
VAL_ 347 HAP_PrkgModCurrSts 0 " No display " 1 " Left parallel park in " 2 " Right parallel park in " 3 " Left vert park in " 4 " Right vert park in " 5 " Left Tshape park in " 6 " Right Tshape park in " 7 " Left parallel park out " 8 " Right parallel park out " 9 " Front vert park out " 10 " Rear vert park out " 11 " P2P Summon  " 12 " Reserved " ;
VAL_ 347 APS_MovgDirc 0 " No Display " 1 " Moving forward " 2 " Moving backward " 3 " Reserved  " ;
VAL_ 347 AVP_HiBeamtReq 0 " No request " 1 " Turn OFF " 2 " Turn ON " 3 " Reserved " ;
VAL_ 347 AVP_DippedBeamReq 0 " No request " 1 " Turn OFF " 2 " Turn ON " 3 " Reserved " ;
VAL_ 347 AVP_HornReq 0 " No request " 1 " Turn OFF " 2 " Turn ON " 3 " Reserved " ;
VAL_ 347 AVP_FWiperReq 0 " No Request " 1 " Wiper Auto Or Intermittent " 2 " Low Speed " 3 " High Speed " 4 " Wiper Off " 5 " Reserved " 7 " Error " ;
VAL_ 347 AVP_FWshrReq 0 " No Request " 1 " Wiper Wash " 2 " Wash in Auto Mode " 3 " OFF " ;
VAL_ 347 AVP_PowerModeReq 0 " No Request " 1 " Power Off Request " 2 " Power On Request " 3 " Reserved " ;
VAL_ 347 AVP_WindLockReq 0 " No request " 1 " Request to close " 2 " Request to open " 3 " Reserved " ;
VAL_ 347 AVP_SunroofCloseReq 0 " No request " 1 " Request to close " 2 " Request to open " 3 " Reserved " ;
VAL_ 347 AVP_T_Box_WorkSts 0 " OFF " 1 " HAVP ON " 2 " PAVP ON " 3 " Reserved " ;
VAL_ 347 AVP_CenCtrllockReq 0 " No Request " 1 " lock " 2 " unlock " 3 " Reserved " ;
VAL_ 347 RmtCtrlSts 0 " OFF " 1 " ON " ;
VAL_ 347 RollingCounter_HAP1 0 " Valid value " 15 " Invalid value " ;
VAL_ 347 Checksum_HAP3 0 " Valid value " ;
VAL_ 347 HAVP_StartBtn_Ena 0 " No Display " 1 " Disable " 2 " Enable " 3 " Active " ;
VAL_ 347 HAVP_StopBtn_Ena 0 " No Display " 1 " Disable " 2 " Enable " 3 " Active " ;
VAL_ 347 HAVP_SelfParLotEnding_Ena 0 " No Display " 1 " Disable " 2 " Enable " 3 " Active " ;
VAL_ 347 HAVP_WorkSts 0 " Off " 1 " Standby " 2 " Position " 3 " Preactive " 4 " Restore Cruising " 5 " Summon Crusing " 6 " Parking " 7 " Outing " 8 " Completed " 9 " Suspend " 10 " Abort " 11 " Failure " 12 " Disable " 13 " Study " 14 " Reserved " ;
VAL_ 347 HAVP_FuncSts 0 " HAVP Function standby " 1 " HAVP Function active " 2 " HAVP Function disable " 3 " Reserved " ;
VAL_ 347 PAVP_FuncSts 0 " PAVP Function standby " 1 " PAVP Function disable " 2 " Reserved " ;
VAL_ 347 PAVP_TextDis 0 " No text " 1 " Selfchecking " 2 " AVP unavailable " 3 " Map update failed " 4 " Wrong position " 5 " Req_Close_Door_all doors " 6 " Req_Close_Hood_door " 7 " Req_Close_Trunk_door " 8 " Req_Gear_P_EPB " 9 " Path download failed " 10 " Power off failed " 11 " Pick-up location " 12 " Drop-off area " 13 " No parking lot " 14 " Parking in inprocess " 15 " Parking in complete " 16 " Task failed " 17 " Parking out in process " 18 " Cruising " 19 " Parking out complete " 20 " Req_Quit_System failure " 21 " Req_Suspend_User Req " 22 " Req_Quit_EPS failure " 23 " Req_Quit_ESP failure " 24 " Req_Abort_Terminate_Button_Pressed_HMI_Cancel_RD_Cancel " 25 " Req_Abort_Steering Wheel Intervention " 26 " Req_Abort_Gear Intervention " 27 " Req_Abort_EPB Intervention " 28 " Req_Abort_Function Activation " 29 " Reserved " 32 " Req_Abort_Parking Timeout " 33 " Req_Abort_Speed high " 34 " Req_Abort_Parking Too Many Times " 35 " Req_Abort_Hood Open " 36 " Req_Abort_Trunk Open " 37 " Req_Abort_Door Open " 38 " Req_Abort_Deficient Space " 39 " Req_Abort_Network Disconnection " 40 " Req_Abort_Path Invalid " 41 " Req_Abort_Parking Lot Invalid " 42 " Req_Abort_Rear Mirror Fold " 43 " Req_Abort_ODD Dissatisfied " 44 " Req_Abort_Suspend Too Many Times " 45 " Req_Abort_Suspend Timeout " 46 " Req_Abort_Tire Pressure " 47 " Req_Abort_TBOX Err " 48 " Network fault " 49 " No parking area " 50 " ParkingList screen " 51 " Reserved " ;
VAL_ 347 PAVP_Status 0 " Off " 1 " Standby " 2 " Position " 3 " Preactive " 4 " Restore Cruising " 5 " Summon Crusing " 6 " Parking " 7 " Outing " 8 " Completed " 9 " Suspend " 10 " Abort " 11 " Failure " 12 " Disable " 13 " Reserved " ;
VAL_ 347 PAVP_TextDis2 0 " No tex " 1 " Drop-off area picture request " 2 " Path-list showing request " 3 " Reserved " ;
VAL_ 347 ParallelSlotBtn_Ena 0 " No Display " 1 " Disable " 2 " Enable " 3 " Active " ;
VAL_ 347 VerticalSlotBtn_Ena 0 " No Display " 1 " Disable " 2 " Enable " 3 " Active " ;
VAL_ 347 ClockwiseBtn_Ena 0 " No Display " 1 " Disable " 2 " Enable " 3 " Active " ;
VAL_ 347 AnticlockwiseBtn_Ena 0 " No Display " 1 " Disable " 2 " Enable " 3 " Active " ;
VAL_ 347 SlotConfirmBtn_Ena 0 " No Display " 1 " Disable " 2 " Enable " 3 " Active " ;
VAL_ 347 RollingCounter_HAP3 0 " Valid value " 15 " Invalid value " ;
VAL_ 350 Checksum_CR_R_1 0 " Valid value " ;
VAL_ 350 CR_FCTA_Resp 0 " OFF " 1 " ON " ;
VAL_ 350 CR_FCTB_Resp 0 " OFF " 1 " ON " ;
VAL_ 350 CR_ErrSts 0 " No Error " 1 " Error " ;
VAL_ 350 CR_BliSts 0 " No Blindness " 1 " Blindness " ;
VAL_ 350 FCTB_ABA_Level 0 " Level 0 " 1 " Level 1 " 2 " Level 2 " 3 " Level 3 " ;
VAL_ 350 FCTB_ABA_Req 0 " No Request " 1 " Request " ;
VAL_ 350 FCTB_ABP_Req 0 " No Request " 1 " Request " ;
VAL_ 350 FCTA_Warn 0 " No warning " 1 " Warning " ;
VAL_ 350 FCTBTrig 0 " Not tirggered " 1 " tirggered " ;
VAL_ 350 FCTA_B_FuncSts 0 " No display  " 1 " error  " 2 " FCTA_B temporarily unavailable " 3 " FCTA_B Performance degradation " ;
VAL_ 350 CR_BrkgReqVal 0 " Valid value " 65535 " Invalid " ;
VAL_ 350 CR_BrkgReq 0 " No Request " 1 " Request " ;
VAL_ 350 FCTA_B_TTC 0 " No Display " 1 " valid value " ;
VAL_ 350 RollingCounter_CR_R_1 0 " Valid value " 15 " Invalid value " ;
VAL_ 350 Checksum_CR_R_2 0 " Valid value " ;
VAL_ 350 CR_ObjSts_Le 0 " Target Invalid " 1 " Target Valid " 2 " No target " 3 " Reserved " ;
VAL_ 350 CR_ObjID_Le 0 " Valid value " ;
VAL_ 350 CR_ObjDistX_Le 0 " Valid value " ;
VAL_ 350 CR_ObjDistY_Le 0 " Valid value " ;
VAL_ 350 CR_ObjRelVelX_Le 0 " Valid value " ;
VAL_ 350 CR_ObjRelAccelX_Le 0 " Valid values " ;
VAL_ 350 CR_ObjMotionType_Le 0 " int " 1 " unknown " 2 " Drive " 3 " Stopped " 4 " Stand " 5 " reserved " 6 " reserved " 7 " reserved " ;
VAL_ 350 RollingCounter_CR_R_2 0 " Valid value " 15 " Invalid value " ;
VAL_ 350 Checksum_CR_R_3 0 " Valid value " ;
VAL_ 350 CR_ObjSts_Ri 0 " Target Invalid " 1 " Target Valid " 2 " No target " 3 " Reserved " ;
VAL_ 350 CR_ObjID_Ri 0 " Valid value " ;
VAL_ 350 CR_ObjDistX_Ri 0 " Valid value " ;
VAL_ 350 CR_ObjDistY_Ri 0 " Valid value " ;
VAL_ 350 CR_ObjRelVelX_Ri 0 " Valid value " ;
VAL_ 350 CR_ObjRelAccelX_Ri 0 " Valid values " ;
VAL_ 350 CR_ObjMotionType_Ri 0 " int " 1 " unknown " 2 " Drive " 3 " Stopped " 4 " Stand " 5 " reserved " 6 " reserved " 7 " reserved " ;
VAL_ 350 RollingCounter_CR_R_3 0 " Valid value " 15 " Invalid value " ;
VAL_ 350 Checksum_CR_R_4 0 " Valid value " ;
VAL_ 350 CR_ObjRelAccelY_Ri 0 " Valid values " ;
VAL_ 350 CR_ObjRelVelY_Ri 0 " Valid value " ;
VAL_ 350 CR_ObjRelAccelY_Le 0 " Valid values " ;
VAL_ 350 CR_ObjRelVelY_Le 0 " Valid value " ;
VAL_ 350 RollingCounter_CR_R_4 0 " Valid value " 15 " Invalid value " ;
VAL_ 350 CR_ObjDistXStd_Le 0 " valid value " ;
VAL_ 350 CR_ObjDistYStd_Le 0 " valid value " ;
VAL_ 350 CR_ObjRelVelXStd_Le 0 " valid value " ;
VAL_ 350 CR_ObjRelVelYStd_Le 0 " valid value " ;
VAL_ 350 CR_ObjRAccelXStd_Le 0 " valid value " ;
VAL_ 350 CR_ObjRAccelYStd_Le 0 " valid value " ;
VAL_ 350 CR_ObjDistXStd_Ri 0 " valid value " ;
VAL_ 350 CR_ObjDistYStd_Ri 0 " valid value " ;
VAL_ 350 CR_ObjRelVelXStd_Ri 0 " valid value " ;
VAL_ 350 CR_ObjRelVelYStd_Ri 0 " valid value " ;
VAL_ 350 CR_ObjRAccelXStd_Ri 0 " valid value " ;
VAL_ 350 CR_ObjRAccelYStd_Ri 0 " valid value " ;
VAL_ 357 FrntWshrSwtSts 0 " OFF " 1 " Wiper Wash " 2 " Wash in Auto Mode " 3 " Reserved " ;
VAL_ 357 FrntWiprSwtSts 0 " Wiper Off " 1 " Wiper Auto Or Intermittent " 2 " Low Speed " 3 " High Speed " 4 " reserved " 7 " Error " ;
VAL_ 357 LTurnLmpSwtSts 0 " OFF " 1 " ON " ;
VAL_ 357 RTurnLmpSwtSts 0 " OFF " 1 " ON " ;
VAL_ 357 FrntFogLmpSwtSts 0 " OFF " 1 " ON " ;
VAL_ 357 LowBeamSwtSts 0 " OFF " 1 " ON " ;
VAL_ 357 HiBeamSwtSts 0 " OFF " 1 " ON " ;
VAL_ 357 OverVehBeamSwtSts 0 " OFF " 1 " ON " ;
VAL_ 357 AutoHiLowBeamSwtSts 0 " OFF " 1 " ON " ;
VAL_ 357 AutoLmpSwtSts 0 " Non-Auto " 1 " Auto " ;
VAL_ 367 RSDS_ObjRelAccelY_Le 0 " Valid values " ;
VAL_ 367 Checksum_RSDS_R_2 0 " Valid value " ;
VAL_ 367 RSDS_Brk_ErrSts 0 " No error  " 1 " Error  " ;
VAL_ 367 RSDS_BrkgReq 0 " No Request " 1 " Request " ;
VAL_ 367 RSDS_BrkgReqVal 0 " Valid value " ;
VAL_ 367 RSDS_LEDLightReqLeft 0 " No warning " 1 " Warning level 1（LED 常亮） " 2 " Warning level 2（LED 2Hz闪烁） " 3 " Warning level 3（LED 4Hz闪烁） " ;
VAL_ 367 RSDS_LEDLightReqRight 0 " No warning " 1 " Warning level 1（LED 常亮） " 2 " Warning level 2（LED 2Hz闪烁） " 3 " Warning level 3（LED 4Hz闪烁） " ;
VAL_ 367 RSDS_IPSoundReq 0 " No warning " 1 " Warning level 1（2Hz声音） " 2 " Warning level 2（4Hz声音） " 3 " Warning level 3（常响） " ;
VAL_ 367 RSDS_RCW_Trigger 0 " No warning " 1 " RCW level 1 " 2 " RCW level 2 " 3 " Reserved " ;
VAL_ 367 RSDS_ErrSts 0 " No Error " 1 " Error " ;
VAL_ 367 RSDS_BrkgTrig 0 " Not tirggered " 1 " Triggered " ;
VAL_ 367 RSDS_BliSts 0 " No Blindness " 1 " Blindness " ;
VAL_ 367 RSDS_TrailerSts 0 " None " 1 " Trailer " ;
VAL_ 367 RSDS_LCAResp 0 " OFF " 1 " ON " ;
VAL_ 367 RSDS_CTA_Actv 0 " Not active " 1 " Active " ;
VAL_ 367 RSDS_DOWResp 0 " OFF " 1 " ON " ;
VAL_ 367 RSDS_RCWResp 0 " OFF " 1 " ON " ;
VAL_ 367 RSDS_RCTAResp 0 " OFF " 1 " ON " ;
VAL_ 367 RSDS_RCTABrkResp 0 " OFF " 1 " ON " ;
VAL_ 367 BSD_LCA_warningReqRight 0 " No warning " 1 " Warning level 1 " 2 " Warning level 2 " 3 " Reserved " ;
VAL_ 367 BSD_LCA_warningReqleft 0 " No warning " 1 " Warning level 1 " 2 " Warning level 2 " 3 " Reserved " ;
VAL_ 367 DOW_warningReqRight 0 " No warning " 1 " Warning level 1 " 2 " Warning level 2 " 3 " Reserved " ;
VAL_ 367 DOW_warningReqleft 0 " No warning " 1 " Warning level 1 " 2 " Warning level 2 " 3 " Reserved " ;
VAL_ 367 RCTA_warningReqRight 0 " No warning " 1 " Warning level 2 " ;
VAL_ 367 RCTA_warningReqLeft 0 " No warning " 1 " Warning level 2 " ;
VAL_ 367 RollingCounter_RSDS_R_2 0 " Valid value " 15 " Invalid value " ;
VAL_ 367 Checksum_RSDS_R_3 0 " Valid value " ;
VAL_ 367 LeTarSts 0 " Target Invalid " 1 " Target Valid " 2 " No target " 3 " Reserved " ;
VAL_ 367 ObjIDLe 0 " Valid value " ;
VAL_ 367 ObjLgtPosnCurvLe 0 " Valid value " ;
VAL_ 367 ObjLatPosnCurvLe 0 " Valid value " ;
VAL_ 367 ObjLgtSpdCurvLe 0 " Valid value " ;
VAL_ 367 ObjLatSpdCurvLe 0 " Valid value " ;
VAL_ 367 ObjTTCLe 0 " Valid value " ;
VAL_ 367 RollingCounter_RSDS_R_3 0 " Valid value " 15 " Invalid value " ;
VAL_ 367 Checksum_RSDS_R_4 0 " Valid value " ;
VAL_ 367 ObjLenLe 0 " Valid value " ;
VAL_ 367 ObjWidthLe 0 " Valid value " ;
VAL_ 367 ObjStatyLe 0 " Stationary " 1 " Not Stationary " ;
VAL_ 367 ZoneIndLe 0 " No Object in the Zone " 1 " Object in BSW Zone " 2 " Object in CVW Zone " 3 " Object in the Shared Zone " ;
VAL_ 367 ObjStsLe 0 " Invalid " 1 " New新目标 " 2 " Mature成熟目标 " 3 " Coasted滑行的 " ;
VAL_ 367 ObjRinRi 0 " Valid value " ;
VAL_ 367 ObjWidthRi 0 " Valid value " ;
VAL_ 367 ObjStatyRi 0 " Stationary " 1 " Not Stationary " ;
VAL_ 367 ZoneIndRi 0 " No Object in the Zone " 1 " Object in BSW Zone " 2 " Object in CVW Zone " 3 " Object in the Shared Zone " ;
VAL_ 367 ObjStsRi 0 " Invalid " 1 " New " 2 " Mature " 3 " Coasted " ;
VAL_ 367 RollingCounter_RSDS_R_4 0 " Valid value " 15 " Invalid value " ;
VAL_ 367 Checksum_RSDS_R_5 0 " Valid value " ;
VAL_ 367 RiTarSts 0 " Target Invalid " 1 " Target Valid " 2 " No target " 3 " Reserved " ;
VAL_ 367 ObjIDRi 0 " Valid value " ;
VAL_ 367 ObjLgtPosnCurvRi 0 " Valid value " ;
VAL_ 367 ObjLatPosnCurvRi 0 " Valid value " ;
VAL_ 367 ObjLgtSpdCurvRi 0 " Valid value " ;
VAL_ 367 ObjLatSpdCurvRi 0 " Valid value " ;
VAL_ 367 ObjTTCRi 0 " Valid value " ;
VAL_ 367 RollingCounter_RSDS_R_5 0 " Valid value " 15 " Invalid value " ;
VAL_ 367 RSDS_ObjDistXStd_Le 0 " valid value " ;
VAL_ 367 RSDS_ObjDistYStd_Le 0 " valid value " ;
VAL_ 367 RSDS_ObjRelVelXStd_Le 0 " valid value " ;
VAL_ 367 RSDS_ObjRelVelYStd_Le 0 " valid value " ;
VAL_ 367 RSDS_ObjRAccelXStd_Le 0 " valid value " ;
VAL_ 367 RSDS_ObjRAccelYStd_Le 0 " valid value " ;
VAL_ 367 RSDS_ObjDistXStd_Ri 0 " valid value " ;
VAL_ 367 RSDS_ObjDistYStd_Ri 0 " valid value " ;
VAL_ 367 RSDS_ObjRelVelXStd_Ri 0 " valid value " ;
VAL_ 367 RSDS_ObjRelVelYStd_Ri 0 " valid value " ;
VAL_ 367 RSDS_ObjRAccelXStd_Ri 0 " valid value " ;
VAL_ 367 RSDS_ObjRAccelYStd_Ri 0 " valid value " ;
VAL_ 367 RSDS_ObjRelAccelX_Le 0 " Valid values " ;
VAL_ 367 RSDS_ObjRelAccelX_Ri 0 " Valid values " ;
VAL_ 367 RSDS_ObjRelAccelY_Ri 0 " Valid values " ;
VAL_ 395 Checksum_AEB1 0 " Valid value " ;
VAL_ 395 AEB_ABA_Level 0 " Level 0 " 1 " Level 1 " 2 " Level 2 " 3 " Level 3 " ;
VAL_ 395 AEB_ABA_Req 0 " No Request " 1 " Request " ;
VAL_ 395 EBA_TgtDecel_Req 0 " No Request " 1 " Request " ;
VAL_ 395 AEB_VehHldReq 0 " No Request " 1 " Request " ;
VAL_ 395 AEB_TgtDecel_Req 0 " No Request " 1 " Request " ;
VAL_ 395 AEB_TgtDecel_ReqValue 0 " Valid value " 65535 " Invalid " ;
VAL_ 395 AEB_AWB_Req 0 " No Request " 1 " Request " ;
VAL_ 395 AEB_AWB_Level 0 " No level " 1 " Level 1 " 2 " Level 2 " 3 " Level 3 " 4 " Level 4 " 5 " Resvered " ;
VAL_ 395 AEB_ABP_Req 0 " No Request " 1 " Request " ;
VAL_ 395 AEB_BrkReqFunc 0 " No Request " 1 " AEB-V " 2 " AEB-VRU " 3 " AEB-JA " 4 " Reserved " 5 " AEB-FCTB " 6 " Reserved " ;
VAL_ 395 AEB_ObjSty 0 " No Object " 1 " Vehicle " 2 " Pedestrian " 3 " Cyclist " 4 " unknown " 5 " Resvered " ;
VAL_ 395 RollingCounter_AEB1 0 " Valid value " 15 " Invalid value " ;
VAL_ 411 FFogLmpSts_F_Pbox 0 " Off " 1 " On " ;
VAL_ 411 HiBeamSts_F_Pbox 0 " Off " 1 " On " ;
VAL_ 411 HoodSts_F_Pbox 0 " Closed " 1 " Open " ;
VAL_ 411 LHeadLmpFailSts 0 " No failure " 1 " failure " ;
VAL_ 411 RHeadLmpFailSts 0 " No failure " 1 " failure " ;
VAL_ 411 LowBeamSts_F_Pbox 0 " Off " 1 " On " ;
VAL_ 412 HiPosnBrkLmpFailSts 0 " No failure " 1 " failure " ;
VAL_ 412 LBrkLmpFailSts 0 " No failure " 1 " failure " ;
VAL_ 412 RFogLmpFailSts_R_Pbox 0 " No failure " 1 " failure " ;
VAL_ 412 RFogLmpSts_R_Pbox 0 " Off " 1 " On " ;
VAL_ 412 RBrkLmpFailSts 0 " No failure " 1 " failure " ;
VAL_ 412 PosnLmpOutpSts_R_Pbox 0 " OFF " 1 " ON " ;
VAL_ 412 LTurnLmpSts_R_Pbox 0 " Off " 1 " On " ;
VAL_ 412 RTurnLmpSts_R_Pbox 0 " Off " 1 " On " ;
VAL_ 415 IFC_Line01_Dy 0 " Valid value " 6002 " Reversed " ;
VAL_ 415 IFC_Line01_Curv 0 " Valid value " 31251 " Reversed " ;
VAL_ 415 IFC_Line01_CurvChange 0 " Valid value " 960001 " Reversed " ;
VAL_ 415 IFC_Line01_Type 0 " undecided " 1 " solid " 2 " dashed " 3 " double solid dashed " 4 " double dashed solid " 5 " double solid solid " 6 " double dashed dashed " 7 " botts " 8 " deceleration " 9 " hov_lane " 10 " road edge " 11 " elevated_structure " 12 " curb " 13 " cones_poles " ;
VAL_ 415 IFC_Line02_Dy 0 " Valid value " 6002 " Reversed " ;
VAL_ 415 IFC_Line02_Curv 0 " Valid value " 31251 " Reversed " ;
VAL_ 415 IFC_Line02_CurvChange 0 " Valid value " 960001 " Reversed " ;
VAL_ 415 IFC_Line02_Type 0 " undecided " 1 " solid " 2 " dashed " 3 " double solid dashed " 4 " double dashed solid " 5 " double solid solid " 6 " double dashed dashed " 7 " botts " 8 " deceleration " 9 " hov_lane " 10 " road edge " 11 " elevated_structure " 12 " curb " 13 " cones_poles " ;
VAL_ 415 IFC_Line03_Dy 0 " valid value " 6002 " reversed " ;
VAL_ 415 IFC_Line03_Curv 0 " valid value " 31251 " reversed " ;
VAL_ 415 IFC_Line03_CurvChange 0 " valid value " 960001 " reversed " ;
VAL_ 415 IFC_Line03_Type 0 " undecided " 1 " solid " 2 " dashed " 3 " double solid dashed " 4 " double dashed solid " 5 " double solid solid " 6 " double dashed dashed " 7 " botts " 8 " deceleration " 9 " hov_lane " 10 " road edge " 11 " elevated_structure " 12 " curb " 13 " cones_poles " ;
VAL_ 415 IFC_Line04_Dy 0 " valid value " 6002 " reversed " ;
VAL_ 415 IFC_Line04_Curv 0 " valid value " 31251 " reversed " ;
VAL_ 415 IFC_Line04_CurvChange 0 " valid value " 960001 " reversed " ;
VAL_ 415 IFC_Line04_Type 0 " undecided " 1 " solid " 2 " dashed " 3 " double solid dashed " 4 " double dashed solid " 5 " double solid solid " 6 " double dashed dashed " 7 " botts " 8 " deceleration " 9 " hov_lane " 10 " road edge " 11 " elevated_structure " 12 " curb " 13 " cones_poles " ;
VAL_ 415 IFC_Roadedge01_Dy 0 " valid value " 6002 " reversed " ;
VAL_ 415 IFC_Roadedge01_Curv 0 " valid value " 31251 " reversed " ;
VAL_ 415 IFC_Roadedge01_CurvChange 0 " 0xEA601-0xFFFFF reversed " ;
VAL_ 415 IFC_Roadedge01_Type 0 " undecided " 1 " solid " 2 " dashed " 3 " double solid dashed " 4 " double dashed solid " 5 " double solid solid " 6 " double dashed dashed " 7 " botts " 8 " deceleration " 9 " hov_lane " 10 " road edge " 11 " elevated_structure " 12 " curb " 13 " cones_poles " ;
VAL_ 415 IFC_Roadedge02_Dy 0 " valid value " 6002 " reversed " ;
VAL_ 415 IFC_Roadedge02_Curv 0 " valid value " 31251 " -0x7FFF " ;
VAL_ 415 IFC_Roadedge02_CurvChange 0 " valid value " 960001 " -0xFFFFF " ;
VAL_ 415 IFC_Roadedge02_Type 0 " undecided " 1 " solid " 2 " dashed " 3 " double solid dashed " 4 " double dashed solid " 5 " double solid solid " 6 " double dashed dashed " 7 " botts " 8 " deceleration " 9 " hov_lane " 10 " road edge " 11 " elevated_structure " 12 " curb " 13 " cones_poles " ;
VAL_ 416 CheckSum_LMU1 0 " Valid values " ;
VAL_ 416 LMUSysSts 0 " not avaliable " 1 " avaliable " 2 " external failure " 3 " internal failure " ;
VAL_ 416 RollingCounter_LMU1 0 " Valid value " 15 " Invalid value " ;
VAL_ 474 HUT_HAVP_APA_Permit 0 " Idle " 1 " NO " 2 " YES " 3 " Reserved " ;
VAL_ 474 HUT_HAVP_Return_Btn 0 " No Request " 1 " Request " ;
VAL_ 474 HUT_HAVP_Set_Starting 0 " No Request " 1 " Request " ;
VAL_ 474 HUT_HAVP_SelfParLot_Ending 0 " No Request " 1 " Request " ;
VAL_ 474 HUT_HAVP_Comfirm_Btn 0 " No Request " 1 " Request " ;
VAL_ 474 HUT_HAVP_Learning_Set_ParkLot 0 " No Request " 1 " Fixed parking lot " 2 " Random parking lot " 3 " Reserved " ;
VAL_ 474 HUT_HAVP_Set_Path_Ending 0 " No request " 1 " Request " ;
VAL_ 474 HUT_HAVP_LearningTypeSele 0 " No request " 1 " Request Parking out path " 2 " Request Parking in path " 3 " Reserved " ;
VAL_ 474 HUT_HAVP_Path_Delete 0 " No Request " 1 " Valid values " 11 " Reserved " ;
VAL_ 474 HUT_HAVP_Path_Select 0 " No Request " 1 " Valid values " 11 " Reserved " ;
VAL_ 474 HUT_HAVP_Path_SetTop 0 " No Request " 1 " Valid values " 11 " Reserved " ;
VAL_ 474 SlotNum_VR 0 " Valid values " 6 " Invalid " ;
VAL_ 474 HUT_PAVP_Confirm 0 " No request " 1 " Request " ;
VAL_ 474 HUT_PAVP_DropOff_Area_req 0 " No request " 1 " Request " ;
VAL_ 474 HUT_PAVP_PathList_Req 0 " No request " 1 " Request " ;
VAL_ 474 UserDefinedParkCmd 0 " No Request " 1 " Request  " ;
VAL_ 474 UserDefPrkMenuSelCmd 0 " No Request " 1 " Parallel Slot Selected " 2 " Vertical Slot Selected " 3 " Reserved " 4 " Reserved " 5 " Clock wise Selected " 6 " Anticlock wise Selected " 7 " Reserved " ;
VAL_ 493 PrkInDirChoice 0 " None " 1 " Tail in " 2 " Head in  " 3 " Reserved " ;
VAL_ 493 PathLrngFinshCmd 0 " No request " 1 " Request " ;
VAL_ 493 PathLrngStartCmd 0 " No request " 1 " Request " ;
VAL_ 493 SelPrkOutDirReq 0 " No selection " 1 " Park out front/vertical head out " 2 " Park out rear/vertical tail out " 3 " Park out left/parallel left out  " 4 " Park out right/parallel right out " 5 " Reserved " ;
VAL_ 493 StartPrkgPath2Cmd 0 " No request " 1 " Request " ;
VAL_ 493 DeletePath2Cmd 0 " No request " 1 " Request " ;
VAL_ 493 StartPrkgPath1Cmd 0 " No request " 1 " Request " ;
VAL_ 493 DeletePath1Cmd 0 " No request " 1 " Request " ;
VAL_ 493 ParkMdlCmd 0 " No request " 1 " Request " ;
VAL_ 493 BackReq_APS 0 " No request " 1 " Request " ;
VAL_ 493 SelPrkgFctnCmd 0 " No selection " 1 " Select APA parking " 2 " Select P2P parking " 3 " Select Explore Forward " 4 " Select drive back " 5 " Select HAVP Parking " 6 " Select PAVP Parking " 7 " Reserved " ;
VAL_ 493 P2P_PrkgDirectSwtCmd 0 " No Request " 1 " Request " ;
VAL_ 494 SDWSwtSet 0 " No Request " 1 " Request " ;
VAL_ 494 APSSwtReq_VR 0 " No action " 1 " off " 2 " on " 3 " Reserved " ;
VAL_ 494 APSPrkgTypSeln 0 " No Select " 1 " Select parallel parking " 2 " Select vertical parking " 3 " Reserved " ;
VAL_ 515 HUT_OD_Obj0_ID 0 " Valid values " 10 " Invalid values " ;
VAL_ 515 HUT_OD_Obj0_type 0 " No target " 1 " Pedestrian or Biker " 2 " Vehicle " 3 " Ground Locker or Barrier " 4 " Unknown type " 5 " Invalid values " ;
VAL_ 515 HUT_OD_Obj0_Confidence 0 " 0-1 " 11 " Invalid values " ;
VAL_ 515 HUT_OD_Obj0_width 0 " Valid values " 127 " Invalid values " ;
VAL_ 515 HUT_OD_Obj0_Ground_Pos_X 0 " Valid values " 4001 " Reserved " 4095 " Invalid values " ;
VAL_ 515 HUT_OD_Obj0_Ground_Pos_Y 0 " Valid values " 4001 " Reserved " 4095 " Invalid values " ;
VAL_ 515 HTU_OD_Obj1_ID 0 " Valid values " 10 " Invalid values " ;
VAL_ 515 HUT_OD_Obj1_type 0 " No target " 1 " Pedestrian or Biker " 2 " Vehicle " 3 " Ground Locker or Barrier " 4 " Unknown type " 5 " Invalid values " ;
VAL_ 515 HUT_OD_Obj1_Confidence 0 " 0-1 " 11 " Invalid values " ;
VAL_ 515 HUT_OD_Obj1_width 0 " Valid values " 127 " Invalid values " ;
VAL_ 515 HUT_OD_Obj1_Ground_Pos_X 0 " Valid values " 4001 " Reserved " 4095 " Invalid values " ;
VAL_ 515 HUT_OD_Obj1_Ground_Pos_Y 0 " Valid values " 4001 " Reserved " 4095 " Invalid values " ;
VAL_ 515 HUT_OD_Obj2_ID 0 " Valid values " 10 " Invalid values " ;
VAL_ 515 HUT_OD_Obj2_type 0 " No target " 1 " Pedestrian or Biker " 2 " Vehicle " 3 " Ground Locker or Barrier " 4 " Unknown type " 5 " Invalid values " ;
VAL_ 515 HUT_OD_Obj2_Confidence 0 " 0-1 " 11 " Invalid values " ;
VAL_ 515 HUT_OD_Obj2_width 0 " Valid values " 127 " Invalid values " ;
VAL_ 515 HUT_OD_Obj2_Ground_Pos_X 0 " Valid values " 4001 " Reserved " 4095 " Invalid values " ;
VAL_ 515 HUT_OD_Obj2_Ground_Pos_Y 0 " Valid values " 4001 " Reserved " 4095 " Invalid values " ;
VAL_ 515 HUT_OD_Obj3_ID 0 " Valid values " 10 " Invalid values " ;
VAL_ 515 HUT_OD_Obj3_type 0 " No target " 1 " Pedestrian or Biker " 2 " Vehicle " 3 " Ground Locker or Barrier " 4 " Unknown type " 5 " Invalid values " ;
VAL_ 515 HUT_OD_Obj3_Confidence 0 " 0-1 " 11 " Invalid values " ;
VAL_ 515 HUT_OD_Obj3_width 0 " Valid values " 127 " Invalid values " ;
VAL_ 515 HUT_OD_Obj3_Ground_Pos_X 0 " Valid values " 4001 " Reserved " 4095 " Invalid values " ;
VAL_ 515 HUT_OD_Obj3_Ground_Pos_Y 0 " Valid values " 4001 " Reserved " 4095 " Invalid values " ;
VAL_ 515 HUT_OD_Obj4_ID 0 " Valid values " 10 " Invalid values " ;
VAL_ 515 HUT_OD_Obj4_type 0 " No target " 1 " Pedestrian or Biker " 2 " Vehicle " 3 " Ground Locker or Barrier " 4 " Unknown type " 5 " Invalid values " ;
VAL_ 515 HUT_OD_Obj4_Confidence 0 " 0-1 " 11 " Invalid values " ;
VAL_ 515 HUT_OD_Obj4_width 0 " Valid values " 127 " Invalid values " ;
VAL_ 515 HUT_OD_Obj4_Ground_Pos_X 0 " Valid values " 4001 " Reserved " 4095 " Invalid values " ;
VAL_ 515 HUT_OD_Obj4_Ground_Pos_Y 0 " Valid values " 4001 " Reserved " 4095 " Invalid values " ;
VAL_ 515 HUT_OD_Obj5_ID 0 " Valid values " 10 " Invalid values " ;
VAL_ 515 HUT_OD_Obj5_type 0 " No target " 1 " Pedestrian or Biker " 2 " Vehicle " 3 " Ground Locker or Barrier " 4 " Unknown type " 5 " Invalid values " ;
VAL_ 515 HUT_OD_Obj5_Confidence 0 " 0-1 " 11 " Invalid values " ;
VAL_ 515 HUT_OD_Obj5_width 0 " Valid values " 127 " Invalid values " ;
VAL_ 515 HUT_OD_Obj5_Ground_Pos_X 0 " Valid values " 4001 " Reserved " 4095 " Invalid values " ;
VAL_ 515 HUT_OD_Obj5_Ground_Pos_Y 0 " Valid values " 4001 " Reserved " 4095 " Invalid values " ;
VAL_ 515 HUT_OD_Obj6_ID 0 " Valid values " 10 " Invalid values " ;
VAL_ 515 HUT_OD_Obj6_type 0 " No target " 1 " Pedestrian or Biker " 2 " Vehicle " 3 " Ground Locker or Barrier " 4 " Unknown type " 5 " Invalid values " ;
VAL_ 515 HUT_OD_Obj6_Confidence 0 " 0-1 " 11 " Invalid values " ;
VAL_ 515 HUT_OD_Obj6_width 0 " Valid values " 127 " Invalid values " ;
VAL_ 515 HUT_OD_Obj6_Ground_Pos_X 0 " Valid values " 4001 " Reserved " 4095 " Invalid values " ;
VAL_ 515 HUT_OD_Obj6_Ground_Pos_Y 0 " Valid values " 4001 " Reserved " 4095 " Invalid values " ;
VAL_ 536 DCDC_ActSts 0 " Standby " 1 " discharge " 2 " Buck " 3 " Precharge " 4 " Reserved " 5 " failure " 6 " Reserved " 7 " Reserved " 8 " DCDC init mode " 9 " Reserved " 13 " Sleep mode " 14 " Presleep " 15 " OFF " ;
VAL_ 546 IFC_Line01_DxStart 0 " valid value  " 20002 " reversed " ;
VAL_ 546 IFC_Line01_DxEnd 0 " valid value  " 20002 " reversed " ;
VAL_ 546 IFC_Line01_HeadingAngle 0 " valid value " 402 " reversed " ;
VAL_ 546 IFC_Line02_HeadingAngle 0 " valid value " 402 " reversed " ;
VAL_ 546 IFC_Line02_DxStart 0 " valid value  " 20002 " reversed " ;
VAL_ 546 IFC_Line02_DxEnd 0 " valid value  " 20002 " reversed " ;
VAL_ 546 IFC_Line03_DxStart 0 " valid value  " 20002 " reversed " ;
VAL_ 546 IFC_Line03_DxEnd 0 " valid value  " 20002 " reversed " ;
VAL_ 546 IFC_Line03_HeadingAngle 0 " valid value " 402 " reversed " ;
VAL_ 546 IFC_Line04_DxStart 0 " valid value  " 20002 " reversed " ;
VAL_ 546 IFC_Line04_HeadingAngle 0 " valid value " 402 " reversed " ;
VAL_ 546 IFC_Line04_DxEnd 0 " valid value  " 20002 " reversed " ;
VAL_ 546 IFC_Roadedge01_DxStart 0 " valid value  " 20002 " reversed " ;
VAL_ 546 IFC_Roadedge01_DxEnd 0 " valid value  " 20002 " reversed " ;
VAL_ 546 IFC_Roadedge01_HeadingAngle 0 " valid value " 402 " reversed " ;
VAL_ 546 IFC_Roadedge02_DxStart 0 " valid value  " 20002 " reversed " ;
VAL_ 546 IFC_Roadedge02_DxEnd 0 " valid value  " 20002 " reversed " ;
VAL_ 546 IFC_Roadedge02_HeadingAngle 0 " valid value " 402 " reversed " ;
VAL_ 546 CheckSum_IFC_HCM8 0 " Valid values " ;
VAL_ 546 Spots8HozlPosnLeAng 0 " valid value " 1001 " Reserved " 1023 " NotAvailable " ;
VAL_ 546 Spots8HozlPosnRiAng 0 " valid value " 1001 " Reserved " 1023 " NotAvailable " ;
VAL_ 546 Spots8Valid 0 " Invalid " 1 " Valid " ;
VAL_ 546 Spots8Typ 0 " Unknown  " 1 " Oncoming object " 2 " Preceding object " 3 " Reflective object " ;
VAL_ 546 Spots8Distance 0 " valid value " 511 " NotAvailable " ;
VAL_ 546 Spots8HozLeAngSpd 0 " Valid Values " ;
VAL_ 546 Spot8VertAng 0 " Valid Values " ;
VAL_ 546 Spots8TrackingInfo 0 " Not Tracking " 1 " Tracking " ;
VAL_ 546 Spots8VehObjClassn 0 " No Vehicle " 1 " Car " 2 " Truck " 3 " Bus " 4 " BikeOrMotoBike " 5 " Pedestrain " 6 " Mixed " 7 " Unknow " ;
VAL_ 546 RollingCounter_IFC_HCM8 0 " Valid value " 15 " Invalid value " ;
VAL_ 546 CheckSum_IFC_HCM9 0 " Valid values " ;
VAL_ 546 AmbLight 0 " Not Active for HighBeam " 1 " Active for HighBeam " ;
VAL_ 546 RoadIllumDetd 0 " Road illumination Not detected " 1 " Road illumination detected " ;
VAL_ 546 TrafficStyle 0 " Unknow " 1 " RightHandTraffic " 2 " LeftHandTraffic " 3 " Not available " ;
VAL_ 546 CameraSts 0 " Not Available for ADB " 1 " Available for ADB " 2 " Camera Fault " 3 " reserved " ;
VAL_ 546 RollingCounter_IFC_HCM9 0 " Valid value " 15 " Invalid value " ;
VAL_ 551 Checksum_AEB2 0 " Valid value " ;
VAL_ 551 AEB_PedResp 0 " OFF " 1 " ON " ;
VAL_ 551 AEB_VehResp 0 " OFF " 1 " ON " ;
VAL_ 551 FCW_Snvty 0 " Normal " 1 " High sensitivity " 2 " Low sensitivity " 3 " Reserved " ;
VAL_ 551 AEB_JA_Resp 0 " OFF " 1 " ON " ;
VAL_ 551 RollingCounter_AEB2 0 " Valid value " 15 " Invalid value " ;
VAL_ 551 Checksum_AEB3 0 " Valid value " ;
VAL_ 551 AEB_VehTrig 0 " not tirggered " 1 " triggered " ;
VAL_ 551 AEB_PedTrig 0 " not tirggered " 1 " triggered " ;
VAL_ 551 FCW_AEB_VehFctSts 0 " No display  " 1 " error  " 2 " FCW/AEB_V temporarily unavailable " 3 " FCW/AEB_V Performance degradation " ;
VAL_ 551 FCW_AEB_PedFctSts 0 " No display " 1 " error " 2 " FCW/AEB_P temporarily unavailable " 3 " FCW/AEB_P Performance degradation " ;
VAL_ 551 FCW_Warn 0 " No warning " 1 " Latent warning  " 2 " warning Level 1   " 3 " warning Level 2 " ;
VAL_ 551 AEB_JAFuncSts 0 " No display " 1 " error " 2 " FCW/AEB_JA temporarily unavailable " 3 " FCW/AEB_JA Performance degradation " ;
VAL_ 551 AEB_JA_Warn 0 " No warning " 1 " Warning  for vehicle " 2 " Warning for pedestrian " 3 " reverse " ;
VAL_ 551 AEB_JABrkTrig 0 " Not tirggered " 1 " AEB_JA Function Triggered for vehicle " 2 " AEB_JA Function Triggered for pedestrian " 3 " reverse " ;
VAL_ 551 RollingCounter_AEB3 0 " Valid value " 15 " Invalid value " ;
VAL_ 555 CheckSum_HOD_1 0 " Valid values " ;
VAL_ 555 HOD_ErrInfo 0 " NO_ERROR " 1 " HOD_EEPROM_ERROR " 2 " HOD_ROM_ERROR " 3 " HOD_WATCHDOG_ERROR " 4 " HOD_CPU_ERROR " 5 " HOD_GUARD_INTERRUPTION_ERROR " 6 " HOD_SENSE_INTERRUPTION_ERROR " 7 " HOD_CPU_DEFECT_OR_MAT_SHORTAGE " 8 " UNDERVOLTAGE_ERROR " 9 " OVERVOLTAGE_ERROR " 10 " HOD_CODING_ERROR " 11 " HOD_GENERIC_SYSTEM_ERROR " 12 " Not_Used " 15 " SNA " ;
VAL_ 555 HOD_HandOffSts 0 " HANDS_OFF_DETECTED " 1 " Not uesd " 2 " HANDS_OFF_NOT_DETECTED " 3 " HANDS_NOT_AVAILABLE " 4 " HANDS_OFF_ERROR " 5 " Not used " 15 " SNA " ;
VAL_ 555 RollingCounter_HOD_1 0 " Valid value " 15 " Invalid value " ;
VAL_ 568 SrPosn_VR_APP 0 " Tilt up " 1 " reserved " 10 " 10% " 11 " reserved " 20 " 20% " 21 " reserved " 30 " 30% " 31 " reserved " 40 " 40% " 41 " reserved " 50 " 50% " 51 " reserved " 60 " 60% " 61 " reserved " 70 " 70% " 71 " reserved " 80 " 80% " 81 " reserved " 90 " 90% " 91 " reserved " 100 " Fully open " 101 " Fully close " 102 " Vent area " 103 " reserved " ;
VAL_ 568 RLS_FwBrightness 0 " Vaild value " 4095 " Invaild " ;
VAL_ 568 RLS_AmbBrightness 0 " Vaild value " 4095 " Invaild " ;
VAL_ 573 Checksum_IFC3 0 " Valid value " ;
VAL_ 573 LDWResp 0 " OFF " 1 " ON " ;
VAL_ 573 LKAResp 0 " OFF " 1 " ON " ;
VAL_ 573 LCKResp 0 " OFF " 1 " ON " ;
VAL_ 573 ELKResp 0 " OFF " 1 " ON " ;
VAL_ 573 AESResp 0 " OFF " 1 " ON " ;
VAL_ 573 LDW_LKA_Snvty 0 " Normal " 1 " High sensitivity " 2 " Low sensitivity " 3 " Reserved " ;
VAL_ 573 IFCHUTInterface 0 " No response " 1 " Response " ;
VAL_ 573 ESS_PedResp 0 " OFF " 1 " ON " ;
VAL_ 573 ESS_VehResp 0 " OFF " 1 " ON " ;
VAL_ 573 LSSWarnFormResp 0 " Voice " 1 " Haptic " 2 " Voice+Haptic " 3 " Reserved " ;
VAL_ 573 LSSResp 0 " OFF " 1 " ON " ;
VAL_ 573 IntelligentEvaResp 0 " OFF " 1 " ON " ;
VAL_ 573 AESSts 0 " OFF " 1 " ON " 2 " Reserved " ;
VAL_ 573 ESSSts 0 " OFF " 1 " ON " 2 " Reserved " ;
VAL_ 573 AESErrSts 0 " No Error " 1 " Error " ;
VAL_ 573 ESSErrSts 0 " No Error " 1 " Error " ;
VAL_ 573 RollingCounter_IFC3 0 " Valid value " 15 " Invalid value " ;
VAL_ 573 Checksum_IFC4 0 " Valid value " ;
VAL_ 573 IFC_Handsoffwarn 0 " No warning " 1 " Level1 warning " 2 " Level2 warning " 3 " Level3 warning " 4 " Level4 warning " 5 " Level5 warning " 6 " LKA warning " 7 " Reserved " ;
VAL_ 573 IFCCalibrationSts 0 " Calibration Success " 1 " Calibration In Process " 2 " Calibration Failed " 3 " Reserved " ;
VAL_ 573 CameraBlockageSts 0 " Camera Not Blocked " 1 " Camera Blocked " ;
VAL_ 573 LDW_LKAWarn 0 " No LDW_LKA warning " 1 " LDW_LKA left warning " 2 " LDW_LKA right warning " 3 " Reserved " ;
VAL_ 573 LSSIntervention 0 " No warning and Intervention  " 1 " Left warning  " 2 " Right warning " 3 " Left Intervention  " 4 " Right Intervention  " 5 " Both Intervention  " 6 " Left warn only reminder " 7 " Right warn only reminder " ;
VAL_ 573 LSSFuncSts 0 " OFF " 1 " LDW on " 2 " LKA on " 3 " LCK ON " 4 " Reserved " ;
VAL_ 573 ELKMainState 0 " ELK-OFF(关闭) " 1 " ELK-Standby(开启) " 2 " ELK-Enable(已使能，不满足扭矩介入条件) " 3 " ELK-Road edge Active(道路边缘扭矩介入) " 4 " ELK-Oncoming Active（oncoming扭矩介入） " 5 " ELK-Overtaking Active（overtaking扭矩介入） " 6 " ELK-Failure " 7 " Reserved " ;
VAL_ 573 LaneAvailability 0 " Not Avaliable " 1 " Left Lane Marker Available " 2 " Right Lane Marker Available " 3 " Both Lane Markers Available " ;
VAL_ 573 TJA_FollowSts 0 " No Follow " 1 " Follow Vehicle " 2 " Reserved " ;
VAL_ 573 LSSErrSts 0 " No error " 1 " LDW error " 2 " LKA error " 3 " LCK error " 4 " ELK error " 5 " ESS error " 6 " Reserved  " ;
VAL_ 573 AESintervention 0 " No intervention " 1 " Left intervention " 2 " Right intervention " 3 " Reserved " ;
VAL_ 573 ESSintervention 0 " No intervention " 1 " Left intervention " 2 " Right intervention " 3 " Reserved " ;
VAL_ 573 ELKActSts 0 " Inactive " 1 " Left Active " 2 " Right active " 3 " Reserved " ;
VAL_ 573 IntelligentEvaActSts 0 " Inactive " 1 " Left Eva " 2 " Right Eva " 3 " Reserved " ;
VAL_ 573 LCKStsIndcr 0 " No indicator " 1 " Active indicator " 2 " Passive indicator " 3 " Reserved " ;
VAL_ 573 RollingCounter_IFC4 0 " Valid value " 15 " Invalid value " ;
VAL_ 573 Checksum_IFC5 0 " Valid value " ;
VAL_ 573 IFC_LaneCurve 0 " Valid value " 4095 " Reserved " ;
VAL_ 573 IFC_LeLaneTyp 0 " No display " 1 " Solid lane " 2 " Dashed lane " 3 " Rode edge " 4 " Reserved " ;
VAL_ 573 IFC_RiLaneTyp 0 " No display " 1 " Solid lane " 2 " Dashed lane " 3 " Rode edge " 4 " Reserved " ;
VAL_ 573 IFC_NextLeLaneTyp 0 " No display " 1 " Solid lane " 2 " Dashed lane " 3 " Rode edge " 4 " Reserved " ;
VAL_ 573 IFC_NextRiLaneTyp 0 " No display " 1 " Solid lane " 2 " Dashed lane " 3 " Rode edge " 4 " Reserved " ;
VAL_ 573 IFC_LeLane_dy 0 " Valid value " 4095 " Invalid value " ;
VAL_ 573 IFC_RiLane_dy 0 " Valid value " 4095 " Invalid value " ;
VAL_ 573 RollingCounter_IFC5 0 " Valid value " 15 " Invalid value " ;
VAL_ 573 Checksum_IFC6 0 " Valid value " ;
VAL_ 573 IFC_NextLeLane_dy 0 " Valid value " 4095 " Invalid value " ;
VAL_ 573 IFC_NextRiLane_dy 0 " Valid value " 4095 " Invalid value " ;
VAL_ 573 RollingCounter_IFC6 0 " Valid value " 15 " Invalid value " ;
VAL_ 576 CheckSum_IFC_HCM1 0 " Valid values " ;
VAL_ 576 Spots1HozlPosnRiAng 0 " valid value " 1001 " Reserved " 1023 " NotAvailable " ;
VAL_ 576 Spots1HozlPosnLeAng 0 " valid value " 1001 " Reserved " 1023 " NotAvailable " ;
VAL_ 576 Spots1Valid 0 " Invalid " 1 " Valid " ;
VAL_ 576 Spots1Typ 0 " Unknown  " 1 " Oncoming object " 2 " Preceding object " 3 " Reflective object " ;
VAL_ 576 Spots1Distance 0 " valid value " 511 " NotAvailable " ;
VAL_ 576 Spots1HozLeAngSpd 0 " Valid Values " ;
VAL_ 576 Spot1VertAng 0 " Valid Values " ;
VAL_ 576 Spots1TrackingInfo 0 " Not Tracking " 1 " Tracking " ;
VAL_ 576 Spots1VehObjClassn 0 " No Vehicle " 1 " Car " 2 " Truck " 3 " Bus " 4 " BikeOrMotoBike " 5 " Pedestrain " 6 " Mixed " 7 " Unknow " ;
VAL_ 576 RollingCounter_IFC_HCM1 0 " Valid value " 15 " Invalid value " ;
VAL_ 576 CheckSum_IFC_HCM2 0 " Valid values " ;
VAL_ 576 Spots2HozlPosnLeAng 0 " valid value " 1001 " Reserved " 1023 " NotAvailable " ;
VAL_ 576 Spots2HozlPosnRiAng 0 " valid value " 1001 " Reserved " 1023 " NotAvailable " ;
VAL_ 576 Spots2Valid 0 " Invalid " 1 " Valid " ;
VAL_ 576 Spots2Typ 0 " Unknown  " 1 " Oncoming object " 2 " Preceding object " 3 " Reflective object " ;
VAL_ 576 Spots2Distance 0 " valid value " 511 " NotAvailable " ;
VAL_ 576 Spots2HozLeAngSpd 0 " Valid Values " ;
VAL_ 576 Spot2VertAng 0 " Valid Values " ;
VAL_ 576 Spots2TrackingInfo 0 " Not Tracking " 1 " Tracking " ;
VAL_ 576 Spots2VehObjClassn 0 " No Vehicle " 1 " Car " 2 " Truck " 3 " Bus " 4 " BikeOrMotoBike " 5 " Pedestrain " 6 " Mixed " 7 " Unknow " ;
VAL_ 576 RollingCounter_IFC_HCM2 0 " Valid value " 15 " Invalid value " ;
VAL_ 576 CheckSum_IFC_HCM3 0 " Valid values " ;
VAL_ 576 Spots3HozlPosnLeAng 0 " valid value " 1001 " Reserved " 1023 " NotAvailable " ;
VAL_ 576 Spots3HozlPosnRiAng 0 " valid value " 1001 " Reserved " 1023 " NotAvailable " ;
VAL_ 576 Spots3Valid 0 " Invalid " 1 " Valid " ;
VAL_ 576 Spots3Typ 0 " Unknown  " 1 " Oncoming object " 2 " Preceding object " 3 " Reflective object " ;
VAL_ 576 Spots3Distance 0 " valid value " 511 " NotAvailable " ;
VAL_ 576 Spots3HozLeAngSpd 0 " Valid Values " ;
VAL_ 576 Spot3VertAng 0 " Valid Values " ;
VAL_ 576 Spots3TrackingInfo 0 " Not Tracking " 1 " Tracking " ;
VAL_ 576 Spots3VehObjClassn 0 " No Vehicle " 1 " Car " 2 " Truck " 3 " Bus " 4 " BikeOrMotoBike " 5 " Pedestrain " 6 " Mixed " 7 " Unknow " ;
VAL_ 576 RollingCounter_IFC_HCM3 0 " Valid value " 15 " Invalid value " ;
VAL_ 576 CheckSum_IFC_HCM4 0 " Valid values " ;
VAL_ 576 Spots4HozlPosnLeAng 0 " valid value " 1001 " Reserved " 1023 " NotAvailable " ;
VAL_ 576 Spots4HozlPosnRiAng 0 " valid value " 1001 " Reserved " 1023 " NotAvailable " ;
VAL_ 576 Spots4Valid 0 " Invalid " 1 " Valid " ;
VAL_ 576 Spots4Typ 0 " Unknown  " 1 " Oncoming object " 2 " Preceding object " 3 " Reflective object " ;
VAL_ 576 Spots4Distance 0 " valid value " 511 " NotAvailable " ;
VAL_ 576 Spots4HozLeAngSpd 0 " Valid Values " ;
VAL_ 576 Spot4VertAng 0 " Valid Values " ;
VAL_ 576 Spots4TrackingInfo 0 " Not Tracking " 1 " Tracking " ;
VAL_ 576 Spots4VehObjClassn 0 " No Vehicle " 1 " Car " 2 " Truck " 3 " Bus " 4 " BikeOrMotoBike " 5 " Pedestrain " 6 " Mixed " 7 " Unknow " ;
VAL_ 576 RollingCounter_IFC_HCM4 0 " Valid value " 15 " Invalid value " ;
VAL_ 576 CheckSum_IFC_HCM5 0 " Valid values " ;
VAL_ 576 Spots5HozlPosnLeAng 0 " valid value " 1001 " Reserved " 1023 " NotAvailable " ;
VAL_ 576 Spots5HozlPosnRiAng 0 " valid value " 1001 " Reserved " 1023 " NotAvailable " ;
VAL_ 576 Spots5Valid 0 " Invalid " 1 " Valid " ;
VAL_ 576 Spots5Typ 0 " Unknown  " 1 " Oncoming object " 2 " Preceding object " 3 " Reflective object " ;
VAL_ 576 Spots5Distance 0 " valid value " 511 " NotAvailable " ;
VAL_ 576 Spots5HozLeAngSpd 0 " Valid Values " ;
VAL_ 576 Spot5VertAng 0 " Valid Values " ;
VAL_ 576 Spots5TrackingInfo 0 " Not Tracking " 1 " Tracking " ;
VAL_ 576 Spots5VehObjClassn 0 " No Vehicle " 1 " Car " 2 " Truck " 3 " Bus " 4 " BikeOrMotoBike " 5 " Pedestrain " 6 " Mixed " 7 " Unknow " ;
VAL_ 576 RollingCounter_IFC_HCM5 0 " Valid value " 15 " Invalid value " ;
VAL_ 576 CheckSum_IFC_HCM6 0 " Valid values " ;
VAL_ 576 Spots6HozlPosnLeAng 0 " valid value " 1001 " Reserved " 1023 " NotAvailable " ;
VAL_ 576 Spots6HozlPosnRiAng 0 " valid value " 1001 " Reserved " 1023 " NotAvailable " ;
VAL_ 576 Spots6Valid 0 " Invalid " 1 " Valid " ;
VAL_ 576 Spots6Typ 0 " Unknown  " 1 " Oncoming object " 2 " Preceding object " 3 " Reflective object " ;
VAL_ 576 Spots6Distance 0 " valid value " 511 " NotAvailable " ;
VAL_ 576 Spots6HozLeAngSpd 0 " Valid Values " ;
VAL_ 576 Spot6VertAng 0 " Valid Values " ;
VAL_ 576 Spots6TrackingInfo 0 " Not Tracking " 1 " Tracking " ;
VAL_ 576 Spots6VehObjClassn 0 " No Vehicle " 1 " Car " 2 " Truck " 3 " Bus " 4 " BikeOrMotoBike " 5 " Pedestrain " 6 " Mixed " 7 " Unknow " ;
VAL_ 576 RollingCounter_IFC_HCM6 0 " Valid value " 15 " Invalid value " ;
VAL_ 576 CheckSum_IFC_HCM7 0 " Valid values " ;
VAL_ 576 Spots7HozlPosnLeAng 0 " valid value " 1001 " Reserved " 1023 " NotAvailable " ;
VAL_ 576 Spots7HozlPosnRiAng 0 " valid value " 1001 " Reserved " 1023 " NotAvailable " ;
VAL_ 576 Spots7Valid 0 " Invalid " 1 " Valid " ;
VAL_ 576 Spots7Typ 0 " Unknown  " 1 " Oncoming object " 2 " Preceding object " 3 " Reflective object " ;
VAL_ 576 Spots7Distance 0 " valid value " 511 " NotAvailable " ;
VAL_ 576 Spots7HozLeAngSpd 0 " Valid Values " ;
VAL_ 576 Spot7VertAng 0 " Valid Values " ;
VAL_ 576 Spots7TrackingInfo 0 " Not Tracking " 1 " Tracking " ;
VAL_ 576 Spots7VehObjClassn 0 " No Vehicle " 1 " Car " 2 " Truck " 3 " Bus " 4 " BikeOrMotoBike " 5 " Pedestrain " 6 " Mixed " 7 " Unknow " ;
VAL_ 576 RollingCounter_IFC_HCM7 0 " Valid value " 15 " Invalid value " ;
VAL_ 579 HUT_OD_Obj7_ID 0 " Valid values " 10 " Invalid values " ;
VAL_ 579 HUT_OD_Obj7_type 0 " No target " 1 " Pedestrian or Biker " 2 " Vehicle " 3 " Ground Locker or Barrier " 4 " Unknown type " 5 " Invalid values " ;
VAL_ 579 HUT_OD_Obj7_Confidence 0 " 0-1 " 11 " Invalid values " ;
VAL_ 579 HUT_OD_Obj7_width 0 " Valid values " 127 " Invalid values " ;
VAL_ 579 HUT_OD_Obj7_Ground_Pos_X 0 " Valid values " 4001 " Reserved " 4095 " Invalid values " ;
VAL_ 579 HUT_OD_Obj7_Ground_Pos_Y 0 " Valid values " 4001 " Reserved " 4095 " Invalid values " ;
VAL_ 579 HUT_OD_WorkSts 0 " OFF " 1 " FOD Active " 2 " ROD Active " 3 " Reserved " ;
VAL_ 579 HUT_OD_Obj_Timestamp 0 " Valid values " ;
VAL_ 579 HUT_FSD1_distance 0 " Valid values " 61 " Invalid values " ;
VAL_ 579 HUT_FSD2_distance 0 " Valid values " 61 " Invalid values " ;
VAL_ 579 HUT_FSD3_distance 0 " Valid values " 61 " Invalid values " ;
VAL_ 579 HUT_FSD4_distance 0 " Valid values " 61 " Invalid values " ;
VAL_ 579 HUT_FSD5_distance 0 " Valid values " 61 " Invalid values " ;
VAL_ 579 HUT_FSD6_distance 0 " Valid values " 61 " Invalid values " ;
VAL_ 579 HUT_FSD7_distance 0 " Valid values " 61 " Invalid values " ;
VAL_ 579 HUT_FSD8_distance 0 " Valid values " 61 " Invalid values " ;
VAL_ 579 HUT_FSD9_distance 0 " Valid values " 61 " Invalid values " ;
VAL_ 579 HUT_FSD10_distance 0 " Valid values " 61 " Invalid values " ;
VAL_ 579 HUT_FSD11_distance 0 " Valid values " 61 " Invalid values " ;
VAL_ 579 HUT_FSD12_distance 0 " Valid values " 61 " Invalid values " ;
VAL_ 579 HUT_FSD13_distance 0 " Valid values " 61 " Invalid values " ;
VAL_ 579 HUT_FSD14_distance 0 " Valid values " 61 " Invalid values " ;
VAL_ 579 HUT_FSD15_distance 0 " Valid values " 61 " Invalid values " ;
VAL_ 579 HUT_FSD16_distance 0 " Valid values " 61 " Invalid values " ;
VAL_ 579 HUT_FSD17_distance 0 " Valid values " 61 " Invalid values " ;
VAL_ 579 HUT_FSD18_distance 0 " Valid values " 61 " Invalid values " ;
VAL_ 579 NOH_Swt_Req 0 " OFF " 1 " ON " ;
VAL_ 579 NOH_Act_Req 0 " deactivate " 1 " activate " ;
VAL_ 581 CheckSum_ABM2 0 " Valid values " ;
VAL_ 581 VehLgtAccel 0 " Valid Value " 44067 " Reserved " ;
VAL_ 581 VehLatAccel 0 " Valid Value " 44067 " Reserved " ;
VAL_ 581 VehYawRate 0 " Valid Value " 17442 " Reserved " ;
VAL_ 581 VehLgtAccelVld 0 " Invalid " 1 " Valid " ;
VAL_ 581 VehLatAccelVld 0 " Invalid " 1 " Valid " ;
VAL_ 581 VehDynYawRateVld 0 " Invalid " 1 " Valid " ;
VAL_ 581 RollingCounter_ABM2 0 " Valid value " 15 " Invalid value " ;
VAL_ 584 HCU_RdyLmpSts 0 " OFF " 1 " ON " ;
VAL_ 586 HWP_EmgyLightReq 0 " Turn OFF " 1 " Turn ON " ;
VAL_ 586 HWP_TurnlLightReq 0 " Turn OFF " 1 " Turn Left ON " 2 " Turn Right ON " 3 " reserved " ;
VAL_ 586 HWP_HornReq 0 " Turn OFF " 1 " Turn ON " ;
VAL_ 586 HWP_DippedBeamReq 0 " Turn OFF " 1 " Turn ON " ;
VAL_ 586 HWP_HiBeamtReq 0 " Turn OFF " 1 " Turn ON " ;
VAL_ 586 HWP_FFogLightReq 0 " Turn OFF " 1 " Turn ON " ;
VAL_ 586 HWP_RFogLightReq 0 " Turn OFF " 1 " Turn  ON " ;
VAL_ 586 HWP_FWiperReq 0 " Wiper Off " 1 " Wiper Auto Or Intermittent " 2 " Low Speed " 3 " High Speed " 4 " reserved " 7 " Error " ;
VAL_ 586 HWP_RWshrReq 0 " OFF " 1 " ON " ;
VAL_ 586 HWP_BrkLmpReq 0 " Turn OFF " 1 " Turn  ON " ;
VAL_ 586 HWP_BackupReq 0 " Turn OFF " 1 " Turn  ON " ;
VAL_ 586 HWP_CenCtrllockReq 0 " Normal " 1 " lock " 2 " unlock " 3 " Reserved " ;
VAL_ 586 HWP_TrkReq 0 " Normal " 1 " open " 2 " close " 3 " Reserved " ;
VAL_ 586 HWP_AC_Req 0 " No demand " 1 " Demand " ;
VAL_ 586 HWP_TarWind 0 " No wind " 1 " Level 1 wind " 2 " Level 2 wind " 3 " Level 3 wind " ;
VAL_ 586 HWP_TarTemp 0 " Validvalue " ;
VAL_ 586 HWP_WorkReq_KBCM 0 " OFF " 1 " Standby " 2 " Ready " 3 " Active " 4 " Reserved " ;
VAL_ 586 HWP_WorkReqVld_KBCM 0 " Invalid " 1 " Valid " ;
VAL_ 586 HWP_TextWarn_AC 0 " No display " 1 " Take over request " 2 " Attention please " 3 " Handsoff alert " 4 " HWP need to restart the engine " 5 " Tunnel ahead " 6 " Road split ahead " 7 " Road merge ahead " 8 " Overtime for lane change " 9 " HWP control cancelled " 10 " Reserved " ;
VAL_ 589 Checksum_DMS2 0 " Valid values " ;
VAL_ 589 DistrctnLvl_ACC 0 " No distraction " 1 " Low level distraction " 2 " Middle level distraction " 3 " Hi level distraction " 4 " Reserved " 7 " Invalid " ;
VAL_ 589 DistrctnLvlQlty_ACC 0 " Valid value " 101 " Reserved " 127 " Invalid " ;
VAL_ 589 DrowsnsLvl_ACC 0 " No Drowsiness " 1 " Low level Drowsiness " 2 " Middle level Drowsiness " 3 " Hi level Drowsiness " 4 " Reserved " 7 " Invalid " ;
VAL_ 589 RollingCounter_DMS2 0 " Valid value " 15 " Invalid value " ;
VAL_ 589 Checksum_DMS3 0 " Valid values " ;
VAL_ 589 HeadPosnX 0 " Valid value " 1501 " Reserved " 2047 " Invalid " ;
VAL_ 589 HeadPosnY 0 " Valid value " 1001 " Reserved " 2047 " Invalid " ;
VAL_ 589 HeadPosnZ 0 " Valid value " 1001 " Reserved " 2047 " Invalid " ;
VAL_ 589 RollingCounter_DMS3 0 " Valid value " 15 " Invalid value " ;
VAL_ 589 Checksum_DMS5 0 " Valid values " ;
VAL_ 589 DMSSts 0 " Blindness " 1 " Error " 2 " Active " 3 " Not active " 4 " Reserved " 7 " Invalid " ;
VAL_ 589 HeadDetn 0 " No " 1 " Yes " ;
VAL_ 589 HeadYawAng 0 " Valid value " 151 " Reserved " 255 " Invalid " ;
VAL_ 589 HeadPitchAng 0 " Valid value " 71 " Reserved " 255 " Invalid " ;
VAL_ 589 HeadRollAng 0 " Valid value " 91 " Reserved " 255 " Invalid " ;
VAL_ 589 RollingCounter_DMS5 0 " Valid value " 15 " Invalid value " ;
VAL_ 589 Checksum_DMS6 0 " Valid values " ;
VAL_ 589 LEyeOpenSts 0 " No " 1 " Yes " 2 " Loss left eye " 3 " Invalid " ;
VAL_ 589 LEyeOpenStsQlty 0 " Valid value " 101 " Reserved " 127 " Invalid " ;
VAL_ 589 REyeOpenSts 0 " No " 1 " Yes " 2 " Loss right eye " 3 " Invalid " ;
VAL_ 589 REyeOpenStsQlty 0 " Valid value " 101 " Reserved " 127 " Invalid " ;
VAL_ 589 RobustGazeYawAng 0 " Valid value " 181 " Reserved " 255 " Invalid " ;
VAL_ 589 RobustGazePitchAng 0 " Valid value " 181 " Reserved " 255 " Invalid " ;
VAL_ 589 RollingCounter_DMS6 0 " Valid value " 15 " Invalid value " ;
VAL_ 604 Checksum_BLE1 0 " Valid value " ;
VAL_ 604 PrkOutVehStrtReq_Rmt 0 " No request " 1 " Request " ;
VAL_ 604 ParkAbortReq_Rmt 0 " No request " 1 " Request " ;
VAL_ 604 PrkOutModSel_Rmt 0 " No select " 1 " Front vertical head park out " 2 " Rear vertical tail park out " 3 " Left parallel left park out  " 4 " Right parallel right park out " 5 " Summon path one park out " 6 " Summon path two park out " 7 " Reserved " ;
VAL_ 604 BLEConnSts 0 " Initial value " 1 " Not connection " 2 " Connection " 3 " Reserved " ;
VAL_ 604 PrkOutTypeReq_Rmt 0 " No select " 1 " Parallel park out " 2 " Vertical park out " 3 " Intelligent Summon " ;
VAL_ 604 PrkgSyncStrtReq_Rmt 0 " No request " 1 " Request " ;
VAL_ 604 PrkOutVehStrtReq_Rmt_Valid 0 " Invalid " 1 " Valid " ;
VAL_ 604 PrkgslidReq_Rmt 0 " User not sliding circle " 1 " User sliding circle " ;
VAL_ 604 BLESecuritySts 0 " Initial value " 1 " Not in Security certification status " 2 " In security certification status " 3 " Reserved " ;
VAL_ 604 RollingCounter_BLE1 0 " Valid value " 15 " Invalid value " ;
VAL_ 623 CheckSum_HUT32 0 " Valid value " ;
VAL_ 623 P2P_PrkgDirSwtReq 0 " No request  " 1 " Request " ;
VAL_ 623 ScrnOpSts 0 " Release " 1 " Pressed " 2 " Hold " 3 " Reserved " ;
VAL_ 623 XLvl 0 " Valid value " 2047 " Invalid " ;
VAL_ 623 YLvl 0 " Valid value " 2047 " Invalid " ;
VAL_ 623 DetVideoLost 0 " Nomal " 1 " Video lost " ;
VAL_ 623 PrkgCtrlModReqValid 0 " valid " 1 " invalid " ;
VAL_ 623 PrkgCtrlModReq 0 " No action " 1 " Parking in car " 2 " Remote parking " 3 " Remote searching slot " ;
VAL_ 623 ContnPrkgReqValid 0 " valid " 1 " invalid " ;
VAL_ 623 ContnPrkgReq 0 " 0x1 select continue parking " 2 " cancle parking " 3 " invalid " ;
VAL_ 623 PrkStraightSwtReq_HUT 0 " No request " 1 " Request " ;
VAL_ 623 PrkStraightSuspendOrFinishReq_HU 0 " No request " 1 " Request suspend " 2 " Request finish " 3 " Reserved " ;
VAL_ 623 PrkStraightModSel_HUT 0 " No select " 1 " Front vertical head park straight " 2 " Rear vertical tail park straight " 3 " Reserved " ;
VAL_ 623 PrkStraightSts_HUT 0 " No error " 1 " Error " ;
VAL_ 623 PrkStraightStrtReq_HUT 0 " No request " 1 " Request " ;
VAL_ 623 PrkStraightVehStrtReq_HUT_Valid 0 " Invalid " 1 " Valid " ;
VAL_ 623 PrkStraightContinueReq_HUT 0 " User not continue request  " 1 " User continue request " ;
VAL_ 623 RollingCounter_HUT32 0 " Valid value " 15 " Invalid value " ;
VAL_ 628 AutoAVMSwtSet_Sts 0 " Off " 1 " ON " ;
VAL_ 628 AVM_CurrSts 0 " Off " 1 " ON " 2 " AVM no video（雷达模式） " 3 " Reserved " ;
VAL_ 628 GuidOvlSts 0 " Around View and Single View " 1 " Only Around View  " 2 " Only Single View  " 3 " No Guidance  " ;
VAL_ 628 FrntCamInpFailSts 0 " no failure " 1 " failure " ;
VAL_ 628 RearCamInpFailSts 0 " no failure " 1 " failure " ;
VAL_ 628 LeCamInpFailSts 0 " no failure " 1 " failure " ;
VAL_ 628 RiCamInpFailSts 0 " no failure " 1 " failure " ;
VAL_ 628 EolNotCmpltd 0 " Ccompleted " 1 " No completed " ;
VAL_ 628 OvlOpFailSts 0 " no failure " 1 " failure " ;
VAL_ 628 LaneCalSts 0 " No Commands " 1 " In Calibration process " 2 " Calibration success " 3 " Calibration failure " ;
VAL_ 628 RadarDispSts 0 " Both Around View and Single View Radar Display " 1 " Only Around View Radar Display " 2 " Only Single View Radar Display " 3 " No Radar Display " ;
VAL_ 628 LaneCalFltSts 0 " No fault " 1 " Front view Calibration abnormal " 2 " Rear view Calibration abnormal " 3 " left view Calibration abnormal " 4 " Right view Calibration abnormal " 5 " Calibration data storage failed " 6 " Reserved " ;
VAL_ 628 AutoViewChgFuncSts 0 " Off " 1 " ON " ;
VAL_ 628 CarMdlTrsprcySts 0 " Opaque " 1 " Translucent " 2 " Completely transparent " 3 " Reserved " ;
VAL_ 628 CarMdlDispSts 0 " 2D mode " 1 " 3D mode " ;
VAL_ 628 CurrCalResultSts 0 " Use Factory Calibration Result " 1 " Use Lane Calibration Result " ;
VAL_ 628 MdlColrSts 0 " Silvery " 1 " Red " 2 " Gray " 3 " White " 4 " Black " 5 " Brown " 6 " Blue " 7 " Orange " 8 " Green " 9 " Gold " 10 " Purple " 11 " Reserved " ;
VAL_ 628 SigViewIndcn 0 " No Commands " 1 " Front to Center View " 2 " Rear to Center View  " 3 " Left to Center View " 4 " Right to Center View " 5 " Left Front to Center View " 6 " Right Front to Center View " 7 " Left Rear to Center View " 8 " Right Rear to Center View " 9 " Front View " 10 " Rear View " 11 " Left View " 12 " Right View " 13 " Left Turn 3D View " 14 " Right Turn 3D View " 15 " Front Overlook View " 16 " Rear Overlook View " 17 " Front 180 Deg View " 18 " Rear 180 Deg View " 19 " Front Wheel View " 20 " Rear Wheel View " 21 " Front Wash View " 22 " Rear Wash View " 23 " Free_3D View " 24 " LeftRight View " 25 " Engine Room View " 26 " CCO View " 27 " Reserved " 63 " 3D Car Model Round View " ;
VAL_ 628 HAP_DispCmd 0 " OFF " 1 " ON " ;
VAL_ 628 AVM_3DAngSts 0 " Not active " 1 " 0~360° " 362 " reserved " 511 " invalid " ;
VAL_ 628 MOD_WorkSts 0 " OFF " 1 " ON " ;
VAL_ 628 MOD_AlarmSts 0 " OFF " 1 " ON " ;
VAL_ 628 DVRWorkSts 0 " DVR_Standby " 1 " DVR_Active " 2 " DVR_InterFailed " 3 " DVR_NetFailed " ;
VAL_ 628 HAP_Hmi_Index 0 " Reserved " 1 " Main Screen " 2 " EOL/Test " 3 " P2P Screen " 4 " Assist Screen " 5 " HAVP Screen " 6 " PAVP Screen " 7 " Reserved " ;
